VERSION ""

NS_ :

BS_:

BU_: BCMB_AUXM SCMB_PSM HVAC_RCCM SOBDMD_AHCM_FOH TRM GWM _delete RTM PDM SCMH SCMG RSM DDM RGTM DSM GENERIC TSTR

BO_ 798 GatewayData5_MS1: 8 GWM
 SG_ ClrExitAsst_D_Stat_UB : 40|1@0+ (1,0) [0|1] "unitless"  BCMB_AUXM
 SG_ ClrExitAsst_D_Stat : 63|2@0+ (1,0) [0|3] "SED"  BCMB_AUXM
 SG_ ClrExitAsstMsgTxt2_D_Rq_UB : 48|1@0+ (1,0) [0|1] "unitless"  BCMB_AUXM
 SG_ ClrExitAsstMsgTxt2_D_Rq : 52|4@0+ (1,0) [0|15] "SED"  BCMB_AUXM
 SG_ EmPrflNo_D_Rq_UB : 46|1@0+ (1,0) [0|1] "SED"  DDM
 SG_ EmPrflNo_D_Rq : 34|3@0+ (1,0) [0|7] "SED"  DDM
 SG_ EmPrflKeyAssoc_D_Rq_UB : 47|1@0+ (1,0) [0|1] "SED"  DDM
 SG_ EmPrflKeyAssoc_D_Rq : 37|3@0+ (1,0) [0|7] "SED"  DDM
 SG_ BattTracDrvSustn_B_Rq_UB : 42|1@0+ (1,0) [0|1] "SED"  HVAC_RCCM
 SG_ BattTracCool_B_Actl_UB : 44|1@0+ (1,0) [0|1] "SED"  HVAC_RCCM
 SG_ BattTracCool_B_Actl : 45|1@0+ (1,0) [0|1] "SED"  HVAC_RCCM
 SG_ BattTracDrvSustn_B_Rq : 43|1@0+ (1,0) [0|1] "SED"  HVAC_RCCM
 SG_ ExitNotClrRight_B_Stat_UB : 38|1@0+ (1,0) [0|1] "SED" Vector__XXX
 SG_ ExitNotClrLeft_B_Stat_UB : 39|1@0+ (1,0) [0|1] "SED" Vector__XXX
 SG_ ExitNotClrRight_B_Stat : 24|1@0+ (1,0) [0|1] "SED" Vector__XXX
 SG_ ExitNotClrLeft_B_Stat : 25|1@0+ (1,0) [0|1] "SED" Vector__XXX
 SG_ ClimtCool_D_RqPt_UB : 16|1@0+ (1,0) [0|1] "SED"  HVAC_RCCM
 SG_ ClimtCool_D_RqPt : 27|2@0+ (1,0) [0|3] "SED"  HVAC_RCCM
 SG_ PudSptLghtRight_D_Rq_UB : 2|1@0+ (1,0) [0|1] "SED"  DDM,PDM
 SG_ PudSptLghtLeft_D_Rq_UB : 3|1@0+ (1,0) [0|1] "SED"  DDM,PDM
 SG_ PudSptLghtRight_D_Rq : 5|2@0+ (1,0) [0|3] "SED"  DDM,PDM
 SG_ PwRnngBoardPoll_D_Stat_UB : 20|1@0+ (1,0) [0|1] "SED"  DDM,PDM
 SG_ PwRnngBoardPoll_D_Stat : 22|2@0+ (1,0) [0|3] "SED"  DDM,PDM
 SG_ AirCondRec_B_RqVehEl_UB : 18|1@0+ (1,0) [0|1] "SED"  HVAC_RCCM
 SG_ AirCondRec_B_RqVehEl : 19|1@0+ (1,0) [0|1] "SED"  HVAC_RCCM
 SG_ RmtCtl_D_Stat : 31|4@0+ (1,0) [0|15] "SED"  DDM,PDM
 SG_ RmtCtl_D_Stat_UB : 17|1@0+ (1,0) [0|1] "SED"  DDM,PDM
 SG_ PudSptLghtLeft_D_Rq : 7|2@0+ (1,0) [0|3] "SED"  DDM,PDM
 SG_ PoliceDmngLvl_D_Stat : 10|3@0+ (1,0) [0|7] "SED"  DDM,HVAC_RCCM,PDM
 SG_ VehWlcmFrwlMde_D_Stat_UB : 11|1@0+ (1,0) [0|1] "SED"  BCMB_AUXM,DDM,PDM
 SG_ VehWlcmFrwl_D_Stat_UB : 12|1@0+ (1,0) [0|1] "SED"  BCMB_AUXM,DDM,PDM
 SG_ VehWlcmFrwlMde_D_Stat : 15|3@0+ (1,0) [0|7] "SED"  BCMB_AUXM,DDM,PDM
 SG_ VehWlcmFrwl_D_Stat : 1|2@0+ (1,0) [0|3] "SED"  BCMB_AUXM,DDM,PDM
 SG_ PoliceDmngLvl_D_Stat_UB : 23|1@0+ (1,0) [0|1] "SED"  DDM,HVAC_RCCM,PDM

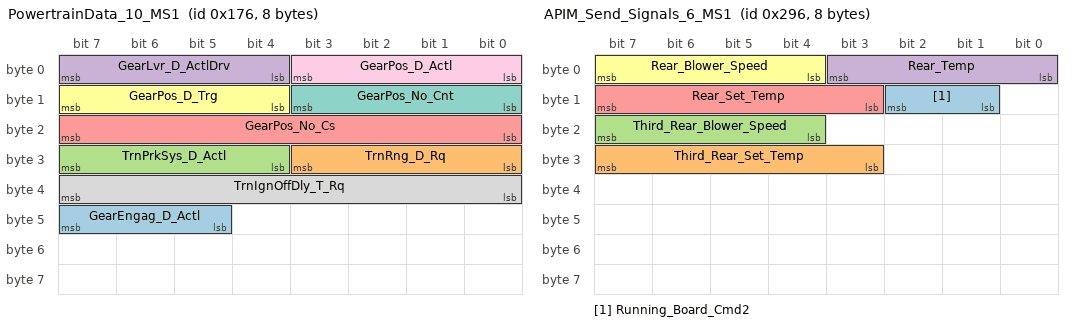
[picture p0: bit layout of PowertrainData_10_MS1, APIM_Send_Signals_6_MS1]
BO_ 374 PowertrainData_10_MS1: 8 GWM
 SG_ GearEngag_D_Actl : 47|3@0+ (1,0) [0|7] "SED"  GENERIC
 SG_ TrnRng_D_Rq : 27|4@0+ (1,0) [0|15] "SED" Vector__XXX
 SG_ TrnPrkSys_D_Actl : 31|4@0+ (1,0) [0|15] "SED" Vector__XXX
 SG_ GearLvr_D_ActlDrv : 7|4@0+ (1,0) [0|15] "SED" Vector__XXX
 SG_ GearPos_No_Cs : 23|8@0+ (1,0) [0|255] "unitless" Vector__XXX
 SG_ GearPos_D_Trg : 15|4@0+ (1,0) [0|15] "SED" Vector__XXX
 SG_ GearPos_No_Cnt : 11|4@0+ (1,0) [0|15] "unitless" Vector__XXX
 SG_ TrnIgnOffDly_T_Rq : 39|8@0+ (4,0) [0|1020] "ms"  GENERIC
 SG_ GearPos_D_Actl : 3|4@0+ (1,0) [0|15] "SED" Vector__XXX

BO_ 662 APIM_Send_Signals_6_MS1: 8 GWM
 SG_ Running_Board_Cmd2 : 10|2@0+ (1,0) [0|3] "SED" Vector__XXX
 SG_ Third_Rear_Set_Temp : 31|5@0+ (1,0) [0|31] "SED" Vector__XXX
 SG_ Third_Rear_Blower_Speed : 23|4@0+ (1,0) [0|15] "SED" Vector__XXX
 SG_ Rear_Temp : 3|4@0+ (1,0) [0|15] "SED" Vector__XXX
 SG_ Rear_Set_Temp : 15|5@0+ (1,0) [0|31] "SED" Vector__XXX
 SG_ Rear_Blower_Speed : 7|4@0+ (1,0) [0|15] "SED" Vector__XXX

BO_ 670 Driver_Dr_Stat2: 8 DDM
 SG_ DrHandleOuterRl_D_Stat : 4|3@0+ (1,0) [0|7] "SED"  GWM
 SG_ DrHandleOuterFl_D_Stat : 7|3@0+ (1,0) [0|7] "SED"  GWM

BO_ 669 Pass_Dr_Stat2: 8 PDM
 SG_ DrHandleOuterRr_D_Stat : 4|3@0+ (1,0) [0|7] "SED"  GWM
 SG_ DrHandleOuterFr_D_Stat : 7|3@0+ (1,0) [0|7] "SED"  GWM

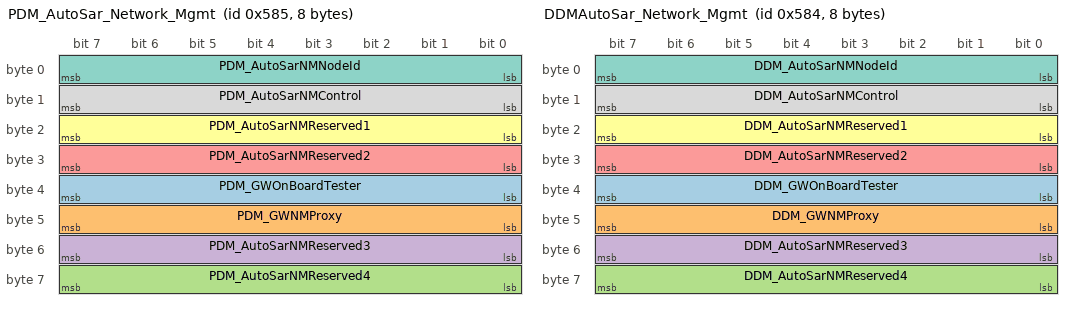
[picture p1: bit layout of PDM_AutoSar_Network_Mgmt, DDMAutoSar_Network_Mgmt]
BO_ 1413 PDM_AutoSar_Network_Mgmt: 8 PDM
 SG_ PDM_GWOnBoardTester : 39|8@0+ (1,0) [0|255] "unitless"  GWM
 SG_ PDM_GWNMProxy : 47|8@0+ (1,0) [0|255] "unitless"  GWM
 SG_ PDM_AutoSarNMReserved4 : 63|8@0+ (1,0) [0|255] "unitless"  GWM
 SG_ PDM_AutoSarNMReserved3 : 55|8@0+ (1,0) [0|255] "unitless"  GWM
 SG_ PDM_AutoSarNMReserved2 : 31|8@0+ (1,0) [0|255] "unitless"  GWM
 SG_ PDM_AutoSarNMReserved1 : 23|8@0+ (1,0) [0|255] "unitless"  GWM
 SG_ PDM_AutoSarNMNodeId : 7|8@0+ (1,0) [0|255] "unitless"  GWM
 SG_ PDM_AutoSarNMControl : 15|8@0+ (1,0) [0|255] "unitless"  GWM

BO_ 1412 DDMAutoSar_Network_Mgmt: 8 DDM
 SG_ DDM_GWOnBoardTester : 39|8@0+ (1,0) [0|255] "unitless"  GWM
 SG_ DDM_GWNMProxy : 47|8@0+ (1,0) [0|255] "unitless"  GWM
 SG_ DDM_AutoSarNMReserved4 : 63|8@0+ (1,0) [0|255] "unitless"  GWM
 SG_ DDM_AutoSarNMReserved3 : 55|8@0+ (1,0) [0|255] "unitless"  GWM
 SG_ DDM_AutoSarNMReserved2 : 31|8@0+ (1,0) [0|255] "unitless"  GWM
 SG_ DDM_AutoSarNMReserved1 : 23|8@0+ (1,0) [0|255] "unitless"  GWM
 SG_ DDM_AutoSarNMNodeId : 7|8@0+ (1,0) [0|255] "unitless"  GWM
 SG_ DDM_AutoSarNMControl : 15|8@0+ (1,0) [0|255] "unitless"  GWM

BO_ 1079 GatewayData2_MS1: 8 GWM
 SG_ ApaMde_D_Stat_UB : 25|1@0+ (1,0) [0|1] "SED" Vector__XXX
 SG_ ApaMde_D_Stat : 39|3@0+ (1,0) [0|7] "SED" Vector__XXX
 SG_ TrlrAidEnbl_D2_Stat_UB : 58|1@0+ (1,0) [0|1] "SED" Vector__XXX
 SG_ TrlrAidEnbl_D2_Stat : 61|3@0+ (1,0) [0|7] "SED" Vector__XXX
 SG_ PoliceAux4Swtch_B_Stat_UB : 62|1@0+ (1,0) [0|1] "SED" Vector__XXX
 SG_ PoliceAux3Swtch_B_Stat_UB : 63|1@0+ (1,0) [0|1] "SED" Vector__XXX
 SG_ PoliceAux2Swtch_B_Stat_UB : 48|1@0+ (1,0) [0|1] "SED" Vector__XXX
 SG_ PoliceAux1Swtch_B_Stat_UB : 49|1@0+ (1,0) [0|1] "SED" Vector__XXX
 SG_ PoliceAux4Swtch_B_Stat : 50|1@0+ (1,0) [0|1] "SED" Vector__XXX
 SG_ PoliceAux3Swtch_B_Stat : 51|1@0+ (1,0) [0|1] "SED" Vector__XXX
 SG_ PoliceAux2Swtch_B_Stat : 52|1@0+ (1,0) [0|1] "SED" Vector__XXX
 SG_ PoliceAux1Swtch_B_Stat : 40|1@0+ (1,0) [0|1] "SED" Vector__XXX
 SG_ GenericSwtch3_No_Actl_UB : 41|1@0+ (1,0) [0|1] "SED" Vector__XXX
 SG_ GenericSwtch3_No_Actl : 55|3@0+ (1,0) [0|7] "unitless" Vector__XXX
 SG_ GenericSwtch2_No_Actl_UB : 32|1@0+ (1,0) [0|1] "SED" Vector__XXX
 SG_ GenericSwtch2_No_Actl : 44|3@0+ (1,0) [0|7] "unitless" Vector__XXX
 SG_ GenericSwtch1_No_Actl_UB : 33|1@0+ (1,0) [0|1] "SED" Vector__XXX
 SG_ GenericSwtch1_No_Actl : 47|3@0+ (1,0) [0|7] "unitless" Vector__XXX
 SG_ RbaSys_D_Stat_UB : 8|1@0+ (1,0) [0|1] "SED" Vector__XXX
 SG_ RbaSys_D_Stat : 4|2@0+ (1,0) [0|3] "SED" Vector__XXX
 SG_ HybMdeStat_D_Dsply_UB : 9|1@0+ (1,0) [0|1] "SED"  HVAC_RCCM
 SG_ Rba_D_Stat : 12|2@0+ (1,0) [0|3] "SED" Vector__XXX
 SG_ Rba_D_Stat_UB : 10|1@0+ (1,0) [0|1] "SED" Vector__XXX
 SG_ BalrMde_D_Rq_UB : 20|1@0+ (1,0) [0|1] "SED" Vector__XXX
 SG_ BalrSwtch_D_Stat_UB : 17|1@0+ (1,0) [0|1] "SED" Vector__XXX
 SG_ BalrMde_D_Rq : 22|2@0+ (1,0) [0|3] "SED" Vector__XXX
 SG_ ChrgGoTTouchEnbl_B_Rq : 1|1@0+ (1,0) [0|1] "SED"  HVAC_RCCM
 SG_ ChrgGoTExtHtrEnbl_B_Rq : 2|1@0+ (1,0) [0|1] "SED"  HVAC_RCCM
 SG_ ChrgGoTTouchEnbl_B_Rq_UB : 23|1@0+ (1,0) [0|1] "SED"  HVAC_RCCM
 SG_ ChrgGoTExtHtrEnbl_B_Rq_UB : 0|1@0+ (1,0) [0|1] "SED"  HVAC_RCCM
 SG_ LcwaAlrtRight_B_Rq_UB : 34|1@0+ (1,0) [0|1] "SED" Vector__XXX
 SG_ LcwaAlrtLeft_B_Rq_UB : 36|1@0+ (1,0) [0|1] "SED" Vector__XXX
 SG_ LcwaAlrtRight_B_Rq : 35|1@0+ (1,0) [0|1] "SED" Vector__XXX
 SG_ LcwaAlrtLeft_B_Rq : 24|1@0+ (1,0) [0|1] "SED" Vector__XXX
 SG_ ApaSteScanMde_D_Stat : 15|2@0+ (1,0) [0|3] "SED" Vector__XXX
 SG_ ApaSteScanMde_D_Stat_UB : 13|1@0+ (1,0) [0|1] "SED" Vector__XXX
 SG_ BattTracClimtDis_B_Stat_UB : 56|1@0+ (1,0) [0|1] "SED"  HVAC_RCCM
 SG_ BattTracClimtDis_B_Stat : 57|1@0+ (1,0) [0|1] "SED"  HVAC_RCCM
 SG_ BalrSwtch_D_Stat : 19|2@0+ (1,0) [0|3] "SED" Vector__XXX
 SG_ TrlrAidMsgTxt_D2_Rq_UB : 16|1@0+ (1,0) [0|1] "SED" Vector__XXX
 SG_ TrlrAidMsgTxt_D2_Rq : 31|6@0+ (1,0) [0|63] "SED" Vector__XXX
 SG_ HybMdeStat_D_Dsply : 7|3@0+ (1,0) [0|7] "SED"  HVAC_RCCM

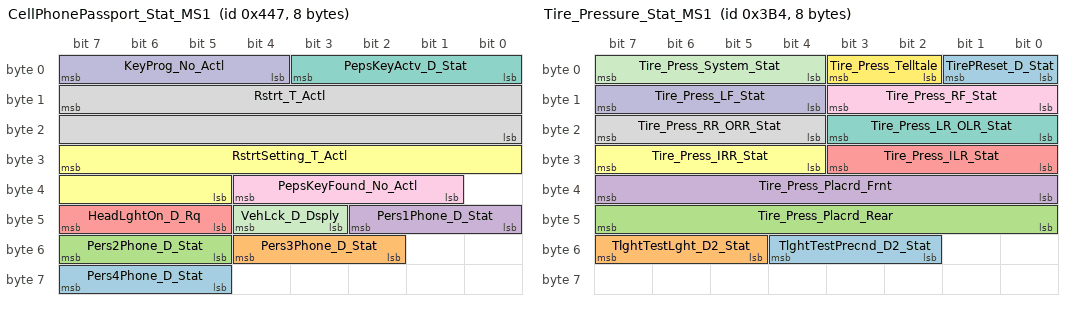
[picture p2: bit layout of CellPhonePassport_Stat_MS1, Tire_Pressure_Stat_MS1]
BO_ 1095 CellPhonePassport_Stat_MS1: 8 GWM
 SG_ Pers4Phone_D_Stat : 63|3@0+ (1,0) [0|7] "SED"  GENERIC
 SG_ Pers3Phone_D_Stat : 52|3@0+ (1,0) [0|7] "SED"  GENERIC
 SG_ Pers2Phone_D_Stat : 55|3@0+ (1,0) [0|7] "SED"  GENERIC
 SG_ Pers1Phone_D_Stat : 42|3@0+ (1,0) [0|7] "SED"  GENERIC
 SG_ HeadLghtOn_D_Rq : 47|3@0+ (1,0) [0|7] "SED" Vector__XXX
 SG_ RstrtSetting_T_Actl : 31|11@0+ (1,0) [0|2047] "second"  RSM
 SG_ PepsKeyActv_D_Stat : 3|4@0+ (1,0) [0|15] "SED"  GENERIC
 SG_ Rstrt_T_Actl : 15|16@0+ (1,0) [0|65535] "seconds"  RSM
 SG_ PepsKeyFound_No_Actl : 36|4@0+ (1,0) [0|15] "unitless"  GENERIC
 SG_ KeyProg_No_Actl : 7|4@0+ (1,0) [0|15] "unitless"  GENERIC
 SG_ VehLck_D_Dsply : 44|2@0+ (1,0) [0|3] "SED" Vector__XXX

BO_ 948 Tire_Pressure_Stat_MS1: 8 GWM
 SG_ TlghtTestPrecnd_D2_Stat : 52|3@0+ (1,0) [0|7] "SED"  GENERIC
 SG_ TlghtTestLght_D2_Stat : 55|3@0+ (1,0) [0|7] "SED"  GENERIC
 SG_ Tire_Press_Placrd_Rear : 47|8@0+ (1,0) [0|255] "pounds/inch^2"  GENERIC
 SG_ Tire_Press_Placrd_Frnt : 39|8@0+ (1,0) [0|255] "pounds/inch^2"  GENERIC
 SG_ Tire_Press_ILR_Stat : 27|4@0+ (1,0) [0|15] "SED"  RTM
 SG_ Tire_Press_IRR_Stat : 31|4@0+ (1,0) [0|15] "SED"  RTM
 SG_ Tire_Press_LR_OLR_Stat : 19|4@0+ (1,0) [0|15] "SED"  RTM
 SG_ Tire_Press_RR_ORR_Stat : 23|4@0+ (1,0) [0|15] "SED"  RTM
 SG_ Tire_Press_RF_Stat : 11|4@0+ (1,0) [0|15] "SED"  RTM
 SG_ Tire_Press_LF_Stat : 15|4@0+ (1,0) [0|15] "SED"  RTM
 SG_ Tire_Press_System_Stat : 7|4@0+ (1,0) [0|15] "SED"  RTM
 SG_ Tire_Press_Telltale : 3|2@0+ (1,0) [0|3] "SED"  RTM
 SG_ TirePReset_D_Stat : 1|2@0+ (1,0) [0|3] "Discrete"  RTM

BO_ 840 FoH_Day_Req_MS1: 8 GWM
 SG_ FohAddHeater_D_Rq : 9|2@0+ (1,0) [0|3] "SED"  SOBDMD_AHCM_FOH
 SG_ FohStrtDateYr_No_Rq : 39|8@0+ (1,2000) [2000|2255] "year"  SOBDMD_AHCM_FOH
 SG_ FohStrtDateDay_No_Rq : 23|16@0+ (1,0) [0|65535] "julian day"  SOBDMD_AHCM_FOH
 SG_ FohT2Friday_T_Rq : 0|1@0+ (1,0) [0|1] "SED"  SOBDMD_AHCM_FOH
 SG_ FohT1Friday_T_Rq : 7|1@0+ (1,0) [0|1] "SED"  SOBDMD_AHCM_FOH
 SG_ FohT2Wednesday_T_Rq : 10|1@0+ (1,0) [0|1] "SED"  SOBDMD_AHCM_FOH
 SG_ FohT2Tuesday_T_Rq : 11|1@0+ (1,0) [0|1] "SED"  SOBDMD_AHCM_FOH
 SG_ FohT2Thursday_T_Rq : 12|1@0+ (1,0) [0|1] "SED"  SOBDMD_AHCM_FOH
 SG_ FohT2Sunday_T_Rq : 13|1@0+ (1,0) [0|1] "SED"  SOBDMD_AHCM_FOH
 SG_ FohT2Saturday_T_Rq : 14|1@0+ (1,0) [0|1] "SED"  SOBDMD_AHCM_FOH
 SG_ FohT2Monday_T_Rq : 15|1@0+ (1,0) [0|1] "SED"  SOBDMD_AHCM_FOH
 SG_ FohT1Wednesday_T_Rq : 1|1@0+ (1,0) [0|1] "SED"  SOBDMD_AHCM_FOH
 SG_ FohT1Tuesday_T_Rq : 2|1@0+ (1,0) [0|1] "SED"  SOBDMD_AHCM_FOH
 SG_ FohT1Thursday_T_Rq : 3|1@0+ (1,0) [0|1] "SED"  SOBDMD_AHCM_FOH
 SG_ FohT1Sunday_T_Rq : 4|1@0+ (1,0) [0|1] "SED"  SOBDMD_AHCM_FOH
 SG_ FohT1Saturday_T_Rq : 5|1@0+ (1,0) [0|1] "SED"  SOBDMD_AHCM_FOH
 SG_ FohT1Monday_T_Rq : 6|1@0+ (1,0) [0|1] "SED"  SOBDMD_AHCM_FOH

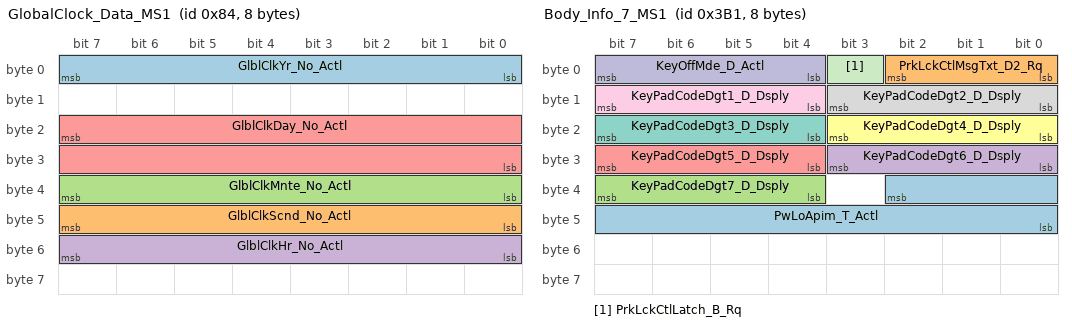
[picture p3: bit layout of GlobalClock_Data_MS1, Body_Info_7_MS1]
BO_ 132 GlobalClock_Data_MS1: 8 GWM
 SG_ GlblClkYr_No_Actl : 7|8@0+ (1,2000) [2000|2255] "year"  TRM,SOBDMD_AHCM_FOH
 SG_ GlblClkScnd_No_Actl : 47|8@0+ (1,0) [0|255] "second"  TRM,SOBDMD_AHCM_FOH
 SG_ GlblClkMnte_No_Actl : 39|8@0+ (1,0) [0|255] "minute"  TRM,SOBDMD_AHCM_FOH
 SG_ GlblClkHr_No_Actl : 55|8@0+ (1,0) [0|255] "hour"  TRM,SOBDMD_AHCM_FOH
 SG_ GlblClkDay_No_Actl : 23|16@0+ (1,0) [0|65535] "julian day"  TRM,SOBDMD_AHCM_FOH

BO_ 945 Body_Info_7_MS1: 8 GWM
 SG_ PwLoApim_T_Actl : 34|11@0+ (1,0) [0|2047] "minute"  GENERIC
 SG_ PrkLckCtlMsgTxt_D2_Rq : 2|3@0+ (1,0) [0|7] "SED"  GENERIC
 SG_ KeyPadCodeDgt7_D_Dsply : 39|4@0+ (1,0) [0|15] "SED"  GENERIC
 SG_ KeyPadCodeDgt6_D_Dsply : 27|4@0+ (1,0) [0|15] "SED"  GENERIC
 SG_ KeyPadCodeDgt5_D_Dsply : 31|4@0+ (1,0) [0|15] "SED"  GENERIC
 SG_ KeyPadCodeDgt4_D_Dsply : 19|4@0+ (1,0) [0|15] "SED"  GENERIC
 SG_ KeyPadCodeDgt3_D_Dsply : 23|4@0+ (1,0) [0|15] "SED"  GENERIC
 SG_ KeyPadCodeDgt2_D_Dsply : 11|4@0+ (1,0) [0|15] "SED"  GENERIC
 SG_ KeyPadCodeDgt1_D_Dsply : 15|4@0+ (1,0) [0|15] "SED"  GENERIC
 SG_ KeyOffMde_D_Actl : 7|4@0+ (1,0) [0|15] "SED"  TRM,SCMB_PSM,PDM,RTM,DDM,DSM,HVAC_RCCM,RGTM
 SG_ PrkLckCtlLatch_B_Rq : 3|1@0+ (1,0) [0|1] "SED"  GENERIC

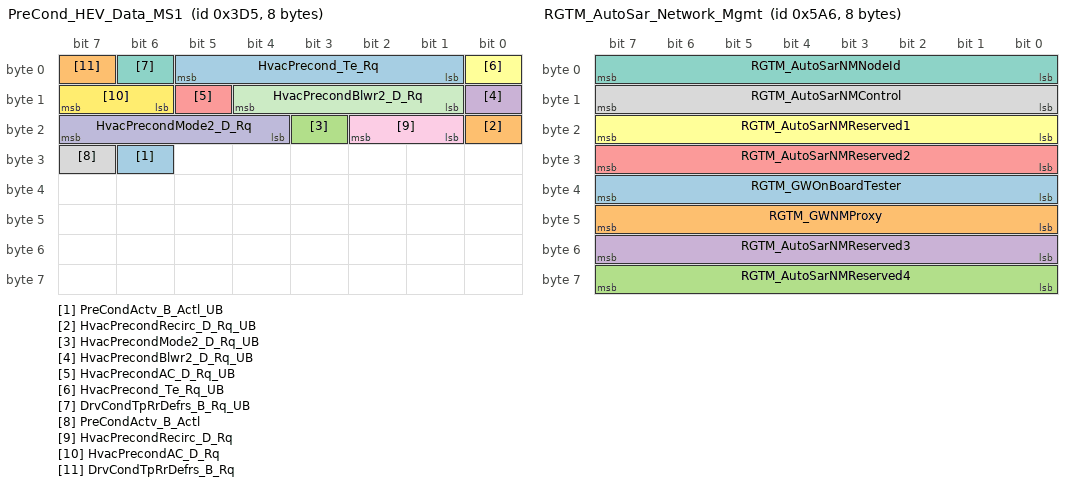
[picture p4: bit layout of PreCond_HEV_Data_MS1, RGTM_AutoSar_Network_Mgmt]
BO_ 981 PreCond_HEV_Data_MS1: 8 GWM
 SG_ PreCondActv_B_Actl_UB : 30|1@0+ (1,0) [0|1] "SED"  HVAC_RCCM,GENERIC
 SG_ HvacPrecondRecirc_D_Rq_UB : 16|1@0+ (1,0) [0|1] "SED"  GENERIC,HVAC_RCCM
 SG_ HvacPrecondMode2_D_Rq_UB : 19|1@0+ (1,0) [0|1] "SED"  GENERIC,HVAC_RCCM
 SG_ HvacPrecondBlwr2_D_Rq_UB : 8|1@0+ (1,0) [0|1] "SED"  HVAC_RCCM,GENERIC
 SG_ HvacPrecondAC_D_Rq_UB : 13|1@0+ (1,0) [0|1] "SED"  GENERIC,HVAC_RCCM
 SG_ HvacPrecond_Te_Rq_UB : 0|1@0+ (1,0) [0|1] "SED"  GENERIC,HVAC_RCCM
 SG_ DrvCondTpRrDefrs_B_Rq_UB : 6|1@0+ (1,0) [0|1] "SED"  HVAC_RCCM,GENERIC
 SG_ PreCondActv_B_Actl : 31|1@0+ (1,0) [0|1] "SED"  GENERIC,HVAC_RCCM
 SG_ HvacPrecondRecirc_D_Rq : 18|2@0+ (1,0) [0|3] "SED"  GENERIC,HVAC_RCCM
 SG_ HvacPrecondMode2_D_Rq : 23|4@0+ (1,0) [0|15] "SED"  GENERIC,HVAC_RCCM
 SG_ HvacPrecondBlwr2_D_Rq : 12|4@0+ (1,0) [0|15] "SED"  GENERIC,HVAC_RCCM
 SG_ HvacPrecondAC_D_Rq : 15|2@0+ (1,0) [0|3] "SED"  GENERIC,HVAC_RCCM
 SG_ HvacPrecond_Te_Rq : 5|5@0+ (0.5,14.5) [14.5|30] "deg C"  GENERIC,HVAC_RCCM
 SG_ DrvCondTpRrDefrs_B_Rq : 7|1@0+ (1,0) [0|1] "SED"  HVAC_RCCM,GENERIC

BO_ 1446 RGTM_AutoSar_Network_Mgmt: 8 RGTM
 SG_ RGTM_GWOnBoardTester : 39|8@0+ (1,0) [0|255] "unitless"  DDM,GWM
 SG_ RGTM_GWNMProxy : 47|8@0+ (1,0) [0|255] "unitless"  DDM,GWM
 SG_ RGTM_AutoSarNMReserved4 : 63|8@0+ (1,0) [0|255] "unitless"  DDM,GWM
 SG_ RGTM_AutoSarNMReserved3 : 55|8@0+ (1,0) [0|255] "unitless"  DDM,GWM
 SG_ RGTM_AutoSarNMReserved2 : 31|8@0+ (1,0) [0|255] "unitless"  DDM,GWM
 SG_ RGTM_AutoSarNMReserved1 : 23|8@0+ (1,0) [0|255] "unitless"  DDM,GWM
 SG_ RGTM_AutoSarNMNodeId : 7|8@0+ (1,0) [0|255] "unitless"  DDM,GWM
 SG_ RGTM_AutoSarNMControl : 15|8@0+ (1,0) [0|255] "unitless"  DDM,GWM

BO_ 839 FuelOpHeater_Stat: 8 SOBDMD_AHCM_FOH
 SG_ FohStop_B_Stat : 49|2@0+ (1,0) [0|3] "SED"  GWM
 SG_ FohMsgTxt_D_Rq : 4|3@0+ (1,0) [0|7] "SED"  GWM
 SG_ FohKeyOff_B_Rq : 6|1@0+ (1,0) [0|1] "SED"  GWM
 SG_ FohEnbl_B_Rq : 7|1@0+ (1,0) [0|1] "SED"  GWM
 SG_ FohTAllEnable_B_Stat : 17|2@0+ (1,0) [0|3] "SED"  GWM
 SG_ FohT2Mnte_T_Stat : 55|6@0+ (1,0) [0|63] "minute"  GWM
 SG_ FohT2Hr_T_Stat : 47|5@0+ (1,0) [0|31] "hour"  GWM
 SG_ FohT2Enable_B_Stat : 63|1@0+ (1,0) [0|1] "SED"  GWM
 SG_ FohT1Mnte_T_Stat : 39|6@0+ (1,0) [0|63] "minute"  GWM
 SG_ FohT1Hr_T_Stat : 31|5@0+ (1,0) [0|31] "hour"  GWM
 SG_ FohT1Enable_B_Stat : 0|1@0+ (1,0) [0|1] "SED"  GWM
 SG_ FohStrtMnte_T_Stat : 23|6@0+ (1,0) [0|63] "minute"  GWM
 SG_ FohStrtHr_T_Stat : 15|5@0+ (1,0) [0|31] "hour"  GWM
 SG_ FohStrtEnable_B_Stat : 1|1@0+ (1,0) [0|1] "SED"  GWM
 SG_ FohContOn_B_Stat : 33|2@0+ (1,0) [0|3] "SED"  GWM
 SG_ FohT2Wednesday_T_Stat : 56|1@0+ (1,0) [0|1] "SED"  GWM
 SG_ FohT2Tuesday_T_Stat : 57|1@0+ (1,0) [0|1] "SED"  GWM
 SG_ FohT2Thursday_T_Stat : 58|1@0+ (1,0) [0|1] "SED"  GWM
 SG_ FohT2Sunday_T_Stat : 59|1@0+ (1,0) [0|1] "SED"  GWM
 SG_ FohT2Saturday_T_Stat : 60|1@0+ (1,0) [0|1] "SED"  GWM
 SG_ FohT2Monday_T_Stat : 61|1@0+ (1,0) [0|1] "SED"  GWM
 SG_ FohT2Friday_T_Stat : 62|1@0+ (1,0) [0|1] "SED"  GWM
 SG_ FohT1Wednesday_T_Stat : 40|1@0+ (1,0) [0|1] "SED"  GWM
 SG_ FohT1Tuesday_T_Stat : 41|1@0+ (1,0) [0|1] "SED"  GWM
 SG_ FohT1Thursday_T_Stat : 42|1@0+ (1,0) [0|1] "SED"  GWM
 SG_ FohT1Sunday_T_Stat : 24|1@0+ (1,0) [0|1] "SED"  GWM
 SG_ FohT1Saturday_T_Stat : 25|1@0+ (1,0) [0|1] "SED"  GWM
 SG_ FohT1Monday_T_Stat : 26|1@0+ (1,0) [0|1] "SED"  GWM
 SG_ FohT1Friday_T_Stat : 5|1@0+ (1,0) [0|1] "SED"  GWM

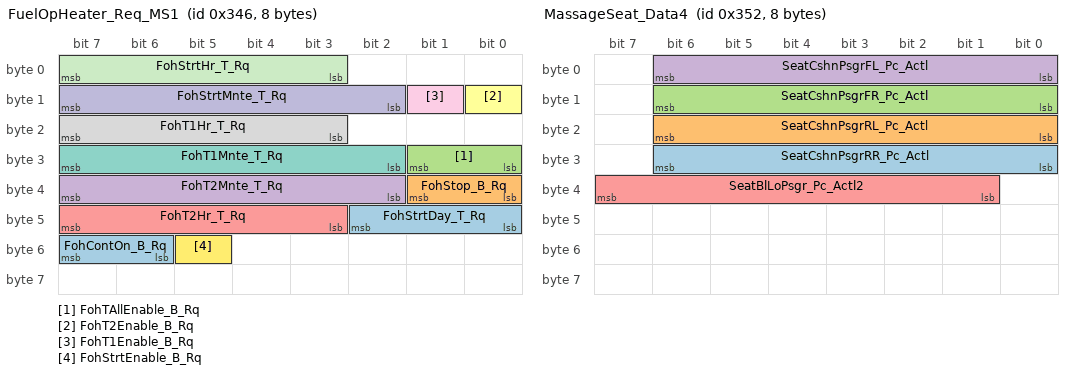
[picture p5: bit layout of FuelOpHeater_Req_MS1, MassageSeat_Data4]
BO_ 838 FuelOpHeater_Req_MS1: 8 GWM
 SG_ FohStrtDay_T_Rq : 42|3@0+ (1,0) [0|7] "SED" Vector__XXX
 SG_ FohStop_B_Rq : 33|2@0+ (1,0) [0|3] "SED"  SOBDMD_AHCM_FOH
 SG_ FohTAllEnable_B_Rq : 25|2@0+ (1,0) [0|3] "SED"  SOBDMD_AHCM_FOH
 SG_ FohT2Mnte_T_Rq : 39|6@0+ (1,0) [0|63] "minute"  SOBDMD_AHCM_FOH
 SG_ FohT2Hr_T_Rq : 47|5@0+ (1,0) [0|31] "hour"  SOBDMD_AHCM_FOH
 SG_ FohT2Enable_B_Rq : 8|1@0+ (1,0) [0|1] "SED"  SOBDMD_AHCM_FOH
 SG_ FohT1Mnte_T_Rq : 31|6@0+ (1,0) [0|63] "minute"  SOBDMD_AHCM_FOH
 SG_ FohT1Hr_T_Rq : 23|5@0+ (1,0) [0|31] "hour"  SOBDMD_AHCM_FOH
 SG_ FohT1Enable_B_Rq : 9|1@0+ (1,0) [0|1] "SED"  SOBDMD_AHCM_FOH
 SG_ FohStrtMnte_T_Rq : 15|6@0+ (1,0) [0|63] "minute"  SOBDMD_AHCM_FOH
 SG_ FohStrtHr_T_Rq : 7|5@0+ (1,0) [0|31] "hour"  SOBDMD_AHCM_FOH
 SG_ FohStrtEnable_B_Rq : 53|1@0+ (1,0) [0|1] "SED"  SOBDMD_AHCM_FOH
 SG_ FohContOn_B_Rq : 55|2@0+ (1,0) [0|3] "SED"  SOBDMD_AHCM_FOH

BO_ 850 MassageSeat_Data4: 8 SCMH
 SG_ SeatCshnPsgrRR_Pc_Actl : 30|7@0+ (1,0) [0|126] "Percent"  GWM
 SG_ SeatCshnPsgrRL_Pc_Actl : 22|7@0+ (1,0) [0|126] "Percent"  GWM
 SG_ SeatCshnPsgrFR_Pc_Actl : 14|7@0+ (1,0) [0|126] "Percent"  GWM
 SG_ SeatCshnPsgrFL_Pc_Actl : 6|7@0+ (1,0) [0|126] "Percent"  GWM
 SG_ SeatBlLoPsgr_Pc_Actl2 : 39|7@0+ (1,0) [0|126] "Percent"  GWM

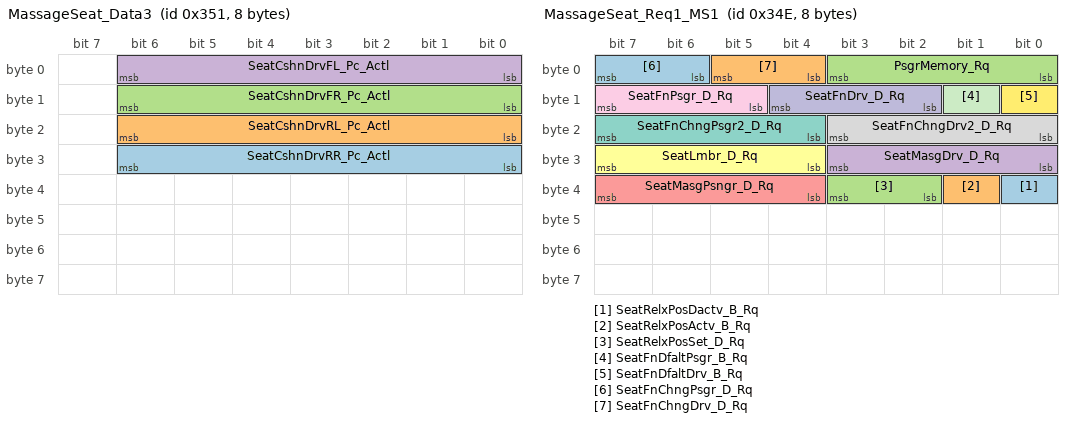
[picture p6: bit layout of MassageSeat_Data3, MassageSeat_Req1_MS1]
BO_ 849 MassageSeat_Data3: 8 SCMG
 SG_ SeatCshnDrvRR_Pc_Actl : 30|7@0+ (1,0) [0|126] "Percent"  GWM
 SG_ SeatCshnDrvRL_Pc_Actl : 22|7@0+ (1,0) [0|126] "Percent"  GWM
 SG_ SeatCshnDrvFR_Pc_Actl : 14|7@0+ (1,0) [0|126] "Percent"  GWM
 SG_ SeatCshnDrvFL_Pc_Actl : 6|7@0+ (1,0) [0|126] "Percent"  GWM

BO_ 846 MassageSeat_Req1_MS1: 8 GWM
 SG_ SeatRelxPosDactv_B_Rq : 32|1@0+ (1,0) [0|1] "SED" Vector__XXX
 SG_ SeatRelxPosActv_B_Rq : 33|1@0+ (1,0) [0|1] "SED" Vector__XXX
 SG_ SeatRelxPosSet_D_Rq : 35|2@0+ (1,0) [0|3] "SED" Vector__XXX
 SG_ SeatMasgDrv_D_Rq : 27|4@0+ (1,0) [0|15] "SED"  SCMG
 SG_ SeatMasgPsngr_D_Rq : 39|4@0+ (1,0) [0|15] "SED"  SCMH
 SG_ SeatLmbr_D_Rq : 31|4@0+ (1,0) [0|15] "SED"  SCMB_PSM,DSM
 SG_ SeatFnChngPsgr2_D_Rq : 23|4@0+ (1,0) [0|15] "SED"  SCMG,SCMH
 SG_ SeatFnChngDrv2_D_Rq : 19|4@0+ (1,0) [0|15] "SED"  SCMG,SCMH
 SG_ SeatFnPsgr_D_Rq : 15|3@0+ (1,0) [0|7] "SED"  SCMH,SCMG
 SG_ SeatFnDrv_D_Rq : 12|3@0+ (1,0) [0|7] "SED"  SCMH,SCMG
 SG_ SeatFnDfaltPsgr_B_Rq : 9|1@0+ (1,0) [0|1] "SED"  SCMH,SCMG
 SG_ SeatFnDfaltDrv_B_Rq : 8|1@0+ (1,0) [0|1] "SED"  SCMH,SCMG
 SG_ SeatFnChngPsgr_D_Rq : 7|2@0+ (1,0) [0|3] "SED"  SCMH,SCMG
 SG_ SeatFnChngDrv_D_Rq : 5|2@0+ (1,0) [0|3] "SED"  SCMH,SCMG
 SG_ PsgrMemory_Rq : 3|4@0+ (1,0) [0|15] "SED"  SCMH,SCMG

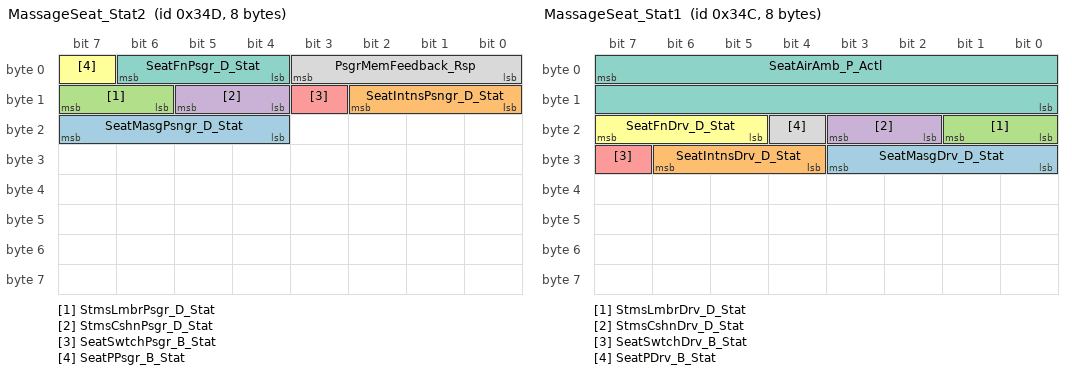
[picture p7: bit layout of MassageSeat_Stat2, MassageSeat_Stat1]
BO_ 845 MassageSeat_Stat2: 8 SCMH
 SG_ SeatMasgPsngr_D_Stat : 23|4@0+ (1,0) [0|15] "SED"  GWM
 SG_ SeatIntnsPsngr_D_Stat : 10|3@0+ (1,0) [0|7] "SED"  GWM
 SG_ StmsLmbrPsgr_D_Stat : 15|2@0+ (1,0) [0|3] "SED"  GWM
 SG_ StmsCshnPsgr_D_Stat : 13|2@0+ (1,0) [0|3] "SED"  GWM
 SG_ SeatSwtchPsgr_B_Stat : 11|1@0+ (1,0) [0|1] "SED"  GWM
 SG_ SeatPPsgr_B_Stat : 7|1@0+ (1,0) [0|1] "SED"  GWM
 SG_ SeatFnPsgr_D_Stat : 6|3@0+ (1,0) [0|7] "SED"  GWM
 SG_ PsgrMemFeedback_Rsp : 3|4@0+ (1,0) [0|15] "SED"  GWM

BO_ 844 MassageSeat_Stat1: 8 SCMG
 SG_ SeatMasgDrv_D_Stat : 27|4@0+ (1,0) [0|15] "SED"  GWM
 SG_ SeatIntnsDrv_D_Stat : 30|3@0+ (1,0) [0|7] "SED"  GWM
 SG_ StmsLmbrDrv_D_Stat : 17|2@0+ (1,0) [0|3] "SED"  GWM
 SG_ StmsCshnDrv_D_Stat : 19|2@0+ (1,0) [0|3] "SED"  GWM
 SG_ SeatSwtchDrv_B_Stat : 31|1@0+ (1,0) [0|1] "SED"  GWM
 SG_ SeatFnDrv_D_Stat : 23|3@0+ (1,0) [0|7] "SED"  GWM
 SG_ SeatAirAmb_P_Actl : 7|16@0+ (0.01,0) [0|655.35] "KiloPascal"  GWM,SCMH
 SG_ SeatPDrv_B_Stat : 20|1@0+ (1,0) [0|1] "SED"  GWM

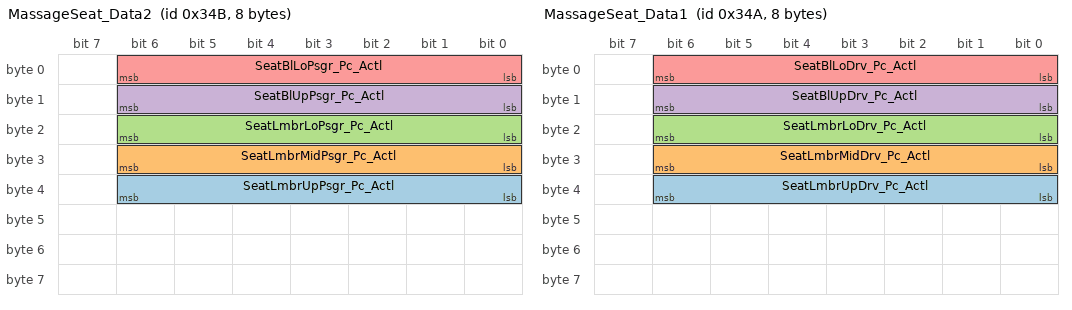
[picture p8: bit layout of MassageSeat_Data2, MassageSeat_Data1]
BO_ 843 MassageSeat_Data2: 8 SCMH
 SG_ SeatLmbrUpPsgr_Pc_Actl : 38|7@0+ (1,0) [0|127] "Percent"  GWM
 SG_ SeatLmbrMidPsgr_Pc_Actl : 30|7@0+ (1,0) [0|127] "Percent"  GWM
 SG_ SeatLmbrLoPsgr_Pc_Actl : 22|7@0+ (1,0) [0|127] "Percent"  GWM
 SG_ SeatBlUpPsgr_Pc_Actl : 14|7@0+ (1,0) [0|126] "Percent"  GWM
 SG_ SeatBlLoPsgr_Pc_Actl : 6|7@0+ (1,0) [0|126] "Percent"  GWM

BO_ 842 MassageSeat_Data1: 8 SCMG
 SG_ SeatLmbrUpDrv_Pc_Actl : 38|7@0+ (1,0) [0|127] "Percent"  GWM
 SG_ SeatLmbrMidDrv_Pc_Actl : 30|7@0+ (1,0) [0|127] "Percent"  GWM
 SG_ SeatLmbrLoDrv_Pc_Actl : 22|7@0+ (1,0) [0|127] "Percent"  GWM
 SG_ SeatBlUpDrv_Pc_Actl : 14|7@0+ (1,0) [0|126] "Percent"  GWM
 SG_ SeatBlLoDrv_Pc_Actl : 6|7@0+ (1,0) [0|126] "Percent"  GWM

BO_ 1994 TesterPhysicalResRSM: 8 RSM
 SG_ TesterPhysicalResRSM : 7|64@0+ (1,0) [0|1.84467E+019] "unitless"  TSTR

BO_ 1986 TesterPhysicalReqRSM: 8 TSTR
 SG_ TesterPhysicalReqRSM : 7|64@0+ (1,0) [0|1.84467E+019] "unitless"  RSM

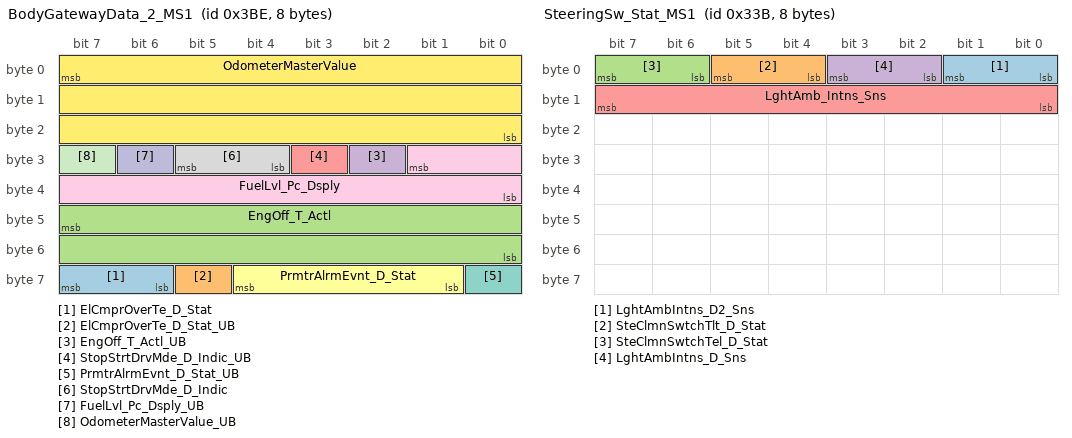
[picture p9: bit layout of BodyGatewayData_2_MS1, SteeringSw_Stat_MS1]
BO_ 958 BodyGatewayData_2_MS1: 8 GWM
 SG_ ElCmprOverTe_D_Stat : 63|2@0+ (1,0) [0|3] "SED"  HVAC_RCCM
 SG_ ElCmprOverTe_D_Stat_UB : 61|1@0+ (1,0) [0|1] "SED"  HVAC_RCCM
 SG_ EngOff_T_Actl : 47|16@0+ (1,0) [0|65534] "second^0.5"  HVAC_RCCM
 SG_ EngOff_T_Actl_UB : 26|1@0+ (1,0) [0|1] "SED"  HVAC_RCCM
 SG_ StopStrtDrvMde_D_Indic_UB : 27|1@0+ (1,0) [0|1] "SED"  HVAC_RCCM
 SG_ PrmtrAlrmEvnt_D_Stat : 60|4@0+ (1,0) [0|15] "SED"  RSM
 SG_ PrmtrAlrmEvnt_D_Stat_UB : 56|1@0+ (1,0) [0|1] "SED"  RSM
 SG_ StopStrtDrvMde_D_Indic : 29|2@0+ (1,0) [0|3] "SED"  HVAC_RCCM
 SG_ FuelLvl_Pc_Dsply : 25|10@0+ (0.108696,-5.217408) [-5.217408|105.9786] "Percent"  SOBDMD_AHCM_FOH
 SG_ FuelLvl_Pc_Dsply_UB : 30|1@0+ (1,0) [0|1] "SED"  SOBDMD_AHCM_FOH
 SG_ OdometerMasterValue_UB : 31|1@0+ (1,0) [0|1] "SED"  HVAC_RCCM,RGTM
 SG_ OdometerMasterValue : 7|24@0+ (1,0) [0|16777214] "km"  HVAC_RCCM,RGTM

BO_ 827 SteeringSw_Stat_MS1: 8 GWM
 SG_ LghtAmbIntns_D2_Sns : 1|2@0+ (1,0) [0|3] "SED"  GENERIC
 SG_ SteClmnSwtchTlt_D_Stat : 5|2@0+ (1,0) [0|3] "SED"  DSM
 SG_ SteClmnSwtchTel_D_Stat : 7|2@0+ (1,0) [0|3] "SED"  DSM
 SG_ LghtAmbIntns_D_Sns : 3|2@0+ (1,0) [0|3] "SED"  GENERIC
 SG_ LghtAmb_Intns_Sns : 15|8@0+ (1,0) [0|255] "unitless"  GENERIC

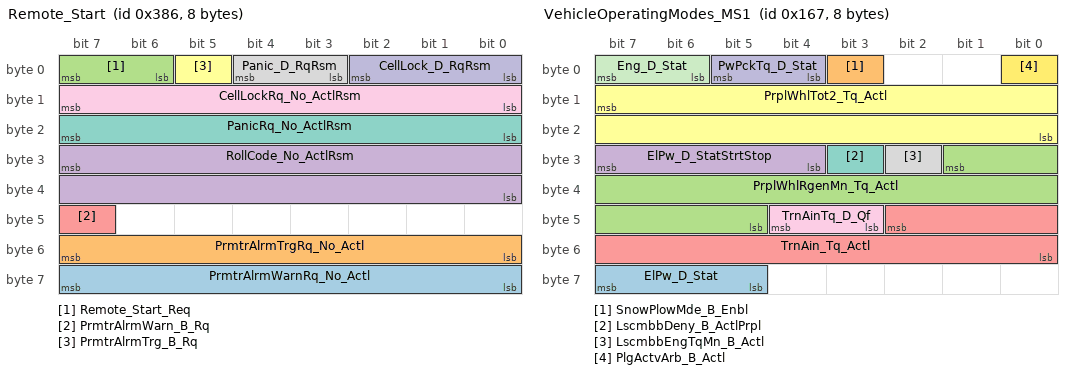
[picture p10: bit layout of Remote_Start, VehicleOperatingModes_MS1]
BO_ 902 Remote_Start: 8 RSM
 SG_ PrmtrAlrmWarnRq_No_Actl : 63|8@0+ (1,0) [0|255] "unitless"  GWM
 SG_ PrmtrAlrmTrgRq_No_Actl : 55|8@0+ (1,0) [0|255] "unitless"  GWM
 SG_ Remote_Start_Req : 7|2@0+ (1,0) [0|3] "SED"  GWM
 SG_ RollCode_No_ActlRsm : 31|16@0+ (1,0) [0|65535] "unitless"  GWM
 SG_ PrmtrAlrmWarn_B_Rq : 47|1@0+ (1,0) [0|1] "SED"  GWM
 SG_ PrmtrAlrmTrg_B_Rq : 5|1@0+ (1,0) [0|1] "SED"  GWM
 SG_ PanicRq_No_ActlRsm : 23|8@0+ (1,0) [0|255] "unitless"  GWM
 SG_ Panic_D_RqRsm : 4|2@0+ (1,0) [0|3] "SED"  GWM
 SG_ CellLockRq_No_ActlRsm : 15|8@0+ (1,0) [0|255] "unitless"  GWM
 SG_ CellLock_D_RqRsm : 2|3@0+ (1,0) [0|7] "SED"  GWM

BO_ 765 GatewayData_MS1: 8 GWM
 SG_ CcStat_D_Actl_UB : 48|1@0+ (1,0) [0|1] "SED"  HVAC_RCCM
 SG_ CcStat_D_Actl : 51|3@0+ (1,0) [0|7] "SED"  HVAC_RCCM
 SG_ PrplTqMnSat_B_Actl_UB : 52|1@0+ (1,0) [0|1] "SED"  HVAC_RCCM
 SG_ PrplTqMnSat_B_Actl : 53|1@0+ (1,0) [0|1] "SED"  HVAC_RCCM
 SG_ ClimtBlwrLim_B_Rq : 61|1@0+ (1,0) [0|1] "SED"  HVAC_RCCM
 SG_ ClimtBlwrLim_B_Rq_UB : 60|1@0+ (1,0) [0|1] "SED"  HVAC_RCCM
 SG_ TrlrBrkActCnnct_B_Actl_UB : 62|1@0+ (1,0) [0|1] "SED" Vector__XXX
 SG_ TrlrBrkActCnnct_B_Actl : 63|1@0+ (1,0) [0|1] "SED" Vector__XXX
 SG_ EmPrflButtnAssoc_D_Rq : 17|2@0+ (1,0) [0|3] "SED"  DSM
 SG_ EmPrflButtnAssoc_D_Rq_UB : 56|1@0+ (1,0) [0|1] "SED"  DSM
 SG_ CamraFrntStat_D_Stat_UB : 32|1@0+ (1,0) [0|1] "SED"  HVAC_RCCM
 SG_ CamraFrntStat_D_Stat : 34|2@0+ (1,0) [0|3] "SED"  HVAC_RCCM
 SG_ AutoHoldSwMde_B_Ind_UB : 46|1@0+ (1,0) [0|1] "SED"  HVAC_RCCM
 SG_ AutoHoldSwMde_B_Ind : 47|1@0+ (1,0) [0|1] "SED"  HVAC_RCCM
 SG_ ValetMode_D_Stat_UB : 35|1@0+ (1,0) [0|1] "SED"  DSM
 SG_ ValetMode_D_Stat : 25|2@0+ (1,0) [0|3] "SED"  DSM
 SG_ SteWhlHeat_D_Stat : 39|4@0+ (1,0) [0|15] "SED"  HVAC_RCCM
 SG_ Running_Board_Cmd_UB : 27|1@0+ (1,0) [0|1] "SED" Vector__XXX
 SG_ Running_Board_Cmd : 29|2@0+ (1,0) [0|3] "SED" Vector__XXX
 SG_ Bezel_Beeps_Rq_UB : 18|1@0+ (1,0) [0|1] "SED" Vector__XXX
 SG_ Bezel_Beeps_Rq : 20|2@0+ (1,0) [0|3] "SED" Vector__XXX
 SG_ Diagnostic_Operation_Rq_UB : 21|1@0+ (1,0) [0|1] "SED"  HVAC_RCCM
 SG_ Bezel_Diag_State_Rq_UB : 23|1@0+ (1,0) [0|1] "SED" Vector__XXX
 SG_ Bezel_Diag_Module_Rq_UB : 22|1@0+ (1,0) [0|1] "SED" Vector__XXX
 SG_ Diagnostic_Operation_Rq : 11|4@0+ (1,0) [0|15] "SED"  HVAC_RCCM
 SG_ Bezel_Diag_State_Rq : 1|2@0+ (1,0) [0|3] "SED" Vector__XXX
 SG_ Bezel_Diag_Module_Rq : 15|4@0+ (1,0) [0|15] "SED" Vector__XXX
 SG_ HMI_HMIMode_St_UB : 2|1@0+ (1,0) [0|1] "SED"  DDM,PDM,HVAC_RCCM,RGTM
 SG_ HMI_HMIMode_St : 5|3@0+ (1,0) [0|7] "SED"  DDM,PDM,HVAC_RCCM,RGTM
 SG_ Mc_VehUnitTempUsrSel_St_UB : 6|1@0+ (1,0) [0|1] "SED"  HVAC_RCCM
 SG_ Mc_VehUnitTempUsrSel_St : 7|1@0+ (1,0) [0|1] "SED"  HVAC_RCCM
 SG_ PsngrFrntDetct_D_Actl_UB : 40|1@0+ (1,0) [0|1] "SED"  HVAC_RCCM
 SG_ PsngrFrntDetct_D_Actl : 55|2@0+ (1,0) [0|3] "SED"  HVAC_RCCM
 SG_ SteWhlHeat_D_Stat_UB : 26|1@0+ (1,0) [0|1] "SED"  HVAC_RCCM
 SG_ PrkAidLamp_D_Rq : 43|2@0+ (1,0) [0|3] "SED"  GENERIC
 SG_ PrkAidLamp_D_Rq_UB : 41|1@0+ (1,0) [0|1] "SED"  GENERIC
 SG_ ParkDetect_Stat_UB : 30|1@0+ (1,0) [0|1] "SED"  RSM
 SG_ ParkDetect_Stat : 31|1@0+ (1,0) [0|1] "SED"  RSM
 SG_ Voice_Blower_Limit : 45|1@0+ (1,0) [0|1] "SED"  GENERIC,HVAC_RCCM
 SG_ Voice_Blower_Limit_UB : 44|1@0+ (1,0) [0|1] "SED"  GENERIC,HVAC_RCCM
 SG_ PwStep_D_DrvInhbt_UB : 57|1@0+ (1,0) [0|1] "SED" Vector__XXX
 SG_ PwStep_D_DrvInhbt : 59|2@0+ (1,0) [0|3] "SED" Vector__XXX

BO_ 556 BCP_Status_Message: 8 HVAC_RCCM
 SG_ Manual_Temp_Setting : 23|5@0+ (1,0) [0|31] "SED"  GWM

BO_ 1815 TesterPhysicalReqRLCMA: 8 TSTR
 SG_ TesterPhysicalReqRLCMA : 7|64@0+ (1,0) [0|1.84467E+019] "unitless"  GENERIC

BO_ 359 VehicleOperatingModes_MS1: 8 GWM
 SG_ ElPw_D_Stat : 63|3@0+ (1,0) [0|7] "SED"  SCMB_PSM,RGTM,HVAC_RCCM,TRM,DSM,SCMH
 SG_ SnowPlowMde_B_Enbl : 3|1@0+ (1,0) [0|1] "SED"  SCMH,SCMG
 SG_ PrplWhlRgenMn_Tq_Actl : 25|13@0+ (4,-16380) [-16380|16380] "Nm"  GENERIC
 SG_ ElPw_D_StatStrtStop : 31|4@0+ (1,0) [0|15] "SED"  GENERIC
 SG_ TrnAin_Tq_Actl : 42|11@0+ (1,-500) [-500|1547] "Nm"  GENERIC
 SG_ PrplWhlTot2_Tq_Actl : 15|16@0+ (4,-131072) [-131072|131060] "Nm"  GENERIC
 SG_ LscmbbDeny_B_ActlPrpl : 27|1@0+ (1,0) [0|1] "SED"  GENERIC
 SG_ LscmbbEngTqMn_B_Actl : 26|1@0+ (1,0) [0|1] "SED"  GENERIC
 SG_ TrnAinTq_D_Qf : 44|2@0+ (1,0) [0|3] "SED"  GENERIC
 SG_ PwPckTq_D_Stat : 5|2@0+ (1,0) [0|3] "SED"  SCMB_PSM,HVAC_RCCM,RSM,TRM,SCMH,SCMG,RTM,RGTM,PDM,DSM,DDM
 SG_ Eng_D_Stat : 7|2@0+ (1,0) [0|3] "SED"  BCMB_AUXM,TRM,HVAC_RCCM,SOBDMD_AHCM_FOH
 SG_ PlgActvArb_B_Actl : 0|1@0+ (1,0) [0|1] "SED"  GENERIC

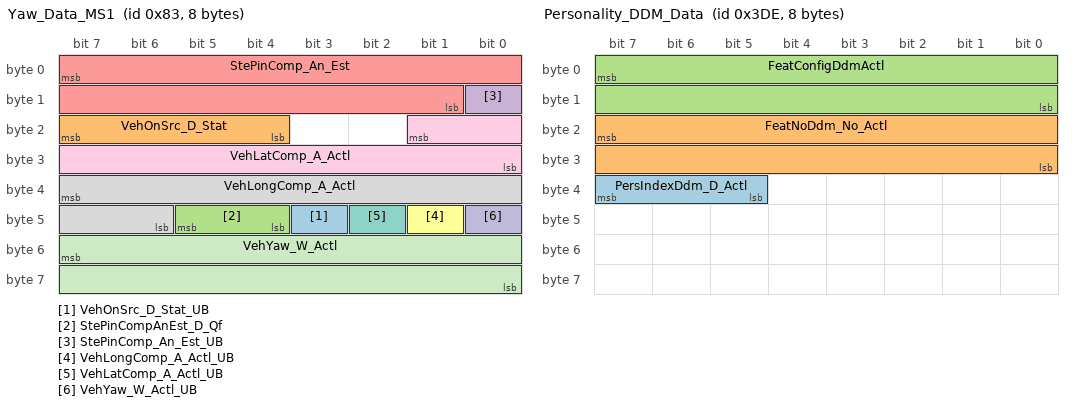
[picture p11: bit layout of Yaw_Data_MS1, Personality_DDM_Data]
BO_ 131 Yaw_Data_MS1: 8 GWM
 SG_ VehOnSrc_D_Stat_UB : 43|1@0+ (1,0) [0|1] "SED"  DDM,PDM
 SG_ VehOnSrc_D_Stat : 23|4@0+ (1,0) [0|15] "SED"  DDM,PDM
 SG_ StePinCompAnEst_D_Qf : 45|2@0+ (1,0) [0|3] "SED"  GENERIC
 SG_ StePinComp_An_Est_UB : 8|1@0+ (1,0) [0|1] "SED"  GENERIC
 SG_ StePinComp_An_Est : 7|15@0+ (0.1,-1600) [-1600|1676.7] "degrees"  GENERIC
 SG_ VehLongComp_A_Actl_UB : 41|1@0+ (1,0) [0|1] "SED"  RGTM
 SG_ VehLatComp_A_Actl_UB : 42|1@0+ (1,0) [0|1] "SED"  RGTM
 SG_ VehLongComp_A_Actl : 39|10@0+ (0.035,-17.9) [-17.9|17.835] "m/s^2"  RGTM
 SG_ VehLatComp_A_Actl : 17|10@0+ (0.035,-17.9) [-17.9|17.835] "m/s^2"  RGTM
 SG_ VehYaw_W_Actl_UB : 40|1@0+ (1,0) [0|1] "SED"  GENERIC
 SG_ VehYaw_W_Actl : 55|16@0+ (0.0002,-6.5) [-6.5|6.6066] "rad/s"  GENERIC

BO_ 990 Personality_DDM_Data: 8 DDM
 SG_ PersIndexDdm_D_Actl : 39|3@0+ (1,0) [0|7] "SED"  GWM
 SG_ FeatNoDdm_No_Actl : 23|16@0+ (1,0) [0|65535] "Number"  GWM
 SG_ FeatConfigDdmActl : 7|16@0+ (1,0) [0|65535] "Undefined"  GWM

BO_ 1246 TrailerBrakeCtl_Data_MS1: 8 TRM

BO_ 1003 Personality_BCM2_Data_MS1: 8 GWM
 SG_ TailLghtLoadMde_D_Stat : 60|3@0+ (1,0) [0|7] "SED"  GENERIC
 SG_ Pers4Key_D_Stat : 49|2@0+ (1,0) [0|3] "SED"  GENERIC
 SG_ Pers3Key_D_Stat : 41|2@0+ (1,0) [0|3] "SED"  GENERIC
 SG_ Pers2Key_D_Stat : 43|2@0+ (1,0) [0|3] "SED"  GENERIC
 SG_ Pers1Key_D_Stat : 12|2@0+ (1,0) [0|3] "SED"  GENERIC
 SG_ EmPrflNo_D_Stat : 52|3@0+ (1,0) [0|7] "SED"  GENERIC
 SG_ EmPrflKeyAssoc_D_Stat : 55|3@0+ (1,0) [0|7] "SED"  GENERIC
 SG_ PersRecallSrc_D_Actl : 63|3@0+ (1,0) [0|7] "SED"  DSM
 SG_ VehKeyActv_D_Stat : 47|4@0+ (1,0) [0|15] "SED"  GENERIC
 SG_ PersSetupRestr_D_Actl : 21|2@0+ (1,0) [0|3] "SED"  GENERIC,HVAC_RCCM,PDM,DDM,DSM
 SG_ PersSetupAccessCtrl : 19|1@0+ (1,0) [0|1] "SED"  GENERIC,HVAC_RCCM,DDM,DSM
 SG_ PersSetup_No_Actl : 31|16@0+ (1,0) [0|65535] "Number"  GENERIC,HVAC_RCCM,PDM,DDM,DSM
 SG_ PersConflict_D_Actl : 22|1@0+ (1,0) [0|1] "SED"  GENERIC
 SG_ AssocConfirm_D_Actl : 15|3@0+ (1,0) [0|7] "SED"  GENERIC
 SG_ RecallEvent_No_Cnt : 7|8@0+ (1,0) [0|255] "Counts"  GENERIC,HVAC_RCCM,SCMG,SCMH,DDM,DSM
 SG_ PersNo_D_Actl : 10|3@0+ (1,0) [0|7] "SED"  GENERIC,HVAC_RCCM,DDM,DSM,SCMG,SCMH
 SG_ PersNoPos_D_Actl : 18|3@0+ (1,0) [0|7] "SED"  GENERIC,SCMG,SCMH,DSM

BO_ 1945 TesterPhysicalResTRM: 8 TRM
 SG_ TesterPhysicalResTRM : 7|64@0+ (1,0) [0|1.84467E+019] "unitless"  TSTR

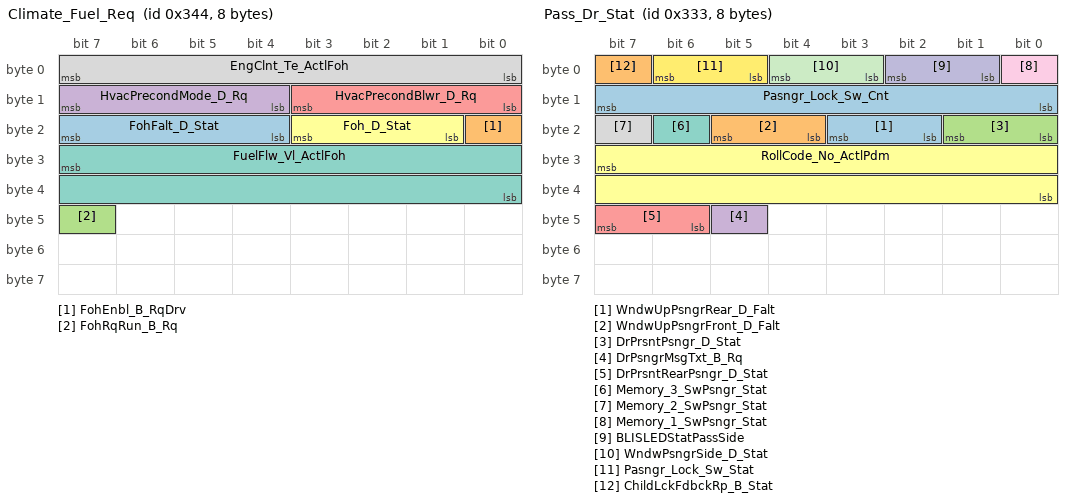
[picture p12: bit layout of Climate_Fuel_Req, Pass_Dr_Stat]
BO_ 836 Climate_Fuel_Req: 8 SOBDMD_AHCM_FOH
 SG_ FohFalt_D_Stat : 23|4@0+ (1,0) [0|15] "SED"  GWM
 SG_ FohEnbl_B_RqDrv : 16|1@0+ (1,0) [0|1] "SED"  GWM
 SG_ FohRqRun_B_Rq : 47|1@0+ (1,0) [0|1] "SED"  GWM
 SG_ HvacPrecondMode_D_Rq : 15|4@0+ (1,0) [0|15] "SED"  HVAC_RCCM,GWM
 SG_ HvacPrecondBlwr_D_Rq : 11|4@0+ (1,0) [0|15] "SED"  HVAC_RCCM,GWM
 SG_ Foh_D_Stat : 19|3@0+ (1,0) [0|7] "SED"  HVAC_RCCM,GWM
 SG_ FuelFlw_Vl_ActlFoh : 31|16@0+ (25,0) [0|1638375] "microlitre"  GWM
 SG_ EngClnt_Te_ActlFoh : 7|8@0+ (1,-50) [-50|204] "degC"  HVAC_RCCM,GWM

BO_ 819 Pass_Dr_Stat: 8 PDM
 SG_ WndwUpPsngrRear_D_Falt : 19|2@0+ (1,0) [0|3] "SED"  GWM
 SG_ WndwUpPsngrFront_D_Falt : 21|2@0+ (1,0) [0|3] "SED"  GWM
 SG_ DrPrsntPsngr_D_Stat : 17|2@0+ (1,0) [0|3] "SED"  GWM
 SG_ DrPsngrMsgTxt_B_Rq : 45|1@0+ (1,0) [0|1] "SED"  GWM
 SG_ DrPrsntRearPsngr_D_Stat : 47|2@0+ (1,0) [0|3] "SED"  GWM
 SG_ RollCode_No_ActlPdm : 31|16@0+ (1,0) [0|65535] "Unitless"  GWM
 SG_ Memory_3_SwPsngr_Stat : 22|1@0+ (1,0) [0|1] "SED"  SCMB_PSM,GWM
 SG_ Memory_2_SwPsngr_Stat : 23|1@0+ (1,0) [0|1] "SED"  SCMB_PSM,GWM
 SG_ Memory_1_SwPsngr_Stat : 0|1@0+ (1,0) [0|1] "SED"  SCMB_PSM,GWM
 SG_ BLISLEDStatPassSide : 2|2@0+ (1,0) [0|3] "SED"  GWM
 SG_ WndwPsngrSide_D_Stat : 4|2@0+ (1,0) [0|3] "SED"  GWM
 SG_ Pasngr_Lock_Sw_Stat : 6|2@0+ (1,0) [0|3] "SED"  GWM
 SG_ Pasngr_Lock_Sw_Cnt : 15|8@0+ (1,0) [0|255] "Cnt"  GWM
 SG_ ChildLckFdbckRp_B_Stat : 7|1@0+ (1,0) [0|1] "SED"  GWM

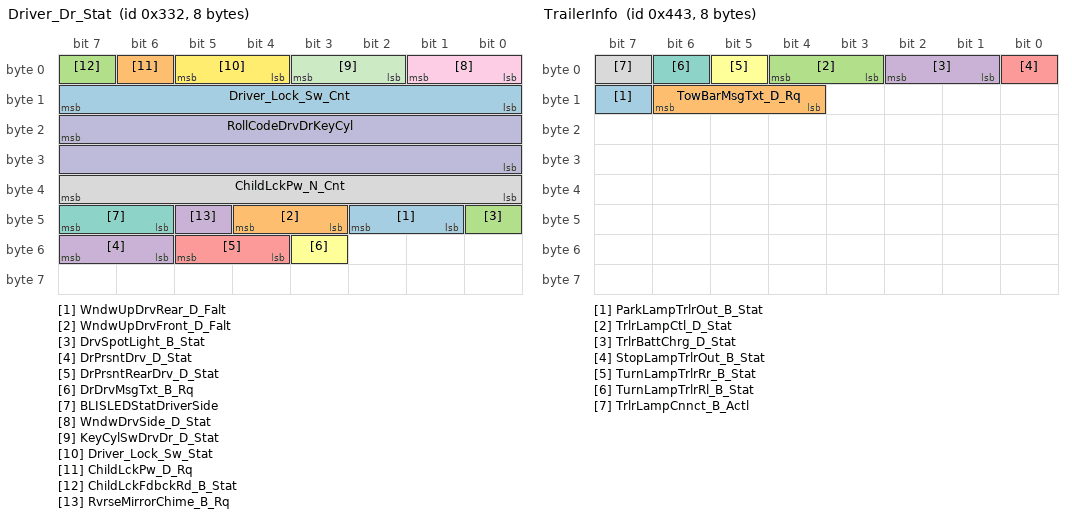
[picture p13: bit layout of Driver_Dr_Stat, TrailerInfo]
BO_ 818 Driver_Dr_Stat: 8 DDM
 SG_ WndwUpDrvRear_D_Falt : 42|2@0+ (1,0) [0|3] "SED"  GWM
 SG_ WndwUpDrvFront_D_Falt : 44|2@0+ (1,0) [0|3] "SED"  GWM
 SG_ DrvSpotLight_B_Stat : 40|1@0+ (1,0) [0|1] "SED"  PDM,GWM
 SG_ DrPrsntDrv_D_Stat : 55|2@0+ (1,0) [0|3] "SED"  GWM
 SG_ DrPrsntRearDrv_D_Stat : 53|2@0+ (1,0) [0|3] "SED"  GWM
 SG_ DrDrvMsgTxt_B_Rq : 51|1@0+ (1,0) [0|1] "SED"  GWM
 SG_ BLISLEDStatDriverSide : 47|2@0+ (1,0) [0|3] "SED"  GWM
 SG_ ChildLckPw_N_Cnt : 39|8@0+ (1,0) [0|255] "unitless"  GWM
 SG_ WndwDrvSide_D_Stat : 1|2@0+ (1,0) [0|3] "SED"  GWM
 SG_ RollCodeDrvDrKeyCyl : 23|16@0+ (1,0) [0|65535] "Unitless"  GWM
 SG_ KeyCylSwDrvDr_D_Stat : 3|2@0+ (1,0) [0|3] "SED"  GWM
 SG_ Driver_Lock_Sw_Stat : 5|2@0+ (1,0) [0|3] "SED"  GWM
 SG_ Driver_Lock_Sw_Cnt : 15|8@0+ (1,0) [0|255] "Cnt"  GWM
 SG_ ChildLckPw_D_Rq : 6|1@0+ (1,0) [0|1] "SED"  GWM
 SG_ ChildLckFdbckRd_B_Stat : 7|1@0+ (1,0) [0|1] "SED"  GWM
 SG_ RvrseMirrorChime_B_Rq : 45|1@0+ (1,0) [0|1] "SED"  DSM,GWM

BO_ 817 Locking_Systems_2_MS1: 8 GWM
 SG_ ChildLckMde_B_Stat : 56|1@0+ (1,0) [0|1] "SED" Vector__XXX
 SG_ VehLckInd_D_Rq : 58|2@0+ (1,0) [0|3] "SED"  DDM,PDM
 SG_ DrTgateOpen_B_Rq : 59|1@0+ (1,0) [0|1] "SED"  RGTM
 SG_ DrTgateExtSwMde_B_Stat : 32|1@0+ (1,0) [0|1] "SED"  RGTM
 SG_ Remote_Device_Feedback : 50|3@0+ (1,0) [0|7] "SED"  RSM,RTM
 SG_ R_Pwr_Sliding_Dr_Rqst : 36|1@0+ (1,0) [0|1] "SED"  GENERIC
 SG_ Power_Liftgate_Rqst : 0|1@0+ (1,0) [0|1] "SED"  RGTM
 SG_ Power_Decklid_Rqst : 1|1@0+ (1,0) [0|1] "SED"  RGTM
 SG_ L_Pwr_Sliding_Dr_Rqst : 3|1@0+ (1,0) [0|1] "SED"  GENERIC
 SG_ Keyfob_Pad_Msg_Count : 15|8@0+ (1,0) [0|255] "Counts"  RGTM
 SG_ Veh_Lock_Requestor : 55|5@0+ (1,0) [0|31] "SED"  HVAC_RCCM,RSM,DDM,PDM
 SG_ Veh_Lock_EvNum : 47|8@0+ (1,0) [0|255] "unitless"  HVAC_RCCM,RSM,DDM,PDM
 SG_ Veh_Lock_Sub_Id : 63|4@0+ (1,0) [0|15] "SED"  RSM,DDM,PDM
 SG_ ChildLck_D_Dsply : 7|2@0+ (1,0) [0|3] "SED"  DDM
 SG_ WindowLockout_B_Stat : 35|1@0+ (1,0) [0|1] "SED"  SCMB_PSM,SCMG,SCMH,DDM
 SG_ RollCodeUnlock : 23|16@0+ (1,0) [0|65535] "Unitless"  PDM,RSM,DDM
 SG_ Lockmsgtxt_D_Rq : 39|3@0+ (1,0) [0|7] "SED"  GENERIC
 SG_ LockInhibit : 2|1@0+ (1,0) [0|1] "SED"  RGTM
 SG_ Veh_Lock_Status : 34|2@0+ (1,0) [0|3] "SED"  HVAC_RCCM,RSM,DDM,PDM,RGTM
 SG_ FobComm_D_Stat : 5|2@0+ (1,0) [0|3] "SED"  GENERIC,RTM

BO_ 1091 TrailerInfo: 8 TRM
 SG_ ParkLampTrlrOut_B_Stat : 15|1@0+ (1,0) [0|1] "SED"  GWM
 SG_ TowBarMsgTxt_D_Rq : 14|3@0+ (1,0) [0|7] "SED"  GWM
 SG_ TrlrLampCtl_D_Stat : 4|2@0+ (1,0) [0|3] "SED"  GWM
 SG_ TrlrBattChrg_D_Stat : 2|2@0+ (1,0) [0|3] "SED"  GWM
 SG_ StopLampTrlrOut_B_Stat : 0|1@0+ (1,0) [0|1] "SED"  GWM
 SG_ TurnLampTrlrRr_B_Stat : 5|1@0+ (1,0) [0|1] "SED"  GWM
 SG_ TurnLampTrlrRl_B_Stat : 6|1@0+ (1,0) [0|1] "SED"  GWM
 SG_ TrlrLampCnnct_B_Actl : 7|1@0+ (1,0) [0|1] "SED"  GWM

BO_ 1865 TesterPhysicalResPDM: 8 PDM
 SG_ TesterPhysicalResPDM : 7|64@0+ (1,0) [0|1.84467E+019] "unitless"  TSTR

BO_ 1857 TesterPhysicalReqPDM: 8 TSTR
 SG_ TesterPhysicalReqPDM : 7|64@0+ (1,0) [0|1.84467E+019] "unitless"  PDM

BO_ 1819 TesterPhysicalResSCMH: 8 SCMH
 SG_ TesterPhysicalResSCMH : 7|64@0+ (1,0) [0|1.84467E+019] "unitless"  TSTR

BO_ 1818 TesterPhysicalResSCMG: 8 SCMG
 SG_ TesterPhysicalResSCMG : 7|64@0+ (1,0) [0|1.84467E+019] "unitless"  TSTR

BO_ 1811 TesterPhysicalReqSCMH: 8 TSTR
 SG_ TesterPhysicalReqSCMH : 7|64@0+ (1,0) [0|1.84467E+019] "unitless"  SCMH

BO_ 1810 TesterPhysicalReqSCMG: 8 TSTR
 SG_ TesterPhysicalReqSCMG : 7|64@0+ (1,0) [0|1.84467E+019] "unitless"  SCMG

BO_ 1310 GWM_Network_MgmtM_MS1: 8 GWM
 SG_ GWM_Network_Mgmt_MS1 : 7|64@0+ (1,0) [0|1.84467440737096E+019] "unitless"  GENERIC

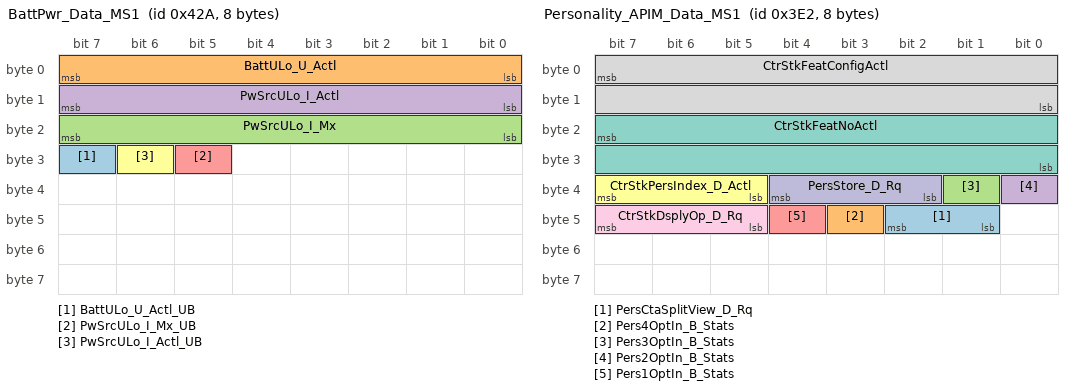
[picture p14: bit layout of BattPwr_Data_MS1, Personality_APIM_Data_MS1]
BO_ 1066 BattPwr_Data_MS1: 8 GWM
 SG_ BattULo_U_Actl_UB : 31|1@0+ (1,0) [0|1] "SED"  HVAC_RCCM
 SG_ BattULo_U_Actl : 7|8@0+ (0.0625,0) [0|15.875] "volt"  HVAC_RCCM
 SG_ PwSrcULo_I_Mx : 23|8@0+ (1,0) [0|254] "ampere"  HVAC_RCCM
 SG_ PwSrcULo_I_Actl : 15|8@0+ (1,0) [0|254] "ampere"  HVAC_RCCM
 SG_ PwSrcULo_I_Mx_UB : 29|1@0+ (1,0) [0|1] "SED"  HVAC_RCCM
 SG_ PwSrcULo_I_Actl_UB : 30|1@0+ (1,0) [0|1] "SED"  HVAC_RCCM

BO_ 994 Personality_APIM_Data_MS1: 8 GWM
 SG_ PersCtaSplitView_D_Rq : 42|2@0+ (1,0) [0|3] "SED"  GENERIC
 SG_ Pers4OptIn_B_Stats : 43|1@0+ (1,0) [0|1] "SED"  GENERIC
 SG_ Pers3OptIn_B_Stats : 33|1@0+ (1,0) [0|1] "SED"  GENERIC
 SG_ Pers2OptIn_B_Stats : 32|1@0+ (1,0) [0|1] "SED"  GENERIC
 SG_ Pers1OptIn_B_Stats : 44|1@0+ (1,0) [0|1] "SED"  GENERIC
 SG_ CtrStkPersIndex_D_Actl : 39|3@0+ (1,0) [0|7] "SED"  HVAC_RCCM,PDM,DDM,DSM,SCMG,SCMH
 SG_ CtrStkFeatNoActl : 23|16@0+ (1,0) [0|65535] "Undefined"  HVAC_RCCM,PDM,DDM,DSM
 SG_ CtrStkFeatConfigActl : 7|16@0+ (1,0) [0|65535] "Undefined"  HVAC_RCCM,PDM,DDM,DSM
 SG_ CtrStkDsplyOp_D_Rq : 47|3@0+ (1,0) [0|7] "SED"  HVAC_RCCM,PDM,DDM,DSM,SCMG,SCMH
 SG_ PersStore_D_Rq : 36|3@0+ (1,0) [0|7] "SED"  DDM,DSM

CM_ BO_ 374 "Programs w/o HS1 0x172 will need HS1 0x176 for GearPos_D_Actl.  Future MY Programs that choose c/o still require HS1 0x172. ";
CM_ SG_ 374 TrnRng_D_Rq "Powersplit HEVs with HF45, HPCM will Tx  this message.  For all other programs it will be Tx by PCM or TCM. ";
CM_ SG_ 374 TrnPrkSys_D_Actl "Powersplit HEVs with HF45, HPCM will Tx  this message.  For all other programs it will be Tx by PCM or TCM. ";
CM_ SG_ 374 GearLvr_D_ActlDrv "Powersplit HEVs with HF45, HPCM will Tx  this message.  For all other programs it will be Tx by PCM or TCM. ";
CM_ SG_ 374 GearPos_No_Cs "Powersplit HEVs with HF45, HPCM will Tx  this message.  For all other programs it will be Tx by PCM or TCM. ";
CM_ SG_ 374 GearPos_D_Trg "Powersplit HEVs with HF45, HPCM will Tx  this message.  For all other programs it will be Tx by PCM or TCM. ";
CM_ SG_ 374 GearPos_No_Cnt "Powersplit HEVs with HF45, HPCM will Tx  this message.  For all other programs it will be Tx by PCM or TCM. ";
CM_ SG_ 374 GearPos_D_Actl "Powersplit HEVs with HF45, HPCM will Tx  this message.  For all other programs it will be Tx by PCM or TCM. ";
CM_ SG_ 1079 GenericSwtch2_No_Actl "U625 Police Wig Wag feature";
CM_ BO_ 948 "$3B4 used by CGEA SPDJB";
CM_ SG_ 840 FohT2Friday_T_Rq "Signal not transmitted on vehicles that do not have the Fuel operated heater feature.";
CM_ SG_ 840 FohT1Friday_T_Rq "Signal not transmitted on vehicles that do not have the Fuel operated heater feature.";
CM_ SG_ 840 FohT2Wednesday_T_Rq "Signal not transmitted on vehicles that do not have the Fuel operated heater feature.";
CM_ SG_ 840 FohT2Tuesday_T_Rq "Signal not transmitted on vehicles that do not have the Fuel operated heater feature.";
CM_ SG_ 840 FohT2Thursday_T_Rq "Signal not transmitted on vehicles that do not have the Fuel operated heater feature.";
CM_ SG_ 840 FohT2Sunday_T_Rq "Signal not transmitted on vehicles that do not have the Fuel operated heater feature.";
CM_ SG_ 840 FohT2Saturday_T_Rq "Signal not transmitted on vehicles that do not have the Fuel operated heater feature.";
CM_ SG_ 840 FohT2Monday_T_Rq "Signal not transmitted on vehicles that do not have the Fuel operated heater feature.";
CM_ SG_ 840 FohT1Wednesday_T_Rq "Signal not transmitted on vehicles that do not have the Fuel operated heater feature.";
CM_ SG_ 840 FohT1Tuesday_T_Rq "Signal not transmitted on vehicles that do not have the Fuel operated heater feature.";
CM_ SG_ 840 FohT1Thursday_T_Rq "Signal not transmitted on vehicles that do not have the Fuel operated heater feature.";
CM_ SG_ 840 FohT1Sunday_T_Rq "Signal not transmitted on vehicles that do not have the Fuel operated heater feature.";
CM_ SG_ 840 FohT1Saturday_T_Rq "Signal not transmitted on vehicles that do not have the Fuel operated heater feature.";
CM_ SG_ 840 FohT1Monday_T_Rq "Signal not transmitted on vehicles that do not have the Fuel operated heater feature.";
CM_ SG_ 981 HvacPrecondMode2_D_Rq "Signal not transmitted on vehicles that do not have the Fuel operated heater feature.";
CM_ SG_ 981 HvacPrecondBlwr2_D_Rq "Signal not transmitted on vehicles that do not have the Fuel operated heater feature.";
CM_ SG_ 839 FohStop_B_Stat "Signal not transmitted on vehicles that do not have the Fuel operated heater feature.";
CM_ SG_ 839 FohMsgTxt_D_Rq "Signal not transmitted on vehicles that do not have the Fuel operated heater feature.";
CM_ SG_ 839 FohKeyOff_B_Rq "Signal not transmitted on vehicles that do not have the Fuel operated heater feature.";
CM_ SG_ 839 FohEnbl_B_Rq "Signal not transmitted on vehicles that do not have the Fuel operated heater feature.";
CM_ SG_ 839 FohTAllEnable_B_Stat "Signal not transmitted on vehicles that do not have the Fuel operated heater feature.";
CM_ SG_ 839 FohT2Mnte_T_Stat "Signal not transmitted on vehicles that do not have the Fuel operated heater feature.";
CM_ SG_ 839 FohT2Hr_T_Stat "Signal not transmitted on vehicles that do not have the Fuel operated heater feature.";
CM_ SG_ 839 FohT2Enable_B_Stat "Signal not transmitted on vehicles that do not have the Fuel operated heater feature.";
CM_ SG_ 839 FohT1Mnte_T_Stat "Signal not transmitted on vehicles that do not have the Fuel operated heater feature.";
CM_ SG_ 839 FohT1Hr_T_Stat "Signal not transmitted on vehicles that do not have the Fuel operated heater feature.";
CM_ SG_ 839 FohT1Enable_B_Stat "Signal not transmitted on vehicles that do not have the Fuel operated heater feature.";
CM_ SG_ 839 FohStrtMnte_T_Stat "Signal not transmitted on vehicles that do not have the Fuel operated heater feature.";
CM_ SG_ 839 FohStrtHr_T_Stat "Signal not transmitted on vehicles that do not have the Fuel operated heater feature.";
CM_ SG_ 839 FohStrtEnable_B_Stat "Signal not transmitted on vehicles that do not have the Fuel operated heater feature.";
CM_ SG_ 839 FohContOn_B_Stat "Signal not transmitted on vehicles that do not have the Fuel operated heater feature.";
CM_ SG_ 839 FohT2Wednesday_T_Stat "Signal not transmitted on vehicles that do not have the Fuel operated heater feature.";
CM_ SG_ 839 FohT2Tuesday_T_Stat "Signal not transmitted on vehicles that do not have the Fuel operated heater feature.";
CM_ SG_ 839 FohT2Thursday_T_Stat "Signal not transmitted on vehicles that do not have the Fuel operated heater feature.";
CM_ SG_ 839 FohT2Sunday_T_Stat "Signal not transmitted on vehicles that do not have the Fuel operated heater feature.";
CM_ SG_ 839 FohT2Saturday_T_Stat "Signal not transmitted on vehicles that do not have the Fuel operated heater feature.";
CM_ SG_ 839 FohT2Monday_T_Stat "Signal not transmitted on vehicles that do not have the Fuel operated heater feature.";
CM_ SG_ 839 FohT2Friday_T_Stat "Signal not transmitted on vehicles that do not have the Fuel operated heater feature.";
CM_ SG_ 839 FohT1Wednesday_T_Stat "Signal not transmitted on vehicles that do not have the Fuel operated heater feature.";
CM_ SG_ 839 FohT1Tuesday_T_Stat "Signal not transmitted on vehicles that do not have the Fuel operated heater feature.";
CM_ SG_ 839 FohT1Thursday_T_Stat "Signal not transmitted on vehicles that do not have the Fuel operated heater feature.";
CM_ SG_ 839 FohT1Sunday_T_Stat "Signal not transmitted on vehicles that do not have the Fuel operated heater feature.";
CM_ SG_ 839 FohT1Saturday_T_Stat "Signal not transmitted on vehicles that do not have the Fuel operated heater feature.";
CM_ SG_ 839 FohT1Monday_T_Stat "Signal not transmitted on vehicles that do not have the Fuel operated heater feature.";
CM_ SG_ 839 FohT1Friday_T_Stat "Signal not transmitted on vehicles that do not have the Fuel operated heater feature.";
CM_ SG_ 765 ClimtBlwrLim_B_Rq "NotSupported on FNV2, no transmitter";
CM_ SG_ 765 Bezel_Beeps_Rq "Vehicle Settings";
CM_ SG_ 765 Diagnostic_Operation_Rq "Object:BezelDiagnostics.MFD_Bezel_Diagnostic.St";
CM_ SG_ 765 Bezel_Diag_State_Rq "Object:BezelDiagnostics.MFD_Bezel_Diagnostic.Rq";
CM_ SG_ 765 Bezel_Diag_Module_Rq "Object:BezelDiagnostics.MFD_Bezel_Diagnostic.St";
CM_ SG_ 765 HMI_HMIMode_St "Object ACU System Master.HMIMode
OR
Object NAV System Master.HMIMode

Refer Method HMIAudioMode in the SPSS";
CM_ SG_ 765 Mc_VehUnitTempUsrSel_St "Object.VehicleSettings.Disp_Temperature.Rq";
CM_ SG_ 359 TrnAin_Tq_Actl "Signal not transmitted on HEV variances.";
CM_ SG_ 359 TrnAinTq_D_Qf "Signal not transmitted on HEV variances.";
CM_ SG_ 359 PlgActvArb_B_Actl "Only supported on PHEV programs.  PlgActvArb_B_Actl HPCM will Tx on Powersplit PHEV’s,  On MHT PHEVs the PCM_HEV will Tx and HPCM will Rx. 
";
CM_ SG_ 836 FohFalt_D_Stat "Signal not transmitted on vehicles that do not have the Fuel operated heater feature.";
CM_ SG_ 836 FohEnbl_B_RqDrv "Signal not transmitted on vehicles that do not have the Fuel operated heater feature.";
CM_ SG_ 836 FohRqRun_B_Rq "Signal not transmitted on vehicles that do not have the Fuel operated heater feature.";
CM_ SG_ 836 HvacPrecondMode_D_Rq "Signal not transmitted on vehicles that do not have the Fuel operated heater feature.";
CM_ SG_ 836 HvacPrecondBlwr_D_Rq "Signal not transmitted on vehicles that do not have the Fuel operated heater feature.";
CM_ SG_ 836 Foh_D_Stat "Signal not transmitted on vehicles that do not have the Fuel operated heater feature.";
CM_ SG_ 836 FuelFlw_Vl_ActlFoh "Signal not transmitted on vehicles that do not have the Fuel operated heater feature.";
CM_ SG_ 836 EngClnt_Te_ActlFoh "Signal not transmitted on vehicles that do not have the Fuel operated heater feature.";
BA_DEF_ BO_  "FrameRouting" STRING ;
BA_DEF_ BO_  "FrameGatewayNetwork" STRING ;
BA_DEF_ BO_  "NetworkInitialization" ENUM  "No","Yes";
BA_DEF_ BO_  "FrameGatewayId" HEX 0 1407;
BA_DEF_ BO_  "EventRateOfChange" INT 10 10000;
BA_DEF_ BO_  "GenMsgStartDelayTime" INT 0 10000;
BA_DEF_ BO_  "GenMsgNrOfRepetition" INT 0 100;
BA_DEF_ BO_  "GenMsgDelayTime" INT 0 1000;
BA_DEF_ BO_  "GenMsgCycleTime" INT 0 100000;
BA_DEF_ BO_  "GenMsgSendType" ENUM  "FixedPeriodic","Event","EnabledPeriodic","NotUsed","NotUsed","EventPeriodic","NotUsed","NotUsed","NoMsgSendType";
BA_DEF_ SG_  "U_CD764_MY2022_Tx" ENUM  "No","Yes";
BA_DEF_ SG_  "U_U55X_MY2022_Tx" ENUM  "No","Yes";
BA_DEF_ SG_  "U_CD542_MY2021_Tx" ENUM  "No","Yes";
BA_DEF_ SG_  "ECGUsedTxSignal" ENUM  "No","Yes";
BA_DEF_ SG_  "U_T6_MCA_MY2020_Tx" ENUM  "No","Yes";
BA_DEF_ SG_  "U_P702_MY2021_Tx" ENUM  "No","Yes";
BA_DEF_ SG_  "U_CX727_MY2021_Tx" ENUM  "No","Yes";
BA_DEF_ SG_  "U_CD764_MY2022_Rx" ENUM  "No","Yes";
BA_DEF_ SG_  "U_U55X_MY2022_Rx" ENUM  "No","Yes";
BA_DEF_ SG_  "U_CD542_MY2021_Rx" ENUM  "No","Yes";
BA_DEF_ SG_  "ECGUsedRxSignal" ENUM  "No","Yes";
BA_DEF_ SG_  "U_T6_MCA_MY2020_Rx" ENUM  "No","Yes";
BA_DEF_ SG_  "U_P702_MY2021_Rx" ENUM  "No","Yes";
BA_DEF_ SG_  "U_CX727_MY2021_Rx" ENUM  "No","Yes";
BA_DEF_ SG_  "GenSigStartValue" HEX 0 268435455;
BA_DEF_ SG_  "MetaData" ENUM  "No","Yes";
BA_DEF_ SG_  "ContentDependant" ENUM  "No","Yes";
BA_DEF_ SG_  "GenSigStartValueInteger" INT 0 1000000000;
BA_DEF_ SG_  "UsedOnPgmDBC" ENUM  "No","Yes";
BA_DEF_ SG_  "WakeupSignal" ENUM  "No","Yes";
BA_DEF_ SG_  "GenSigInactiveValue" INT 0 100000;
BA_DEF_ SG_  "GenSigSendType" ENUM  "Cyclic","OnWrite","vector_leerstring","OnChange","vector_leerstring","IfActive","vector_leerstring","NoSigSendType";
BA_DEF_ BO_  "OvtpPushApplication" ENUM  "FALSE","TRUE";
BA_DEF_ BO_  "SCP_FreshnessValueLength" INT 0 512;
BA_DEF_ BO_  "SCP_FreshnessValueTxLength" INT 0 512;
BA_DEF_ BO_  "SCP_AuthInfoTxLength" INT 0 512;
BA_DEF_ BO_  "GenMsgRoutingTimeoutTime" INT 0 5000;
BA_DEF_ BO_  "MessageGateway" ENUM  "No","Yes";
BA_DEF_ BO_  "NmAsrMessage" ENUM  "No","Yes";
BA_DEF_ BO_  "DiagState" ENUM  "No","Yes";
BA_DEF_ BO_  "TpTxIndex" INT 0 536870911;
BA_DEF_ BO_  "DiagRequest" ENUM  "No","Yes";
BA_DEF_ BO_  "DiagResponse" ENUM  "No","Yes";
BA_DEF_ BO_  "NmMessage" ENUM  "No","Yes";
BA_DEF_ BO_  "GenMsgILSupport" ENUM  "No","Yes";
BA_DEF_DEF_  "FrameRouting" "";
BA_DEF_DEF_  "FrameGatewayNetwork" "NONE";
BA_DEF_DEF_  "NetworkInitialization" "Yes";
BA_DEF_DEF_  "FrameGatewayId" 0;
BA_DEF_DEF_  "EventRateOfChange" 10000;
BA_DEF_DEF_  "GenMsgStartDelayTime" 0;
BA_DEF_DEF_  "GenMsgNrOfRepetition" 1;
BA_DEF_DEF_  "GenMsgDelayTime" 20;
BA_DEF_DEF_  "GenMsgCycleTime" 0;
BA_DEF_DEF_  "GenMsgSendType" "NoMsgSendType";
BA_DEF_DEF_  "U_CD764_MY2022_Tx" "No";
BA_DEF_DEF_  "U_U55X_MY2022_Tx" "No";
BA_DEF_DEF_  "U_CD542_MY2021_Tx" "No";
BA_DEF_DEF_  "ECGUsedTxSignal" "No";
BA_DEF_DEF_  "U_T6_MCA_MY2020_Tx" "No";
BA_DEF_DEF_  "U_P702_MY2021_Tx" "No";
BA_DEF_DEF_  "U_CX727_MY2021_Tx" "No";
BA_DEF_DEF_  "U_CD764_MY2022_Rx" "No";
BA_DEF_DEF_  "U_U55X_MY2022_Rx" "No";
BA_DEF_DEF_  "U_CD542_MY2021_Rx" "No";
BA_DEF_DEF_  "ECGUsedRxSignal" "No";
BA_DEF_DEF_  "U_T6_MCA_MY2020_Rx" "No";
BA_DEF_DEF_  "U_P702_MY2021_Rx" "No";
BA_DEF_DEF_  "U_CX727_MY2021_Rx" "No";
BA_DEF_DEF_  "GenSigStartValue" 0;
BA_DEF_DEF_  "MetaData" "No";
BA_DEF_DEF_  "ContentDependant" "No";
BA_DEF_DEF_  "GenSigStartValueInteger" 0;
BA_DEF_DEF_  "UsedOnPgmDBC" "Yes";
BA_DEF_DEF_  "WakeupSignal" "No";
BA_DEF_DEF_  "GenSigInactiveValue" 0;
BA_DEF_DEF_  "GenSigSendType" "NoSigSendType";
BA_DEF_DEF_  "OvtpPushApplication" "FALSE";
BA_DEF_DEF_  "SCP_FreshnessValueLength" 64;
BA_DEF_DEF_  "SCP_FreshnessValueTxLength" 11;
BA_DEF_DEF_  "SCP_AuthInfoTxLength" 53;
BA_DEF_DEF_  "GenMsgRoutingTimeoutTime" 0;
BA_DEF_DEF_  "MessageGateway" "No";
BA_DEF_DEF_  "NmAsrMessage" "No";
BA_DEF_DEF_  "DiagState" "No";
BA_DEF_DEF_  "TpTxIndex" 0;
BA_DEF_DEF_  "DiagRequest" "No";
BA_DEF_DEF_  "DiagResponse" "No";
BA_DEF_DEF_  "NmMessage" "No";
BA_DEF_DEF_  "GenMsgILSupport" "Yes";
BA_ "GenMsgCycleTime" BO_ 798 1000;
BA_ "GenMsgSendType" BO_ 798 5;
BA_ "FrameRouting" BO_ 374 "FD1_CAN,0x176;";
BA_ "FrameGatewayNetwork" BO_ 374 "FD1_CAN";
BA_ "FrameGatewayId" BO_ 374 374;
BA_ "FrameRouting" BO_ 662 "HS3_CAN,0x296;";
BA_ "FrameGatewayNetwork" BO_ 662 "HS3_CAN";
BA_ "FrameGatewayId" BO_ 662 662;
BA_ "GenMsgCycleTime" BO_ 670 500;
BA_ "GenMsgSendType" BO_ 670 5;
BA_ "GenMsgCycleTime" BO_ 669 500;
BA_ "GenMsgSendType" BO_ 669 5;
BA_ "NetworkInitialization" BO_ 1413 0;
BA_ "GenMsgCycleTime" BO_ 1413 1000;
BA_ "GenMsgSendType" BO_ 1413 0;
BA_ "NmAsrMessage" BO_ 1413 1;
BA_ "GenMsgILSupport" BO_ 1413 0;
BA_ "NetworkInitialization" BO_ 1412 0;
BA_ "GenMsgCycleTime" BO_ 1412 1000;
BA_ "GenMsgSendType" BO_ 1412 0;
BA_ "NmAsrMessage" BO_ 1412 1;
BA_ "GenMsgILSupport" BO_ 1412 0;
BA_ "GenMsgCycleTime" BO_ 1079 1000;
BA_ "GenMsgSendType" BO_ 1079 5;
BA_ "FrameRouting" BO_ 1095 "HS1_CAN,0x447;";
BA_ "FrameGatewayNetwork" BO_ 1095 "HS1_CAN";
BA_ "FrameGatewayId" BO_ 1095 1095;
BA_ "FrameRouting" BO_ 948 "HS1_CAN,0x3B4;";
BA_ "FrameGatewayNetwork" BO_ 948 "HS1_CAN";
BA_ "FrameGatewayId" BO_ 948 948;
BA_ "FrameRouting" BO_ 840 "HS3_CAN,0x348;";
BA_ "FrameGatewayNetwork" BO_ 840 "HS3_CAN";
BA_ "FrameGatewayId" BO_ 840 840;
BA_ "FrameRouting" BO_ 132 "HS1_CAN,0x84;";
BA_ "FrameGatewayNetwork" BO_ 132 "HS1_CAN";
BA_ "FrameGatewayId" BO_ 132 132;
BA_ "FrameRouting" BO_ 945 "HS1_CAN,0x3B1;";
BA_ "FrameGatewayNetwork" BO_ 945 "HS1_CAN";
BA_ "FrameGatewayId" BO_ 945 945;
BA_ "GenMsgCycleTime" BO_ 981 1000;
BA_ "GenMsgSendType" BO_ 981 0;
BA_ "NetworkInitialization" BO_ 1446 0;
BA_ "GenMsgCycleTime" BO_ 1446 1000;
BA_ "GenMsgSendType" BO_ 1446 0;
BA_ "NmAsrMessage" BO_ 1446 1;
BA_ "GenMsgILSupport" BO_ 1446 0;
BA_ "GenMsgCycleTime" BO_ 839 100;
BA_ "GenMsgSendType" BO_ 839 0;
BA_ "FrameRouting" BO_ 838 "HS3_CAN,0x346;";
BA_ "FrameGatewayNetwork" BO_ 838 "HS3_CAN";
BA_ "FrameGatewayId" BO_ 838 838;
BA_ "GenMsgCycleTime" BO_ 850 500;
BA_ "GenMsgSendType" BO_ 850 0;
BA_ "GenMsgCycleTime" BO_ 849 500;
BA_ "GenMsgSendType" BO_ 849 0;
BA_ "FrameRouting" BO_ 846 "HS3_CAN,0x34E;";
BA_ "FrameGatewayNetwork" BO_ 846 "HS3_CAN";
BA_ "FrameGatewayId" BO_ 846 846;
BA_ "GenMsgCycleTime" BO_ 845 1000;
BA_ "GenMsgSendType" BO_ 845 5;
BA_ "GenMsgCycleTime" BO_ 844 1000;
BA_ "GenMsgSendType" BO_ 844 5;
BA_ "GenMsgCycleTime" BO_ 843 1000;
BA_ "GenMsgSendType" BO_ 843 5;
BA_ "GenMsgCycleTime" BO_ 842 1000;
BA_ "GenMsgSendType" BO_ 842 5;
BA_ "NetworkInitialization" BO_ 1994 0;
BA_ "GenMsgDelayTime" BO_ 1994 0;
BA_ "GenMsgSendType" BO_ 1994 1;
BA_ "DiagResponse" BO_ 1994 1;
BA_ "GenMsgILSupport" BO_ 1994 0;
BA_ "NetworkInitialization" BO_ 1986 0;
BA_ "GenMsgDelayTime" BO_ 1986 0;
BA_ "GenMsgSendType" BO_ 1986 1;
BA_ "DiagRequest" BO_ 1986 1;
BA_ "GenMsgILSupport" BO_ 1986 0;
BA_ "GenMsgCycleTime" BO_ 958 100;
BA_ "GenMsgSendType" BO_ 958 5;
BA_ "GenMsgCycleTime" BO_ 827 1000;
BA_ "GenMsgSendType" BO_ 827 5;
BA_ "GenMsgRoutingTimeoutTime" BO_ 827 180;
BA_ "MessageGateway" BO_ 827 1;
BA_ "GenMsgCycleTime" BO_ 902 1000;
BA_ "GenMsgSendType" BO_ 902 5;
BA_ "GenMsgCycleTime" BO_ 765 1000;
BA_ "GenMsgSendType" BO_ 765 5;
BA_ "GenMsgCycleTime" BO_ 556 1000;
BA_ "GenMsgSendType" BO_ 556 5;
BA_ "NetworkInitialization" BO_ 1815 0;
BA_ "GenMsgDelayTime" BO_ 1815 0;
BA_ "GenMsgSendType" BO_ 1815 1;
BA_ "DiagRequest" BO_ 1815 1;
BA_ "GenMsgILSupport" BO_ 1815 0;
BA_ "GenMsgCycleTime" BO_ 359 1000;
BA_ "GenMsgSendType" BO_ 359 5;
BA_ "GenMsgRoutingTimeoutTime" BO_ 359 30;
BA_ "MessageGateway" BO_ 359 1;
BA_ "GenMsgCycleTime" BO_ 131 100;
BA_ "GenMsgSendType" BO_ 131 0;
BA_ "GenMsgCycleTime" BO_ 990 1000;
BA_ "GenMsgSendType" BO_ 990 5;
BA_ "GenMsgCycleTime" BO_ 1246 100;
BA_ "GenMsgSendType" BO_ 1246 5;
BA_ "FrameRouting" BO_ 1003 "HS1_CAN,0x3EB;";
BA_ "FrameGatewayNetwork" BO_ 1003 "HS1_CAN";
BA_ "FrameGatewayId" BO_ 1003 1003;
BA_ "NetworkInitialization" BO_ 1945 0;
BA_ "GenMsgDelayTime" BO_ 1945 0;
BA_ "GenMsgSendType" BO_ 1945 1;
BA_ "DiagResponse" BO_ 1945 1;
BA_ "GenMsgILSupport" BO_ 1945 0;
BA_ "GenMsgCycleTime" BO_ 836 1000;
BA_ "GenMsgSendType" BO_ 836 0;
BA_ "GenMsgStartDelayTime" BO_ 819 100;
BA_ "GenMsgCycleTime" BO_ 819 100;
BA_ "GenMsgSendType" BO_ 819 5;
BA_ "GenMsgStartDelayTime" BO_ 818 100;
BA_ "GenMsgCycleTime" BO_ 818 100;
BA_ "GenMsgSendType" BO_ 818 5;
BA_ "FrameRouting" BO_ 817 "HS1_CAN,0x331;";
BA_ "FrameGatewayNetwork" BO_ 817 "HS1_CAN";
BA_ "FrameGatewayId" BO_ 817 817;
BA_ "GenMsgCycleTime" BO_ 1091 1000;
BA_ "GenMsgSendType" BO_ 1091 5;
BA_ "NetworkInitialization" BO_ 1865 0;
BA_ "GenMsgDelayTime" BO_ 1865 0;
BA_ "GenMsgSendType" BO_ 1865 1;
BA_ "DiagResponse" BO_ 1865 1;
BA_ "GenMsgILSupport" BO_ 1865 0;
BA_ "NetworkInitialization" BO_ 1857 0;
BA_ "GenMsgDelayTime" BO_ 1857 0;
BA_ "GenMsgSendType" BO_ 1857 1;
BA_ "DiagRequest" BO_ 1857 1;
BA_ "GenMsgILSupport" BO_ 1857 0;
BA_ "NetworkInitialization" BO_ 1819 0;
BA_ "GenMsgDelayTime" BO_ 1819 0;
BA_ "GenMsgSendType" BO_ 1819 1;
BA_ "DiagResponse" BO_ 1819 1;
BA_ "GenMsgILSupport" BO_ 1819 0;
BA_ "NetworkInitialization" BO_ 1818 0;
BA_ "GenMsgDelayTime" BO_ 1818 0;
BA_ "GenMsgSendType" BO_ 1818 1;
BA_ "DiagResponse" BO_ 1818 1;
BA_ "GenMsgILSupport" BO_ 1818 0;
BA_ "NetworkInitialization" BO_ 1811 0;
BA_ "GenMsgDelayTime" BO_ 1811 0;
BA_ "GenMsgSendType" BO_ 1811 1;
BA_ "DiagRequest" BO_ 1811 1;
BA_ "GenMsgILSupport" BO_ 1811 0;
BA_ "NetworkInitialization" BO_ 1810 0;
BA_ "GenMsgDelayTime" BO_ 1810 0;
BA_ "GenMsgSendType" BO_ 1810 1;
BA_ "DiagRequest" BO_ 1810 1;
BA_ "GenMsgILSupport" BO_ 1810 0;
BA_ "GenMsgSendType" BO_ 1310 1;
BA_ "NmMessage" BO_ 1310 1;
BA_ "GenMsgILSupport" BO_ 1310 0;
BA_ "GenMsgCycleTime" BO_ 1066 50;
BA_ "GenMsgSendType" BO_ 1066 0;
BA_ "FrameRouting" BO_ 994 "HS3_CAN,0x3E2;";
BA_ "FrameGatewayNetwork" BO_ 994 "HS3_CAN";
BA_ "FrameGatewayId" BO_ 994 994;
BA_ "GenSigSendType" SG_ 798 ClrExitAsst_D_Stat 3;
BA_ "GenSigSendType" SG_ 798 ClrExitAsstMsgTxt2_D_Rq 3;
BA_ "GenSigSendType" SG_ 798 EmPrflNo_D_Rq 3;
BA_ "GenSigSendType" SG_ 798 EmPrflKeyAssoc_D_Rq 3;
BA_ "GenSigSendType" SG_ 798 BattTracCool_B_Actl 3;
BA_ "GenSigSendType" SG_ 798 BattTracDrvSustn_B_Rq 3;
BA_ "GenSigSendType" SG_ 798 ExitNotClrRight_B_Stat 3;
BA_ "GenSigSendType" SG_ 798 ExitNotClrLeft_B_Stat 3;
BA_ "U_CD764_MY2022_Rx" SG_ 798 ClimtCool_D_RqPt_UB 1;
BA_ "U_U55X_MY2022_Rx" SG_ 798 ClimtCool_D_RqPt_UB 1;
BA_ "U_CD764_MY2022_Rx" SG_ 798 ClimtCool_D_RqPt 1;
BA_ "U_U55X_MY2022_Rx" SG_ 798 ClimtCool_D_RqPt 1;
BA_ "GenSigSendType" SG_ 798 ClimtCool_D_RqPt 3;
BA_ "U_CD764_MY2022_Rx" SG_ 798 PudSptLghtRight_D_Rq_UB 1;
BA_ "U_U55X_MY2022_Rx" SG_ 798 PudSptLghtRight_D_Rq_UB 1;
BA_ "U_T6_MCA_MY2020_Rx" SG_ 798 PudSptLghtRight_D_Rq_UB 1;
BA_ "U_CD764_MY2022_Rx" SG_ 798 PudSptLghtLeft_D_Rq_UB 1;
BA_ "U_U55X_MY2022_Rx" SG_ 798 PudSptLghtLeft_D_Rq_UB 1;
BA_ "U_T6_MCA_MY2020_Rx" SG_ 798 PudSptLghtLeft_D_Rq_UB 1;
BA_ "U_CD764_MY2022_Rx" SG_ 798 PudSptLghtRight_D_Rq 1;
BA_ "U_U55X_MY2022_Rx" SG_ 798 PudSptLghtRight_D_Rq 1;
BA_ "U_T6_MCA_MY2020_Rx" SG_ 798 PudSptLghtRight_D_Rq 1;
BA_ "GenSigSendType" SG_ 798 PudSptLghtRight_D_Rq 3;
BA_ "WakeupSignal" SG_ 798 PudSptLghtRight_D_Rq 1;
BA_ "U_CD764_MY2022_Rx" SG_ 798 PwRnngBoardPoll_D_Stat_UB 1;
BA_ "U_U55X_MY2022_Rx" SG_ 798 PwRnngBoardPoll_D_Stat_UB 1;
BA_ "U_CD764_MY2022_Rx" SG_ 798 PwRnngBoardPoll_D_Stat 1;
BA_ "U_U55X_MY2022_Rx" SG_ 798 PwRnngBoardPoll_D_Stat 1;
BA_ "GenSigSendType" SG_ 798 PwRnngBoardPoll_D_Stat 3;
BA_ "WakeupSignal" SG_ 798 PwRnngBoardPoll_D_Stat 1;
BA_ "U_CD764_MY2022_Rx" SG_ 798 AirCondRec_B_RqVehEl_UB 1;
BA_ "U_U55X_MY2022_Rx" SG_ 798 AirCondRec_B_RqVehEl_UB 1;
BA_ "U_CD542_MY2021_Rx" SG_ 798 AirCondRec_B_RqVehEl_UB 1;
BA_ "U_T6_MCA_MY2020_Rx" SG_ 798 AirCondRec_B_RqVehEl_UB 1;
BA_ "U_CD764_MY2022_Rx" SG_ 798 AirCondRec_B_RqVehEl 1;
BA_ "U_U55X_MY2022_Rx" SG_ 798 AirCondRec_B_RqVehEl 1;
BA_ "U_CD542_MY2021_Rx" SG_ 798 AirCondRec_B_RqVehEl 1;
BA_ "U_T6_MCA_MY2020_Rx" SG_ 798 AirCondRec_B_RqVehEl 1;
BA_ "GenSigSendType" SG_ 798 AirCondRec_B_RqVehEl 3;
BA_ "U_U55X_MY2022_Rx" SG_ 798 RmtCtl_D_Stat 1;
BA_ "GenSigSendType" SG_ 798 RmtCtl_D_Stat 3;
BA_ "WakeupSignal" SG_ 798 RmtCtl_D_Stat 1;
BA_ "U_U55X_MY2022_Rx" SG_ 798 RmtCtl_D_Stat_UB 1;
BA_ "U_CD764_MY2022_Rx" SG_ 798 PudSptLghtLeft_D_Rq 1;
BA_ "U_U55X_MY2022_Rx" SG_ 798 PudSptLghtLeft_D_Rq 1;
BA_ "U_T6_MCA_MY2020_Rx" SG_ 798 PudSptLghtLeft_D_Rq 1;
BA_ "GenSigSendType" SG_ 798 PudSptLghtLeft_D_Rq 3;
BA_ "WakeupSignal" SG_ 798 PudSptLghtLeft_D_Rq 1;
BA_ "U_CD764_MY2022_Rx" SG_ 798 PoliceDmngLvl_D_Stat 1;
BA_ "U_U55X_MY2022_Rx" SG_ 798 PoliceDmngLvl_D_Stat 1;
BA_ "U_CD542_MY2021_Rx" SG_ 798 PoliceDmngLvl_D_Stat 1;
BA_ "U_T6_MCA_MY2020_Rx" SG_ 798 PoliceDmngLvl_D_Stat 1;
BA_ "GenSigSendType" SG_ 798 PoliceDmngLvl_D_Stat 3;
BA_ "U_CD764_MY2022_Rx" SG_ 798 VehWlcmFrwlMde_D_Stat_UB 1;
BA_ "U_U55X_MY2022_Rx" SG_ 798 VehWlcmFrwlMde_D_Stat_UB 1;
BA_ "U_T6_MCA_MY2020_Rx" SG_ 798 VehWlcmFrwlMde_D_Stat_UB 1;
BA_ "U_CD764_MY2022_Rx" SG_ 798 VehWlcmFrwl_D_Stat_UB 1;
BA_ "U_U55X_MY2022_Rx" SG_ 798 VehWlcmFrwl_D_Stat_UB 1;
BA_ "U_T6_MCA_MY2020_Rx" SG_ 798 VehWlcmFrwl_D_Stat_UB 1;
BA_ "U_CD764_MY2022_Rx" SG_ 798 VehWlcmFrwlMde_D_Stat 1;
BA_ "U_U55X_MY2022_Rx" SG_ 798 VehWlcmFrwlMde_D_Stat 1;
BA_ "U_T6_MCA_MY2020_Rx" SG_ 798 VehWlcmFrwlMde_D_Stat 1;
BA_ "GenSigSendType" SG_ 798 VehWlcmFrwlMde_D_Stat 3;
BA_ "WakeupSignal" SG_ 798 VehWlcmFrwlMde_D_Stat 1;
BA_ "U_CD764_MY2022_Rx" SG_ 798 VehWlcmFrwl_D_Stat 1;
BA_ "U_U55X_MY2022_Rx" SG_ 798 VehWlcmFrwl_D_Stat 1;
BA_ "U_T6_MCA_MY2020_Rx" SG_ 798 VehWlcmFrwl_D_Stat 1;
BA_ "GenSigSendType" SG_ 798 VehWlcmFrwl_D_Stat 3;
BA_ "WakeupSignal" SG_ 798 VehWlcmFrwl_D_Stat 1;
BA_ "U_CD764_MY2022_Rx" SG_ 798 PoliceDmngLvl_D_Stat_UB 1;
BA_ "U_U55X_MY2022_Rx" SG_ 798 PoliceDmngLvl_D_Stat_UB 1;
BA_ "U_CD542_MY2021_Rx" SG_ 798 PoliceDmngLvl_D_Stat_UB 1;
BA_ "U_T6_MCA_MY2020_Rx" SG_ 798 PoliceDmngLvl_D_Stat_UB 1;
BA_ "GenSigStartValue" SG_ 374 TrnRng_D_Rq 14;
BA_ "ContentDependant" SG_ 374 TrnRng_D_Rq 1;
BA_ "GenSigStartValueInteger" SG_ 374 TrnRng_D_Rq 14;
BA_ "ContentDependant" SG_ 374 TrnPrkSys_D_Actl 1;
BA_ "ContentDependant" SG_ 374 GearLvr_D_ActlDrv 1;
BA_ "MetaData" SG_ 374 GearPos_No_Cs 1;
BA_ "ContentDependant" SG_ 374 GearPos_No_Cs 1;
BA_ "GenSigStartValue" SG_ 374 GearPos_D_Trg 15;
BA_ "ContentDependant" SG_ 374 GearPos_D_Trg 1;
BA_ "GenSigStartValueInteger" SG_ 374 GearPos_D_Trg 15;
BA_ "MetaData" SG_ 374 GearPos_No_Cnt 1;
BA_ "ContentDependant" SG_ 374 GearPos_No_Cnt 1;
BA_ "GenSigStartValue" SG_ 374 GearPos_D_Actl 15;
BA_ "ContentDependant" SG_ 374 GearPos_D_Actl 1;
BA_ "GenSigStartValueInteger" SG_ 374 GearPos_D_Actl 15;
BA_ "U_CD764_MY2022_Tx" SG_ 670 DrHandleOuterRl_D_Stat 1;
BA_ "GenSigSendType" SG_ 670 DrHandleOuterRl_D_Stat 3;
BA_ "U_CD764_MY2022_Tx" SG_ 670 DrHandleOuterFl_D_Stat 1;
BA_ "GenSigSendType" SG_ 670 DrHandleOuterFl_D_Stat 3;
BA_ "U_CD764_MY2022_Tx" SG_ 669 DrHandleOuterRr_D_Stat 1;
BA_ "GenSigSendType" SG_ 669 DrHandleOuterRr_D_Stat 3;
BA_ "U_CD764_MY2022_Tx" SG_ 669 DrHandleOuterFr_D_Stat 1;
BA_ "GenSigSendType" SG_ 669 DrHandleOuterFr_D_Stat 3;
BA_ "U_CD764_MY2022_Tx" SG_ 1413 PDM_GWOnBoardTester 1;
BA_ "U_U55X_MY2022_Tx" SG_ 1413 PDM_GWOnBoardTester 1;
BA_ "U_CD542_MY2021_Tx" SG_ 1413 PDM_GWOnBoardTester 1;
BA_ "U_T6_MCA_MY2020_Tx" SG_ 1413 PDM_GWOnBoardTester 1;
BA_ "U_P702_MY2021_Tx" SG_ 1413 PDM_GWOnBoardTester 1;
BA_ "GenSigStartValue" SG_ 1413 PDM_GWOnBoardTester 255;
BA_ "ContentDependant" SG_ 1413 PDM_GWOnBoardTester 1;
BA_ "GenSigStartValueInteger" SG_ 1413 PDM_GWOnBoardTester 255;
BA_ "U_CD764_MY2022_Tx" SG_ 1413 PDM_GWNMProxy 1;
BA_ "U_U55X_MY2022_Tx" SG_ 1413 PDM_GWNMProxy 1;
BA_ "U_CD542_MY2021_Tx" SG_ 1413 PDM_GWNMProxy 1;
BA_ "U_T6_MCA_MY2020_Tx" SG_ 1413 PDM_GWNMProxy 1;
BA_ "U_P702_MY2021_Tx" SG_ 1413 PDM_GWNMProxy 1;
BA_ "GenSigStartValue" SG_ 1413 PDM_GWNMProxy 255;
BA_ "ContentDependant" SG_ 1413 PDM_GWNMProxy 1;
BA_ "GenSigStartValueInteger" SG_ 1413 PDM_GWNMProxy 255;
BA_ "U_CD764_MY2022_Tx" SG_ 1413 PDM_AutoSarNMReserved4 1;
BA_ "U_U55X_MY2022_Tx" SG_ 1413 PDM_AutoSarNMReserved4 1;
BA_ "U_CD542_MY2021_Tx" SG_ 1413 PDM_AutoSarNMReserved4 1;
BA_ "U_T6_MCA_MY2020_Tx" SG_ 1413 PDM_AutoSarNMReserved4 1;
BA_ "U_P702_MY2021_Tx" SG_ 1413 PDM_AutoSarNMReserved4 1;
BA_ "GenSigStartValue" SG_ 1413 PDM_AutoSarNMReserved4 255;
BA_ "ContentDependant" SG_ 1413 PDM_AutoSarNMReserved4 1;
BA_ "GenSigStartValueInteger" SG_ 1413 PDM_AutoSarNMReserved4 255;
BA_ "U_CD764_MY2022_Tx" SG_ 1413 PDM_AutoSarNMReserved3 1;
BA_ "U_U55X_MY2022_Tx" SG_ 1413 PDM_AutoSarNMReserved3 1;
BA_ "U_CD542_MY2021_Tx" SG_ 1413 PDM_AutoSarNMReserved3 1;
BA_ "U_T6_MCA_MY2020_Tx" SG_ 1413 PDM_AutoSarNMReserved3 1;
BA_ "U_P702_MY2021_Tx" SG_ 1413 PDM_AutoSarNMReserved3 1;
BA_ "GenSigStartValue" SG_ 1413 PDM_AutoSarNMReserved3 255;
BA_ "ContentDependant" SG_ 1413 PDM_AutoSarNMReserved3 1;
BA_ "GenSigStartValueInteger" SG_ 1413 PDM_AutoSarNMReserved3 255;
BA_ "U_CD764_MY2022_Tx" SG_ 1413 PDM_AutoSarNMReserved2 1;
BA_ "U_U55X_MY2022_Tx" SG_ 1413 PDM_AutoSarNMReserved2 1;
BA_ "U_CD542_MY2021_Tx" SG_ 1413 PDM_AutoSarNMReserved2 1;
BA_ "U_T6_MCA_MY2020_Tx" SG_ 1413 PDM_AutoSarNMReserved2 1;
BA_ "U_P702_MY2021_Tx" SG_ 1413 PDM_AutoSarNMReserved2 1;
BA_ "GenSigStartValue" SG_ 1413 PDM_AutoSarNMReserved2 255;
BA_ "ContentDependant" SG_ 1413 PDM_AutoSarNMReserved2 1;
BA_ "GenSigStartValueInteger" SG_ 1413 PDM_AutoSarNMReserved2 255;
BA_ "U_CD764_MY2022_Tx" SG_ 1413 PDM_AutoSarNMReserved1 1;
BA_ "U_U55X_MY2022_Tx" SG_ 1413 PDM_AutoSarNMReserved1 1;
BA_ "U_CD542_MY2021_Tx" SG_ 1413 PDM_AutoSarNMReserved1 1;
BA_ "U_T6_MCA_MY2020_Tx" SG_ 1413 PDM_AutoSarNMReserved1 1;
BA_ "U_P702_MY2021_Tx" SG_ 1413 PDM_AutoSarNMReserved1 1;
BA_ "GenSigStartValue" SG_ 1413 PDM_AutoSarNMReserved1 255;
BA_ "ContentDependant" SG_ 1413 PDM_AutoSarNMReserved1 1;
BA_ "GenSigStartValueInteger" SG_ 1413 PDM_AutoSarNMReserved1 255;
BA_ "U_CD764_MY2022_Tx" SG_ 1413 PDM_AutoSarNMNodeId 1;
BA_ "U_U55X_MY2022_Tx" SG_ 1413 PDM_AutoSarNMNodeId 1;
BA_ "U_CD542_MY2021_Tx" SG_ 1413 PDM_AutoSarNMNodeId 1;
BA_ "U_T6_MCA_MY2020_Tx" SG_ 1413 PDM_AutoSarNMNodeId 1;
BA_ "U_P702_MY2021_Tx" SG_ 1413 PDM_AutoSarNMNodeId 1;
BA_ "GenSigStartValue" SG_ 1413 PDM_AutoSarNMNodeId 133;
BA_ "ContentDependant" SG_ 1413 PDM_AutoSarNMNodeId 1;
BA_ "GenSigStartValueInteger" SG_ 1413 PDM_AutoSarNMNodeId 133;
BA_ "U_CD764_MY2022_Tx" SG_ 1413 PDM_AutoSarNMControl 1;
BA_ "U_U55X_MY2022_Tx" SG_ 1413 PDM_AutoSarNMControl 1;
BA_ "U_CD542_MY2021_Tx" SG_ 1413 PDM_AutoSarNMControl 1;
BA_ "U_T6_MCA_MY2020_Tx" SG_ 1413 PDM_AutoSarNMControl 1;
BA_ "U_P702_MY2021_Tx" SG_ 1413 PDM_AutoSarNMControl 1;
BA_ "ContentDependant" SG_ 1413 PDM_AutoSarNMControl 1;
BA_ "U_CD764_MY2022_Tx" SG_ 1412 DDM_GWOnBoardTester 1;
BA_ "U_U55X_MY2022_Tx" SG_ 1412 DDM_GWOnBoardTester 1;
BA_ "U_CD542_MY2021_Tx" SG_ 1412 DDM_GWOnBoardTester 1;
BA_ "U_T6_MCA_MY2020_Tx" SG_ 1412 DDM_GWOnBoardTester 1;
BA_ "U_P702_MY2021_Tx" SG_ 1412 DDM_GWOnBoardTester 1;
BA_ "U_CX727_MY2021_Tx" SG_ 1412 DDM_GWOnBoardTester 1;
BA_ "GenSigStartValue" SG_ 1412 DDM_GWOnBoardTester 255;
BA_ "ContentDependant" SG_ 1412 DDM_GWOnBoardTester 1;
BA_ "GenSigStartValueInteger" SG_ 1412 DDM_GWOnBoardTester 255;
BA_ "U_CD764_MY2022_Tx" SG_ 1412 DDM_GWNMProxy 1;
BA_ "U_U55X_MY2022_Tx" SG_ 1412 DDM_GWNMProxy 1;
BA_ "U_CD542_MY2021_Tx" SG_ 1412 DDM_GWNMProxy 1;
BA_ "U_T6_MCA_MY2020_Tx" SG_ 1412 DDM_GWNMProxy 1;
BA_ "U_P702_MY2021_Tx" SG_ 1412 DDM_GWNMProxy 1;
BA_ "U_CX727_MY2021_Tx" SG_ 1412 DDM_GWNMProxy 1;
BA_ "GenSigStartValue" SG_ 1412 DDM_GWNMProxy 255;
BA_ "ContentDependant" SG_ 1412 DDM_GWNMProxy 1;
BA_ "GenSigStartValueInteger" SG_ 1412 DDM_GWNMProxy 255;
BA_ "U_CD764_MY2022_Tx" SG_ 1412 DDM_AutoSarNMReserved4 1;
BA_ "U_U55X_MY2022_Tx" SG_ 1412 DDM_AutoSarNMReserved4 1;
BA_ "U_CD542_MY2021_Tx" SG_ 1412 DDM_AutoSarNMReserved4 1;
BA_ "U_T6_MCA_MY2020_Tx" SG_ 1412 DDM_AutoSarNMReserved4 1;
BA_ "U_P702_MY2021_Tx" SG_ 1412 DDM_AutoSarNMReserved4 1;
BA_ "U_CX727_MY2021_Tx" SG_ 1412 DDM_AutoSarNMReserved4 1;
BA_ "GenSigStartValue" SG_ 1412 DDM_AutoSarNMReserved4 255;
BA_ "ContentDependant" SG_ 1412 DDM_AutoSarNMReserved4 1;
BA_ "GenSigStartValueInteger" SG_ 1412 DDM_AutoSarNMReserved4 255;
BA_ "U_CD764_MY2022_Tx" SG_ 1412 DDM_AutoSarNMReserved3 1;
BA_ "U_U55X_MY2022_Tx" SG_ 1412 DDM_AutoSarNMReserved3 1;
BA_ "U_CD542_MY2021_Tx" SG_ 1412 DDM_AutoSarNMReserved3 1;
BA_ "U_T6_MCA_MY2020_Tx" SG_ 1412 DDM_AutoSarNMReserved3 1;
BA_ "U_P702_MY2021_Tx" SG_ 1412 DDM_AutoSarNMReserved3 1;
BA_ "U_CX727_MY2021_Tx" SG_ 1412 DDM_AutoSarNMReserved3 1;
BA_ "GenSigStartValue" SG_ 1412 DDM_AutoSarNMReserved3 255;
BA_ "ContentDependant" SG_ 1412 DDM_AutoSarNMReserved3 1;
BA_ "GenSigStartValueInteger" SG_ 1412 DDM_AutoSarNMReserved3 255;
BA_ "U_CD764_MY2022_Tx" SG_ 1412 DDM_AutoSarNMReserved2 1;
BA_ "U_U55X_MY2022_Tx" SG_ 1412 DDM_AutoSarNMReserved2 1;
BA_ "U_CD542_MY2021_Tx" SG_ 1412 DDM_AutoSarNMReserved2 1;
BA_ "U_T6_MCA_MY2020_Tx" SG_ 1412 DDM_AutoSarNMReserved2 1;
BA_ "U_P702_MY2021_Tx" SG_ 1412 DDM_AutoSarNMReserved2 1;
BA_ "U_CX727_MY2021_Tx" SG_ 1412 DDM_AutoSarNMReserved2 1;
BA_ "GenSigStartValue" SG_ 1412 DDM_AutoSarNMReserved2 255;
BA_ "ContentDependant" SG_ 1412 DDM_AutoSarNMReserved2 1;
BA_ "GenSigStartValueInteger" SG_ 1412 DDM_AutoSarNMReserved2 255;
BA_ "U_CD764_MY2022_Tx" SG_ 1412 DDM_AutoSarNMReserved1 1;
BA_ "U_U55X_MY2022_Tx" SG_ 1412 DDM_AutoSarNMReserved1 1;
BA_ "U_CD542_MY2021_Tx" SG_ 1412 DDM_AutoSarNMReserved1 1;
BA_ "U_T6_MCA_MY2020_Tx" SG_ 1412 DDM_AutoSarNMReserved1 1;
BA_ "U_P702_MY2021_Tx" SG_ 1412 DDM_AutoSarNMReserved1 1;
BA_ "U_CX727_MY2021_Tx" SG_ 1412 DDM_AutoSarNMReserved1 1;
BA_ "GenSigStartValue" SG_ 1412 DDM_AutoSarNMReserved1 255;
BA_ "ContentDependant" SG_ 1412 DDM_AutoSarNMReserved1 1;
BA_ "GenSigStartValueInteger" SG_ 1412 DDM_AutoSarNMReserved1 255;
BA_ "U_CD764_MY2022_Tx" SG_ 1412 DDM_AutoSarNMNodeId 1;
BA_ "U_U55X_MY2022_Tx" SG_ 1412 DDM_AutoSarNMNodeId 1;
BA_ "U_CD542_MY2021_Tx" SG_ 1412 DDM_AutoSarNMNodeId 1;
BA_ "U_T6_MCA_MY2020_Tx" SG_ 1412 DDM_AutoSarNMNodeId 1;
BA_ "U_P702_MY2021_Tx" SG_ 1412 DDM_AutoSarNMNodeId 1;
BA_ "U_CX727_MY2021_Tx" SG_ 1412 DDM_AutoSarNMNodeId 1;
BA_ "GenSigStartValue" SG_ 1412 DDM_AutoSarNMNodeId 132;
BA_ "ContentDependant" SG_ 1412 DDM_AutoSarNMNodeId 1;
BA_ "GenSigStartValueInteger" SG_ 1412 DDM_AutoSarNMNodeId 132;
BA_ "U_CD764_MY2022_Tx" SG_ 1412 DDM_AutoSarNMControl 1;
BA_ "U_U55X_MY2022_Tx" SG_ 1412 DDM_AutoSarNMControl 1;
BA_ "U_CD542_MY2021_Tx" SG_ 1412 DDM_AutoSarNMControl 1;
BA_ "U_T6_MCA_MY2020_Tx" SG_ 1412 DDM_AutoSarNMControl 1;
BA_ "U_P702_MY2021_Tx" SG_ 1412 DDM_AutoSarNMControl 1;
BA_ "U_CX727_MY2021_Tx" SG_ 1412 DDM_AutoSarNMControl 1;
BA_ "ContentDependant" SG_ 1412 DDM_AutoSarNMControl 1;
BA_ "GenSigSendType" SG_ 1079 ApaMde_D_Stat 3;
BA_ "U_T6_MCA_MY2020_Rx" SG_ 1079 TrlrAidEnbl_D2_Stat_UB 1;
BA_ "U_T6_MCA_MY2020_Rx" SG_ 1079 TrlrAidEnbl_D2_Stat 1;
BA_ "GenSigSendType" SG_ 1079 PoliceAux4Swtch_B_Stat 3;
BA_ "GenSigSendType" SG_ 1079 PoliceAux3Swtch_B_Stat 3;
BA_ "GenSigSendType" SG_ 1079 PoliceAux2Swtch_B_Stat 3;
BA_ "GenSigSendType" SG_ 1079 PoliceAux1Swtch_B_Stat 3;
BA_ "GenSigSendType" SG_ 1079 GenericSwtch3_No_Actl 3;
BA_ "GenSigSendType" SG_ 1079 GenericSwtch2_No_Actl 3;
BA_ "ContentDependant" SG_ 1079 GenericSwtch2_No_Actl 1;
BA_ "GenSigSendType" SG_ 1079 GenericSwtch1_No_Actl 3;
BA_ "GenSigSendType" SG_ 1079 RbaSys_D_Stat 3;
BA_ "GenSigStartValue" SG_ 1079 RbaSys_D_Stat 2;
BA_ "GenSigStartValueInteger" SG_ 1079 RbaSys_D_Stat 2;
BA_ "U_CD764_MY2022_Rx" SG_ 1079 HybMdeStat_D_Dsply_UB 1;
BA_ "U_U55X_MY2022_Rx" SG_ 1079 HybMdeStat_D_Dsply_UB 1;
BA_ "U_CD542_MY2021_Rx" SG_ 1079 HybMdeStat_D_Dsply_UB 1;
BA_ "U_P702_MY2021_Rx" SG_ 1079 HybMdeStat_D_Dsply_UB 1;
BA_ "U_CX727_MY2021_Rx" SG_ 1079 HybMdeStat_D_Dsply_UB 1;
BA_ "GenSigSendType" SG_ 1079 Rba_D_Stat 3;
BA_ "GenSigStartValue" SG_ 1079 Rba_D_Stat 1;
BA_ "GenSigStartValueInteger" SG_ 1079 Rba_D_Stat 1;
BA_ "GenSigSendType" SG_ 1079 BalrMde_D_Rq 3;
BA_ "U_CD764_MY2022_Rx" SG_ 1079 ChrgGoTTouchEnbl_B_Rq 1;
BA_ "U_U55X_MY2022_Rx" SG_ 1079 ChrgGoTTouchEnbl_B_Rq 1;
BA_ "U_CD542_MY2021_Rx" SG_ 1079 ChrgGoTTouchEnbl_B_Rq 1;
BA_ "U_CX727_MY2021_Rx" SG_ 1079 ChrgGoTTouchEnbl_B_Rq 1;
BA_ "GenSigSendType" SG_ 1079 ChrgGoTTouchEnbl_B_Rq 3;
BA_ "U_CD764_MY2022_Rx" SG_ 1079 ChrgGoTExtHtrEnbl_B_Rq 1;
BA_ "U_U55X_MY2022_Rx" SG_ 1079 ChrgGoTExtHtrEnbl_B_Rq 1;
BA_ "U_CD542_MY2021_Rx" SG_ 1079 ChrgGoTExtHtrEnbl_B_Rq 1;
BA_ "U_CX727_MY2021_Rx" SG_ 1079 ChrgGoTExtHtrEnbl_B_Rq 1;
BA_ "GenSigSendType" SG_ 1079 ChrgGoTExtHtrEnbl_B_Rq 3;
BA_ "U_CD764_MY2022_Rx" SG_ 1079 ChrgGoTTouchEnbl_B_Rq_UB 1;
BA_ "U_U55X_MY2022_Rx" SG_ 1079 ChrgGoTTouchEnbl_B_Rq_UB 1;
BA_ "U_CD542_MY2021_Rx" SG_ 1079 ChrgGoTTouchEnbl_B_Rq_UB 1;
BA_ "U_CX727_MY2021_Rx" SG_ 1079 ChrgGoTTouchEnbl_B_Rq_UB 1;
BA_ "U_CD764_MY2022_Rx" SG_ 1079 ChrgGoTExtHtrEnbl_B_Rq_UB 1;
BA_ "U_U55X_MY2022_Rx" SG_ 1079 ChrgGoTExtHtrEnbl_B_Rq_UB 1;
BA_ "U_CD542_MY2021_Rx" SG_ 1079 ChrgGoTExtHtrEnbl_B_Rq_UB 1;
BA_ "U_CX727_MY2021_Rx" SG_ 1079 ChrgGoTExtHtrEnbl_B_Rq_UB 1;
BA_ "GenSigSendType" SG_ 1079 LcwaAlrtRight_B_Rq 3;
BA_ "GenSigSendType" SG_ 1079 LcwaAlrtLeft_B_Rq 3;
BA_ "U_CX727_MY2021_Rx" SG_ 1079 ApaSteScanMde_D_Stat 1;
BA_ "GenSigSendType" SG_ 1079 ApaSteScanMde_D_Stat 3;
BA_ "U_CX727_MY2021_Rx" SG_ 1079 ApaSteScanMde_D_Stat_UB 1;
BA_ "U_CD764_MY2022_Rx" SG_ 1079 BattTracClimtDis_B_Stat_UB 1;
BA_ "U_U55X_MY2022_Rx" SG_ 1079 BattTracClimtDis_B_Stat_UB 1;
BA_ "U_CD542_MY2021_Rx" SG_ 1079 BattTracClimtDis_B_Stat_UB 1;
BA_ "U_T6_MCA_MY2020_Rx" SG_ 1079 BattTracClimtDis_B_Stat_UB 1;
BA_ "U_CD764_MY2022_Rx" SG_ 1079 BattTracClimtDis_B_Stat 1;
BA_ "U_U55X_MY2022_Rx" SG_ 1079 BattTracClimtDis_B_Stat 1;
BA_ "U_CD542_MY2021_Rx" SG_ 1079 BattTracClimtDis_B_Stat 1;
BA_ "U_T6_MCA_MY2020_Rx" SG_ 1079 BattTracClimtDis_B_Stat 1;
BA_ "GenSigSendType" SG_ 1079 BattTracClimtDis_B_Stat 3;
BA_ "GenSigSendType" SG_ 1079 BalrSwtch_D_Stat 3;
BA_ "GenSigStartValue" SG_ 1079 BalrSwtch_D_Stat 1;
BA_ "GenSigStartValueInteger" SG_ 1079 BalrSwtch_D_Stat 1;
BA_ "U_T6_MCA_MY2020_Rx" SG_ 1079 TrlrAidMsgTxt_D2_Rq_UB 1;
BA_ "U_P702_MY2021_Rx" SG_ 1079 TrlrAidMsgTxt_D2_Rq_UB 1;
BA_ "U_T6_MCA_MY2020_Rx" SG_ 1079 TrlrAidMsgTxt_D2_Rq 1;
BA_ "U_P702_MY2021_Rx" SG_ 1079 TrlrAidMsgTxt_D2_Rq 1;
BA_ "GenSigSendType" SG_ 1079 TrlrAidMsgTxt_D2_Rq 3;
BA_ "U_CD764_MY2022_Rx" SG_ 1079 HybMdeStat_D_Dsply 1;
BA_ "U_U55X_MY2022_Rx" SG_ 1079 HybMdeStat_D_Dsply 1;
BA_ "U_CD542_MY2021_Rx" SG_ 1079 HybMdeStat_D_Dsply 1;
BA_ "U_P702_MY2021_Rx" SG_ 1079 HybMdeStat_D_Dsply 1;
BA_ "U_CX727_MY2021_Rx" SG_ 1079 HybMdeStat_D_Dsply 1;
BA_ "GenSigSendType" SG_ 1079 HybMdeStat_D_Dsply 3;
BA_ "GenSigStartValue" SG_ 1095 HeadLghtOn_D_Rq 1;
BA_ "GenSigStartValueInteger" SG_ 1095 HeadLghtOn_D_Rq 1;
BA_ "WakeupSignal" SG_ 1095 HeadLghtOn_D_Rq 1;
BA_ "U_U55X_MY2022_Rx" SG_ 1095 RstrtSetting_T_Actl 1;
BA_ "U_T6_MCA_MY2020_Rx" SG_ 1095 RstrtSetting_T_Actl 1;
BA_ "U_P702_MY2021_Rx" SG_ 1095 RstrtSetting_T_Actl 1;
BA_ "U_CX727_MY2021_Rx" SG_ 1095 RstrtSetting_T_Actl 1;
BA_ "U_U55X_MY2022_Rx" SG_ 1095 Rstrt_T_Actl 1;
BA_ "U_T6_MCA_MY2020_Rx" SG_ 1095 Rstrt_T_Actl 1;
BA_ "U_P702_MY2021_Rx" SG_ 1095 Rstrt_T_Actl 1;
BA_ "U_CX727_MY2021_Rx" SG_ 1095 Rstrt_T_Actl 1;
BA_ "GenSigStartValue" SG_ 948 Tire_Press_Placrd_Rear 255;
BA_ "GenSigStartValueInteger" SG_ 948 Tire_Press_Placrd_Rear 255;
BA_ "GenSigStartValue" SG_ 948 Tire_Press_Placrd_Frnt 255;
BA_ "GenSigStartValueInteger" SG_ 948 Tire_Press_Placrd_Frnt 255;
BA_ "U_U55X_MY2022_Rx" SG_ 948 Tire_Press_ILR_Stat 1;
BA_ "U_T6_MCA_MY2020_Rx" SG_ 948 Tire_Press_ILR_Stat 1;
BA_ "U_P702_MY2021_Rx" SG_ 948 Tire_Press_ILR_Stat 1;
BA_ "U_CX727_MY2021_Rx" SG_ 948 Tire_Press_ILR_Stat 1;
BA_ "U_U55X_MY2022_Rx" SG_ 948 Tire_Press_IRR_Stat 1;
BA_ "U_T6_MCA_MY2020_Rx" SG_ 948 Tire_Press_IRR_Stat 1;
BA_ "U_P702_MY2021_Rx" SG_ 948 Tire_Press_IRR_Stat 1;
BA_ "U_CX727_MY2021_Rx" SG_ 948 Tire_Press_IRR_Stat 1;
BA_ "U_U55X_MY2022_Rx" SG_ 948 Tire_Press_LR_OLR_Stat 1;
BA_ "U_T6_MCA_MY2020_Rx" SG_ 948 Tire_Press_LR_OLR_Stat 1;
BA_ "U_P702_MY2021_Rx" SG_ 948 Tire_Press_LR_OLR_Stat 1;
BA_ "U_CX727_MY2021_Rx" SG_ 948 Tire_Press_LR_OLR_Stat 1;
BA_ "U_U55X_MY2022_Rx" SG_ 948 Tire_Press_RR_ORR_Stat 1;
BA_ "U_T6_MCA_MY2020_Rx" SG_ 948 Tire_Press_RR_ORR_Stat 1;
BA_ "U_P702_MY2021_Rx" SG_ 948 Tire_Press_RR_ORR_Stat 1;
BA_ "U_CX727_MY2021_Rx" SG_ 948 Tire_Press_RR_ORR_Stat 1;
BA_ "U_U55X_MY2022_Rx" SG_ 948 Tire_Press_RF_Stat 1;
BA_ "U_T6_MCA_MY2020_Rx" SG_ 948 Tire_Press_RF_Stat 1;
BA_ "U_P702_MY2021_Rx" SG_ 948 Tire_Press_RF_Stat 1;
BA_ "U_CX727_MY2021_Rx" SG_ 948 Tire_Press_RF_Stat 1;
BA_ "U_U55X_MY2022_Rx" SG_ 948 Tire_Press_LF_Stat 1;
BA_ "U_T6_MCA_MY2020_Rx" SG_ 948 Tire_Press_LF_Stat 1;
BA_ "U_P702_MY2021_Rx" SG_ 948 Tire_Press_LF_Stat 1;
BA_ "U_CX727_MY2021_Rx" SG_ 948 Tire_Press_LF_Stat 1;
BA_ "U_U55X_MY2022_Rx" SG_ 948 Tire_Press_System_Stat 1;
BA_ "U_T6_MCA_MY2020_Rx" SG_ 948 Tire_Press_System_Stat 1;
BA_ "U_P702_MY2021_Rx" SG_ 948 Tire_Press_System_Stat 1;
BA_ "U_CX727_MY2021_Rx" SG_ 948 Tire_Press_System_Stat 1;
BA_ "U_U55X_MY2022_Rx" SG_ 948 Tire_Press_Telltale 1;
BA_ "U_T6_MCA_MY2020_Rx" SG_ 948 Tire_Press_Telltale 1;
BA_ "U_P702_MY2021_Rx" SG_ 948 Tire_Press_Telltale 1;
BA_ "U_CX727_MY2021_Rx" SG_ 948 Tire_Press_Telltale 1;
BA_ "U_U55X_MY2022_Rx" SG_ 948 TirePReset_D_Stat 1;
BA_ "U_T6_MCA_MY2020_Rx" SG_ 948 TirePReset_D_Stat 1;
BA_ "U_P702_MY2021_Rx" SG_ 948 TirePReset_D_Stat 1;
BA_ "U_CX727_MY2021_Rx" SG_ 948 TirePReset_D_Stat 1;
BA_ "ContentDependant" SG_ 840 FohT2Friday_T_Rq 1;
BA_ "ContentDependant" SG_ 840 FohT1Friday_T_Rq 1;
BA_ "ContentDependant" SG_ 840 FohT2Wednesday_T_Rq 1;
BA_ "ContentDependant" SG_ 840 FohT2Tuesday_T_Rq 1;
BA_ "ContentDependant" SG_ 840 FohT2Thursday_T_Rq 1;
BA_ "ContentDependant" SG_ 840 FohT2Sunday_T_Rq 1;
BA_ "ContentDependant" SG_ 840 FohT2Saturday_T_Rq 1;
BA_ "ContentDependant" SG_ 840 FohT2Monday_T_Rq 1;
BA_ "ContentDependant" SG_ 840 FohT1Wednesday_T_Rq 1;
BA_ "ContentDependant" SG_ 840 FohT1Tuesday_T_Rq 1;
BA_ "ContentDependant" SG_ 840 FohT1Thursday_T_Rq 1;
BA_ "ContentDependant" SG_ 840 FohT1Sunday_T_Rq 1;
BA_ "ContentDependant" SG_ 840 FohT1Saturday_T_Rq 1;
BA_ "ContentDependant" SG_ 840 FohT1Monday_T_Rq 1;
BA_ "U_CD542_MY2021_Rx" SG_ 132 GlblClkYr_No_Actl 1;
BA_ "U_T6_MCA_MY2020_Rx" SG_ 132 GlblClkYr_No_Actl 1;
BA_ "U_P702_MY2021_Rx" SG_ 132 GlblClkYr_No_Actl 1;
BA_ "U_CD542_MY2021_Rx" SG_ 132 GlblClkScnd_No_Actl 1;
BA_ "U_T6_MCA_MY2020_Rx" SG_ 132 GlblClkScnd_No_Actl 1;
BA_ "U_P702_MY2021_Rx" SG_ 132 GlblClkScnd_No_Actl 1;
BA_ "U_CD542_MY2021_Rx" SG_ 132 GlblClkMnte_No_Actl 1;
BA_ "U_T6_MCA_MY2020_Rx" SG_ 132 GlblClkMnte_No_Actl 1;
BA_ "U_P702_MY2021_Rx" SG_ 132 GlblClkMnte_No_Actl 1;
BA_ "U_CD542_MY2021_Rx" SG_ 132 GlblClkHr_No_Actl 1;
BA_ "U_T6_MCA_MY2020_Rx" SG_ 132 GlblClkHr_No_Actl 1;
BA_ "U_P702_MY2021_Rx" SG_ 132 GlblClkHr_No_Actl 1;
BA_ "U_CD542_MY2021_Rx" SG_ 132 GlblClkDay_No_Actl 1;
BA_ "U_T6_MCA_MY2020_Rx" SG_ 132 GlblClkDay_No_Actl 1;
BA_ "U_P702_MY2021_Rx" SG_ 132 GlblClkDay_No_Actl 1;
BA_ "WakeupSignal" SG_ 945 PwLoApim_T_Actl 1;
BA_ "WakeupSignal" SG_ 945 PrkLckCtlMsgTxt_D2_Rq 1;
BA_ "WakeupSignal" SG_ 945 KeyPadCodeDgt6_D_Dsply 1;
BA_ "WakeupSignal" SG_ 945 KeyPadCodeDgt5_D_Dsply 1;
BA_ "WakeupSignal" SG_ 945 KeyPadCodeDgt4_D_Dsply 1;
BA_ "WakeupSignal" SG_ 945 KeyPadCodeDgt3_D_Dsply 1;
BA_ "WakeupSignal" SG_ 945 KeyPadCodeDgt2_D_Dsply 1;
BA_ "WakeupSignal" SG_ 945 KeyPadCodeDgt1_D_Dsply 1;
BA_ "U_CD764_MY2022_Rx" SG_ 945 KeyOffMde_D_Actl 1;
BA_ "U_P702_MY2021_Rx" SG_ 945 KeyOffMde_D_Actl 1;
BA_ "U_U55X_MY2022_Rx" SG_ 945 KeyOffMde_D_Actl 1;
BA_ "U_CD542_MY2021_Rx" SG_ 945 KeyOffMde_D_Actl 1;
BA_ "U_CX727_MY2021_Rx" SG_ 945 KeyOffMde_D_Actl 1;
BA_ "U_T6_MCA_MY2020_Rx" SG_ 945 KeyOffMde_D_Actl 1;
BA_ "GenSigSendType" SG_ 945 KeyOffMde_D_Actl 3;
BA_ "U_CD764_MY2022_Rx" SG_ 981 PreCondActv_B_Actl_UB 1;
BA_ "U_U55X_MY2022_Rx" SG_ 981 PreCondActv_B_Actl_UB 1;
BA_ "U_CD542_MY2021_Rx" SG_ 981 PreCondActv_B_Actl_UB 1;
BA_ "U_T6_MCA_MY2020_Rx" SG_ 981 PreCondActv_B_Actl_UB 1;
BA_ "U_CX727_MY2021_Rx" SG_ 981 PreCondActv_B_Actl_UB 1;
BA_ "U_CD764_MY2022_Rx" SG_ 981 HvacPrecondRecirc_D_Rq_UB 1;
BA_ "U_U55X_MY2022_Rx" SG_ 981 HvacPrecondRecirc_D_Rq_UB 1;
BA_ "U_CD542_MY2021_Rx" SG_ 981 HvacPrecondRecirc_D_Rq_UB 1;
BA_ "U_CX727_MY2021_Rx" SG_ 981 HvacPrecondRecirc_D_Rq_UB 1;
BA_ "U_CD764_MY2022_Rx" SG_ 981 HvacPrecondMode2_D_Rq_UB 1;
BA_ "U_U55X_MY2022_Rx" SG_ 981 HvacPrecondMode2_D_Rq_UB 1;
BA_ "U_CD542_MY2021_Rx" SG_ 981 HvacPrecondMode2_D_Rq_UB 1;
BA_ "U_CX727_MY2021_Rx" SG_ 981 HvacPrecondMode2_D_Rq_UB 1;
BA_ "U_CD764_MY2022_Rx" SG_ 981 HvacPrecondBlwr2_D_Rq_UB 1;
BA_ "U_U55X_MY2022_Rx" SG_ 981 HvacPrecondBlwr2_D_Rq_UB 1;
BA_ "U_CD542_MY2021_Rx" SG_ 981 HvacPrecondBlwr2_D_Rq_UB 1;
BA_ "U_CX727_MY2021_Rx" SG_ 981 HvacPrecondBlwr2_D_Rq_UB 1;
BA_ "U_CD764_MY2022_Rx" SG_ 981 HvacPrecondAC_D_Rq_UB 1;
BA_ "U_U55X_MY2022_Rx" SG_ 981 HvacPrecondAC_D_Rq_UB 1;
BA_ "U_CD542_MY2021_Rx" SG_ 981 HvacPrecondAC_D_Rq_UB 1;
BA_ "U_CX727_MY2021_Rx" SG_ 981 HvacPrecondAC_D_Rq_UB 1;
BA_ "U_CD764_MY2022_Rx" SG_ 981 HvacPrecond_Te_Rq_UB 1;
BA_ "U_U55X_MY2022_Rx" SG_ 981 HvacPrecond_Te_Rq_UB 1;
BA_ "U_CD542_MY2021_Rx" SG_ 981 HvacPrecond_Te_Rq_UB 1;
BA_ "U_CX727_MY2021_Rx" SG_ 981 HvacPrecond_Te_Rq_UB 1;
BA_ "U_CD764_MY2022_Rx" SG_ 981 DrvCondTpRrDefrs_B_Rq_UB 1;
BA_ "U_U55X_MY2022_Rx" SG_ 981 DrvCondTpRrDefrs_B_Rq_UB 1;
BA_ "U_CD542_MY2021_Rx" SG_ 981 DrvCondTpRrDefrs_B_Rq_UB 1;
BA_ "U_CX727_MY2021_Rx" SG_ 981 DrvCondTpRrDefrs_B_Rq_UB 1;
BA_ "U_CD764_MY2022_Rx" SG_ 981 PreCondActv_B_Actl 1;
BA_ "U_U55X_MY2022_Rx" SG_ 981 PreCondActv_B_Actl 1;
BA_ "U_CD542_MY2021_Rx" SG_ 981 PreCondActv_B_Actl 1;
BA_ "U_T6_MCA_MY2020_Rx" SG_ 981 PreCondActv_B_Actl 1;
BA_ "U_CX727_MY2021_Rx" SG_ 981 PreCondActv_B_Actl 1;
BA_ "U_CD764_MY2022_Rx" SG_ 981 HvacPrecondRecirc_D_Rq 1;
BA_ "U_U55X_MY2022_Rx" SG_ 981 HvacPrecondRecirc_D_Rq 1;
BA_ "U_CD542_MY2021_Rx" SG_ 981 HvacPrecondRecirc_D_Rq 1;
BA_ "U_CX727_MY2021_Rx" SG_ 981 HvacPrecondRecirc_D_Rq 1;
BA_ "U_CD764_MY2022_Rx" SG_ 981 HvacPrecondMode2_D_Rq 1;
BA_ "U_U55X_MY2022_Rx" SG_ 981 HvacPrecondMode2_D_Rq 1;
BA_ "U_CD542_MY2021_Rx" SG_ 981 HvacPrecondMode2_D_Rq 1;
BA_ "U_CX727_MY2021_Rx" SG_ 981 HvacPrecondMode2_D_Rq 1;
BA_ "ContentDependant" SG_ 981 HvacPrecondMode2_D_Rq 1;
BA_ "WakeupSignal" SG_ 981 HvacPrecondMode2_D_Rq 1;
BA_ "U_CD764_MY2022_Rx" SG_ 981 HvacPrecondBlwr2_D_Rq 1;
BA_ "U_U55X_MY2022_Rx" SG_ 981 HvacPrecondBlwr2_D_Rq 1;
BA_ "U_CD542_MY2021_Rx" SG_ 981 HvacPrecondBlwr2_D_Rq 1;
BA_ "U_CX727_MY2021_Rx" SG_ 981 HvacPrecondBlwr2_D_Rq 1;
BA_ "ContentDependant" SG_ 981 HvacPrecondBlwr2_D_Rq 1;
BA_ "WakeupSignal" SG_ 981 HvacPrecondBlwr2_D_Rq 1;
BA_ "U_CD764_MY2022_Rx" SG_ 981 HvacPrecondAC_D_Rq 1;
BA_ "U_U55X_MY2022_Rx" SG_ 981 HvacPrecondAC_D_Rq 1;
BA_ "U_CD542_MY2021_Rx" SG_ 981 HvacPrecondAC_D_Rq 1;
BA_ "U_CX727_MY2021_Rx" SG_ 981 HvacPrecondAC_D_Rq 1;
BA_ "U_CD764_MY2022_Rx" SG_ 981 HvacPrecond_Te_Rq 1;
BA_ "U_U55X_MY2022_Rx" SG_ 981 HvacPrecond_Te_Rq 1;
BA_ "U_CD542_MY2021_Rx" SG_ 981 HvacPrecond_Te_Rq 1;
BA_ "U_CX727_MY2021_Rx" SG_ 981 HvacPrecond_Te_Rq 1;
BA_ "GenSigStartValue" SG_ 981 HvacPrecond_Te_Rq 2;
BA_ "GenSigStartValueInteger" SG_ 981 HvacPrecond_Te_Rq 2;
BA_ "U_CD764_MY2022_Rx" SG_ 981 DrvCondTpRrDefrs_B_Rq 1;
BA_ "U_U55X_MY2022_Rx" SG_ 981 DrvCondTpRrDefrs_B_Rq 1;
BA_ "U_CD542_MY2021_Rx" SG_ 981 DrvCondTpRrDefrs_B_Rq 1;
BA_ "U_CX727_MY2021_Rx" SG_ 981 DrvCondTpRrDefrs_B_Rq 1;
BA_ "U_U55X_MY2022_Tx" SG_ 1446 RGTM_GWOnBoardTester 1;
BA_ "U_CD542_MY2021_Tx" SG_ 1446 RGTM_GWOnBoardTester 1;
BA_ "U_T6_MCA_MY2020_Tx" SG_ 1446 RGTM_GWOnBoardTester 1;
BA_ "U_CX727_MY2021_Tx" SG_ 1446 RGTM_GWOnBoardTester 1;
BA_ "GenSigStartValue" SG_ 1446 RGTM_GWOnBoardTester 255;
BA_ "ContentDependant" SG_ 1446 RGTM_GWOnBoardTester 1;
BA_ "GenSigStartValueInteger" SG_ 1446 RGTM_GWOnBoardTester 255;
BA_ "U_U55X_MY2022_Tx" SG_ 1446 RGTM_GWNMProxy 1;
BA_ "U_CD542_MY2021_Tx" SG_ 1446 RGTM_GWNMProxy 1;
BA_ "U_T6_MCA_MY2020_Tx" SG_ 1446 RGTM_GWNMProxy 1;
BA_ "U_CX727_MY2021_Tx" SG_ 1446 RGTM_GWNMProxy 1;
BA_ "GenSigStartValue" SG_ 1446 RGTM_GWNMProxy 255;
BA_ "ContentDependant" SG_ 1446 RGTM_GWNMProxy 1;
BA_ "GenSigStartValueInteger" SG_ 1446 RGTM_GWNMProxy 255;
BA_ "U_U55X_MY2022_Tx" SG_ 1446 RGTM_AutoSarNMReserved4 1;
BA_ "U_CD542_MY2021_Tx" SG_ 1446 RGTM_AutoSarNMReserved4 1;
BA_ "U_T6_MCA_MY2020_Tx" SG_ 1446 RGTM_AutoSarNMReserved4 1;
BA_ "U_CX727_MY2021_Tx" SG_ 1446 RGTM_AutoSarNMReserved4 1;
BA_ "GenSigStartValue" SG_ 1446 RGTM_AutoSarNMReserved4 255;
BA_ "ContentDependant" SG_ 1446 RGTM_AutoSarNMReserved4 1;
BA_ "GenSigStartValueInteger" SG_ 1446 RGTM_AutoSarNMReserved4 255;
BA_ "U_U55X_MY2022_Tx" SG_ 1446 RGTM_AutoSarNMReserved3 1;
BA_ "U_CD542_MY2021_Tx" SG_ 1446 RGTM_AutoSarNMReserved3 1;
BA_ "U_T6_MCA_MY2020_Tx" SG_ 1446 RGTM_AutoSarNMReserved3 1;
BA_ "U_CX727_MY2021_Tx" SG_ 1446 RGTM_AutoSarNMReserved3 1;
BA_ "GenSigStartValue" SG_ 1446 RGTM_AutoSarNMReserved3 255;
BA_ "ContentDependant" SG_ 1446 RGTM_AutoSarNMReserved3 1;
BA_ "GenSigStartValueInteger" SG_ 1446 RGTM_AutoSarNMReserved3 255;
BA_ "U_U55X_MY2022_Tx" SG_ 1446 RGTM_AutoSarNMReserved2 1;
BA_ "U_CD542_MY2021_Tx" SG_ 1446 RGTM_AutoSarNMReserved2 1;
BA_ "U_T6_MCA_MY2020_Tx" SG_ 1446 RGTM_AutoSarNMReserved2 1;
BA_ "U_CX727_MY2021_Tx" SG_ 1446 RGTM_AutoSarNMReserved2 1;
BA_ "GenSigStartValue" SG_ 1446 RGTM_AutoSarNMReserved2 255;
BA_ "ContentDependant" SG_ 1446 RGTM_AutoSarNMReserved2 1;
BA_ "GenSigStartValueInteger" SG_ 1446 RGTM_AutoSarNMReserved2 255;
BA_ "U_U55X_MY2022_Tx" SG_ 1446 RGTM_AutoSarNMReserved1 1;
BA_ "U_CD542_MY2021_Tx" SG_ 1446 RGTM_AutoSarNMReserved1 1;
BA_ "U_T6_MCA_MY2020_Tx" SG_ 1446 RGTM_AutoSarNMReserved1 1;
BA_ "U_CX727_MY2021_Tx" SG_ 1446 RGTM_AutoSarNMReserved1 1;
BA_ "GenSigStartValue" SG_ 1446 RGTM_AutoSarNMReserved1 255;
BA_ "ContentDependant" SG_ 1446 RGTM_AutoSarNMReserved1 1;
BA_ "GenSigStartValueInteger" SG_ 1446 RGTM_AutoSarNMReserved1 255;
BA_ "U_U55X_MY2022_Tx" SG_ 1446 RGTM_AutoSarNMNodeId 1;
BA_ "U_CD542_MY2021_Tx" SG_ 1446 RGTM_AutoSarNMNodeId 1;
BA_ "U_T6_MCA_MY2020_Tx" SG_ 1446 RGTM_AutoSarNMNodeId 1;
BA_ "U_CX727_MY2021_Tx" SG_ 1446 RGTM_AutoSarNMNodeId 1;
BA_ "GenSigStartValue" SG_ 1446 RGTM_AutoSarNMNodeId 166;
BA_ "ContentDependant" SG_ 1446 RGTM_AutoSarNMNodeId 1;
BA_ "GenSigStartValueInteger" SG_ 1446 RGTM_AutoSarNMNodeId 166;
BA_ "U_U55X_MY2022_Tx" SG_ 1446 RGTM_AutoSarNMControl 1;
BA_ "U_CD542_MY2021_Tx" SG_ 1446 RGTM_AutoSarNMControl 1;
BA_ "U_T6_MCA_MY2020_Tx" SG_ 1446 RGTM_AutoSarNMControl 1;
BA_ "U_CX727_MY2021_Tx" SG_ 1446 RGTM_AutoSarNMControl 1;
BA_ "ContentDependant" SG_ 1446 RGTM_AutoSarNMControl 1;
BA_ "GenSigStartValue" SG_ 839 FohStop_B_Stat 3;
BA_ "ContentDependant" SG_ 839 FohStop_B_Stat 1;
BA_ "GenSigStartValueInteger" SG_ 839 FohStop_B_Stat 3;
BA_ "WakeupSignal" SG_ 839 FohStop_B_Stat 1;
BA_ "ContentDependant" SG_ 839 FohMsgTxt_D_Rq 1;
BA_ "ContentDependant" SG_ 839 FohKeyOff_B_Rq 1;
BA_ "WakeupSignal" SG_ 839 FohKeyOff_B_Rq 1;
BA_ "ContentDependant" SG_ 839 FohEnbl_B_Rq 1;
BA_ "WakeupSignal" SG_ 839 FohEnbl_B_Rq 1;
BA_ "GenSigStartValue" SG_ 839 FohTAllEnable_B_Stat 3;
BA_ "ContentDependant" SG_ 839 FohTAllEnable_B_Stat 1;
BA_ "GenSigStartValueInteger" SG_ 839 FohTAllEnable_B_Stat 3;
BA_ "ContentDependant" SG_ 839 FohT2Mnte_T_Stat 1;
BA_ "ContentDependant" SG_ 839 FohT2Hr_T_Stat 1;
BA_ "ContentDependant" SG_ 839 FohT2Enable_B_Stat 1;
BA_ "ContentDependant" SG_ 839 FohT1Mnte_T_Stat 1;
BA_ "ContentDependant" SG_ 839 FohT1Hr_T_Stat 1;
BA_ "ContentDependant" SG_ 839 FohT1Enable_B_Stat 1;
BA_ "ContentDependant" SG_ 839 FohStrtMnte_T_Stat 1;
BA_ "ContentDependant" SG_ 839 FohStrtHr_T_Stat 1;
BA_ "ContentDependant" SG_ 839 FohStrtEnable_B_Stat 1;
BA_ "GenSigStartValue" SG_ 839 FohContOn_B_Stat 3;
BA_ "ContentDependant" SG_ 839 FohContOn_B_Stat 1;
BA_ "GenSigStartValueInteger" SG_ 839 FohContOn_B_Stat 3;
BA_ "ContentDependant" SG_ 839 FohT2Wednesday_T_Stat 1;
BA_ "ContentDependant" SG_ 839 FohT2Tuesday_T_Stat 1;
BA_ "ContentDependant" SG_ 839 FohT2Thursday_T_Stat 1;
BA_ "ContentDependant" SG_ 839 FohT2Sunday_T_Stat 1;
BA_ "ContentDependant" SG_ 839 FohT2Saturday_T_Stat 1;
BA_ "ContentDependant" SG_ 839 FohT2Monday_T_Stat 1;
BA_ "ContentDependant" SG_ 839 FohT2Friday_T_Stat 1;
BA_ "ContentDependant" SG_ 839 FohT1Wednesday_T_Stat 1;
BA_ "ContentDependant" SG_ 839 FohT1Tuesday_T_Stat 1;
BA_ "ContentDependant" SG_ 839 FohT1Thursday_T_Stat 1;
BA_ "ContentDependant" SG_ 839 FohT1Sunday_T_Stat 1;
BA_ "ContentDependant" SG_ 839 FohT1Saturday_T_Stat 1;
BA_ "ContentDependant" SG_ 839 FohT1Monday_T_Stat 1;
BA_ "ContentDependant" SG_ 839 FohT1Friday_T_Stat 1;
BA_ "GenSigStartValue" SG_ 838 FohStop_B_Rq 3;
BA_ "GenSigStartValueInteger" SG_ 838 FohStop_B_Rq 3;
BA_ "GenSigStartValue" SG_ 838 FohTAllEnable_B_Rq 3;
BA_ "GenSigStartValueInteger" SG_ 838 FohTAllEnable_B_Rq 3;
BA_ "GenSigStartValue" SG_ 838 FohContOn_B_Rq 3;
BA_ "GenSigStartValueInteger" SG_ 838 FohContOn_B_Rq 3;
BA_ "U_CD764_MY2022_Tx" SG_ 850 SeatCshnPsgrRR_Pc_Actl 1;
BA_ "U_U55X_MY2022_Tx" SG_ 850 SeatCshnPsgrRR_Pc_Actl 1;
BA_ "U_P702_MY2021_Tx" SG_ 850 SeatCshnPsgrRR_Pc_Actl 1;
BA_ "GenSigStartValue" SG_ 850 SeatCshnPsgrRR_Pc_Actl 127;
BA_ "GenSigStartValueInteger" SG_ 850 SeatCshnPsgrRR_Pc_Actl 127;
BA_ "U_CD764_MY2022_Tx" SG_ 850 SeatCshnPsgrRL_Pc_Actl 1;
BA_ "U_U55X_MY2022_Tx" SG_ 850 SeatCshnPsgrRL_Pc_Actl 1;
BA_ "U_P702_MY2021_Tx" SG_ 850 SeatCshnPsgrRL_Pc_Actl 1;
BA_ "GenSigStartValue" SG_ 850 SeatCshnPsgrRL_Pc_Actl 127;
BA_ "GenSigStartValueInteger" SG_ 850 SeatCshnPsgrRL_Pc_Actl 127;
BA_ "U_CD764_MY2022_Tx" SG_ 850 SeatCshnPsgrFR_Pc_Actl 1;
BA_ "U_U55X_MY2022_Tx" SG_ 850 SeatCshnPsgrFR_Pc_Actl 1;
BA_ "U_P702_MY2021_Tx" SG_ 850 SeatCshnPsgrFR_Pc_Actl 1;
BA_ "GenSigStartValue" SG_ 850 SeatCshnPsgrFR_Pc_Actl 127;
BA_ "GenSigStartValueInteger" SG_ 850 SeatCshnPsgrFR_Pc_Actl 127;
BA_ "U_CD764_MY2022_Tx" SG_ 850 SeatCshnPsgrFL_Pc_Actl 1;
BA_ "U_U55X_MY2022_Tx" SG_ 850 SeatCshnPsgrFL_Pc_Actl 1;
BA_ "U_P702_MY2021_Tx" SG_ 850 SeatCshnPsgrFL_Pc_Actl 1;
BA_ "GenSigStartValue" SG_ 850 SeatCshnPsgrFL_Pc_Actl 127;
BA_ "GenSigStartValueInteger" SG_ 850 SeatCshnPsgrFL_Pc_Actl 127;
BA_ "U_CD764_MY2022_Tx" SG_ 850 SeatBlLoPsgr_Pc_Actl2 1;
BA_ "U_U55X_MY2022_Tx" SG_ 850 SeatBlLoPsgr_Pc_Actl2 1;
BA_ "U_P702_MY2021_Tx" SG_ 850 SeatBlLoPsgr_Pc_Actl2 1;
BA_ "GenSigStartValue" SG_ 850 SeatBlLoPsgr_Pc_Actl2 127;
BA_ "GenSigStartValueInteger" SG_ 850 SeatBlLoPsgr_Pc_Actl2 127;
BA_ "U_CD764_MY2022_Tx" SG_ 849 SeatCshnDrvRR_Pc_Actl 1;
BA_ "U_U55X_MY2022_Tx" SG_ 849 SeatCshnDrvRR_Pc_Actl 1;
BA_ "U_P702_MY2021_Tx" SG_ 849 SeatCshnDrvRR_Pc_Actl 1;
BA_ "GenSigStartValue" SG_ 849 SeatCshnDrvRR_Pc_Actl 127;
BA_ "GenSigStartValueInteger" SG_ 849 SeatCshnDrvRR_Pc_Actl 127;
BA_ "U_CD764_MY2022_Tx" SG_ 849 SeatCshnDrvRL_Pc_Actl 1;
BA_ "U_U55X_MY2022_Tx" SG_ 849 SeatCshnDrvRL_Pc_Actl 1;
BA_ "U_P702_MY2021_Tx" SG_ 849 SeatCshnDrvRL_Pc_Actl 1;
BA_ "GenSigStartValue" SG_ 849 SeatCshnDrvRL_Pc_Actl 127;
BA_ "GenSigStartValueInteger" SG_ 849 SeatCshnDrvRL_Pc_Actl 127;
BA_ "U_CD764_MY2022_Tx" SG_ 849 SeatCshnDrvFR_Pc_Actl 1;
BA_ "U_U55X_MY2022_Tx" SG_ 849 SeatCshnDrvFR_Pc_Actl 1;
BA_ "U_P702_MY2021_Tx" SG_ 849 SeatCshnDrvFR_Pc_Actl 1;
BA_ "GenSigStartValue" SG_ 849 SeatCshnDrvFR_Pc_Actl 127;
BA_ "GenSigStartValueInteger" SG_ 849 SeatCshnDrvFR_Pc_Actl 127;
BA_ "U_CD764_MY2022_Tx" SG_ 849 SeatCshnDrvFL_Pc_Actl 1;
BA_ "U_U55X_MY2022_Tx" SG_ 849 SeatCshnDrvFL_Pc_Actl 1;
BA_ "U_P702_MY2021_Tx" SG_ 849 SeatCshnDrvFL_Pc_Actl 1;
BA_ "GenSigStartValue" SG_ 849 SeatCshnDrvFL_Pc_Actl 127;
BA_ "GenSigStartValueInteger" SG_ 849 SeatCshnDrvFL_Pc_Actl 127;
BA_ "U_U55X_MY2022_Rx" SG_ 846 SeatMasgDrv_D_Rq 1;
BA_ "U_P702_MY2021_Rx" SG_ 846 SeatMasgDrv_D_Rq 1;
BA_ "U_U55X_MY2022_Rx" SG_ 846 SeatMasgPsngr_D_Rq 1;
BA_ "U_P702_MY2021_Rx" SG_ 846 SeatMasgPsngr_D_Rq 1;
BA_ "U_CD764_MY2022_Rx" SG_ 846 SeatLmbr_D_Rq 1;
BA_ "U_CD542_MY2021_Rx" SG_ 846 SeatLmbr_D_Rq 1;
BA_ "U_T6_MCA_MY2020_Rx" SG_ 846 SeatLmbr_D_Rq 1;
BA_ "U_P702_MY2021_Rx" SG_ 846 SeatLmbr_D_Rq 1;
BA_ "U_CX727_MY2021_Rx" SG_ 846 SeatLmbr_D_Rq 1;
BA_ "U_U55X_MY2022_Rx" SG_ 846 SeatLmbr_D_Rq 1;
BA_ "U_CD764_MY2022_Rx" SG_ 846 SeatFnChngPsgr2_D_Rq 1;
BA_ "U_U55X_MY2022_Rx" SG_ 846 SeatFnChngPsgr2_D_Rq 1;
BA_ "U_P702_MY2021_Rx" SG_ 846 SeatFnChngPsgr2_D_Rq 1;
BA_ "U_CD764_MY2022_Rx" SG_ 846 SeatFnChngDrv2_D_Rq 1;
BA_ "U_U55X_MY2022_Rx" SG_ 846 SeatFnChngDrv2_D_Rq 1;
BA_ "U_P702_MY2021_Rx" SG_ 846 SeatFnChngDrv2_D_Rq 1;
BA_ "U_CD764_MY2022_Rx" SG_ 846 SeatFnPsgr_D_Rq 1;
BA_ "U_U55X_MY2022_Rx" SG_ 846 SeatFnPsgr_D_Rq 1;
BA_ "U_P702_MY2021_Rx" SG_ 846 SeatFnPsgr_D_Rq 1;
BA_ "U_CD764_MY2022_Rx" SG_ 846 SeatFnDrv_D_Rq 1;
BA_ "U_U55X_MY2022_Rx" SG_ 846 SeatFnDrv_D_Rq 1;
BA_ "U_P702_MY2021_Rx" SG_ 846 SeatFnDrv_D_Rq 1;
BA_ "U_CD764_MY2022_Rx" SG_ 846 SeatFnDfaltPsgr_B_Rq 1;
BA_ "U_U55X_MY2022_Rx" SG_ 846 SeatFnDfaltPsgr_B_Rq 1;
BA_ "U_P702_MY2021_Rx" SG_ 846 SeatFnDfaltPsgr_B_Rq 1;
BA_ "U_CD764_MY2022_Rx" SG_ 846 SeatFnDfaltDrv_B_Rq 1;
BA_ "U_U55X_MY2022_Rx" SG_ 846 SeatFnDfaltDrv_B_Rq 1;
BA_ "U_P702_MY2021_Rx" SG_ 846 SeatFnDfaltDrv_B_Rq 1;
BA_ "U_CD764_MY2022_Rx" SG_ 846 SeatFnChngPsgr_D_Rq 1;
BA_ "U_U55X_MY2022_Rx" SG_ 846 SeatFnChngPsgr_D_Rq 1;
BA_ "U_P702_MY2021_Rx" SG_ 846 SeatFnChngPsgr_D_Rq 1;
BA_ "U_CD764_MY2022_Rx" SG_ 846 SeatFnChngDrv_D_Rq 1;
BA_ "U_U55X_MY2022_Rx" SG_ 846 SeatFnChngDrv_D_Rq 1;
BA_ "U_P702_MY2021_Rx" SG_ 846 SeatFnChngDrv_D_Rq 1;
BA_ "U_CD764_MY2022_Rx" SG_ 846 PsgrMemory_Rq 1;
BA_ "U_U55X_MY2022_Rx" SG_ 846 PsgrMemory_Rq 1;
BA_ "U_P702_MY2021_Rx" SG_ 846 PsgrMemory_Rq 1;
BA_ "U_U55X_MY2022_Tx" SG_ 845 SeatMasgPsngr_D_Stat 1;
BA_ "U_P702_MY2021_Tx" SG_ 845 SeatMasgPsngr_D_Stat 1;
BA_ "GenSigSendType" SG_ 845 SeatMasgPsngr_D_Stat 3;
BA_ "U_U55X_MY2022_Tx" SG_ 845 SeatIntnsPsngr_D_Stat 1;
BA_ "U_P702_MY2021_Tx" SG_ 845 SeatIntnsPsngr_D_Stat 1;
BA_ "GenSigSendType" SG_ 845 SeatIntnsPsngr_D_Stat 3;
BA_ "U_CD764_MY2022_Tx" SG_ 845 StmsLmbrPsgr_D_Stat 1;
BA_ "U_U55X_MY2022_Tx" SG_ 845 StmsLmbrPsgr_D_Stat 1;
BA_ "U_P702_MY2021_Tx" SG_ 845 StmsLmbrPsgr_D_Stat 1;
BA_ "GenSigSendType" SG_ 845 StmsLmbrPsgr_D_Stat 3;
BA_ "U_CD764_MY2022_Tx" SG_ 845 StmsCshnPsgr_D_Stat 1;
BA_ "U_U55X_MY2022_Tx" SG_ 845 StmsCshnPsgr_D_Stat 1;
BA_ "U_P702_MY2021_Tx" SG_ 845 StmsCshnPsgr_D_Stat 1;
BA_ "GenSigSendType" SG_ 845 StmsCshnPsgr_D_Stat 3;
BA_ "U_CD764_MY2022_Tx" SG_ 845 SeatSwtchPsgr_B_Stat 1;
BA_ "U_U55X_MY2022_Tx" SG_ 845 SeatSwtchPsgr_B_Stat 1;
BA_ "U_P702_MY2021_Tx" SG_ 845 SeatSwtchPsgr_B_Stat 1;
BA_ "GenSigSendType" SG_ 845 SeatSwtchPsgr_B_Stat 3;
BA_ "U_CD764_MY2022_Tx" SG_ 845 SeatPPsgr_B_Stat 1;
BA_ "U_U55X_MY2022_Tx" SG_ 845 SeatPPsgr_B_Stat 1;
BA_ "U_P702_MY2021_Tx" SG_ 845 SeatPPsgr_B_Stat 1;
BA_ "GenSigSendType" SG_ 845 SeatPPsgr_B_Stat 3;
BA_ "U_CD764_MY2022_Tx" SG_ 845 SeatFnPsgr_D_Stat 1;
BA_ "U_U55X_MY2022_Tx" SG_ 845 SeatFnPsgr_D_Stat 1;
BA_ "U_P702_MY2021_Tx" SG_ 845 SeatFnPsgr_D_Stat 1;
BA_ "GenSigSendType" SG_ 845 SeatFnPsgr_D_Stat 3;
BA_ "U_CD764_MY2022_Tx" SG_ 845 PsgrMemFeedback_Rsp 1;
BA_ "U_U55X_MY2022_Tx" SG_ 845 PsgrMemFeedback_Rsp 1;
BA_ "U_P702_MY2021_Tx" SG_ 845 PsgrMemFeedback_Rsp 1;
BA_ "GenSigSendType" SG_ 845 PsgrMemFeedback_Rsp 3;
BA_ "U_U55X_MY2022_Tx" SG_ 844 SeatMasgDrv_D_Stat 1;
BA_ "U_P702_MY2021_Tx" SG_ 844 SeatMasgDrv_D_Stat 1;
BA_ "GenSigSendType" SG_ 844 SeatMasgDrv_D_Stat 3;
BA_ "U_U55X_MY2022_Tx" SG_ 844 SeatIntnsDrv_D_Stat 1;
BA_ "U_P702_MY2021_Tx" SG_ 844 SeatIntnsDrv_D_Stat 1;
BA_ "GenSigSendType" SG_ 844 SeatIntnsDrv_D_Stat 3;
BA_ "U_CD764_MY2022_Tx" SG_ 844 StmsLmbrDrv_D_Stat 1;
BA_ "U_U55X_MY2022_Tx" SG_ 844 StmsLmbrDrv_D_Stat 1;
BA_ "U_P702_MY2021_Tx" SG_ 844 StmsLmbrDrv_D_Stat 1;
BA_ "GenSigSendType" SG_ 844 StmsLmbrDrv_D_Stat 3;
BA_ "U_CD764_MY2022_Tx" SG_ 844 StmsCshnDrv_D_Stat 1;
BA_ "U_U55X_MY2022_Tx" SG_ 844 StmsCshnDrv_D_Stat 1;
BA_ "U_P702_MY2021_Tx" SG_ 844 StmsCshnDrv_D_Stat 1;
BA_ "GenSigSendType" SG_ 844 StmsCshnDrv_D_Stat 3;
BA_ "U_CD764_MY2022_Tx" SG_ 844 SeatSwtchDrv_B_Stat 1;
BA_ "U_U55X_MY2022_Tx" SG_ 844 SeatSwtchDrv_B_Stat 1;
BA_ "U_P702_MY2021_Tx" SG_ 844 SeatSwtchDrv_B_Stat 1;
BA_ "GenSigSendType" SG_ 844 SeatSwtchDrv_B_Stat 3;
BA_ "U_CD764_MY2022_Tx" SG_ 844 SeatFnDrv_D_Stat 1;
BA_ "U_U55X_MY2022_Tx" SG_ 844 SeatFnDrv_D_Stat 1;
BA_ "U_P702_MY2021_Tx" SG_ 844 SeatFnDrv_D_Stat 1;
BA_ "GenSigSendType" SG_ 844 SeatFnDrv_D_Stat 3;
BA_ "U_CD764_MY2022_Tx" SG_ 844 SeatAirAmb_P_Actl 1;
BA_ "U_U55X_MY2022_Tx" SG_ 844 SeatAirAmb_P_Actl 1;
BA_ "U_P702_MY2021_Tx" SG_ 844 SeatAirAmb_P_Actl 1;
BA_ "U_CD764_MY2022_Rx" SG_ 844 SeatAirAmb_P_Actl 1;
BA_ "U_U55X_MY2022_Rx" SG_ 844 SeatAirAmb_P_Actl 1;
BA_ "U_P702_MY2021_Rx" SG_ 844 SeatAirAmb_P_Actl 1;
BA_ "U_CD764_MY2022_Tx" SG_ 844 SeatPDrv_B_Stat 1;
BA_ "U_U55X_MY2022_Tx" SG_ 844 SeatPDrv_B_Stat 1;
BA_ "U_P702_MY2021_Tx" SG_ 844 SeatPDrv_B_Stat 1;
BA_ "GenSigSendType" SG_ 844 SeatPDrv_B_Stat 3;
BA_ "U_CD764_MY2022_Tx" SG_ 843 SeatLmbrUpPsgr_Pc_Actl 1;
BA_ "U_U55X_MY2022_Tx" SG_ 843 SeatLmbrUpPsgr_Pc_Actl 1;
BA_ "U_P702_MY2021_Tx" SG_ 843 SeatLmbrUpPsgr_Pc_Actl 1;
BA_ "GenSigSendType" SG_ 843 SeatLmbrUpPsgr_Pc_Actl 3;
BA_ "GenSigStartValue" SG_ 843 SeatLmbrUpPsgr_Pc_Actl 127;
BA_ "GenSigStartValueInteger" SG_ 843 SeatLmbrUpPsgr_Pc_Actl 127;
BA_ "U_CD764_MY2022_Tx" SG_ 843 SeatLmbrMidPsgr_Pc_Actl 1;
BA_ "U_U55X_MY2022_Tx" SG_ 843 SeatLmbrMidPsgr_Pc_Actl 1;
BA_ "U_P702_MY2021_Tx" SG_ 843 SeatLmbrMidPsgr_Pc_Actl 1;
BA_ "GenSigSendType" SG_ 843 SeatLmbrMidPsgr_Pc_Actl 3;
BA_ "GenSigStartValue" SG_ 843 SeatLmbrMidPsgr_Pc_Actl 127;
BA_ "GenSigStartValueInteger" SG_ 843 SeatLmbrMidPsgr_Pc_Actl 127;
BA_ "U_CD764_MY2022_Tx" SG_ 843 SeatLmbrLoPsgr_Pc_Actl 1;
BA_ "U_U55X_MY2022_Tx" SG_ 843 SeatLmbrLoPsgr_Pc_Actl 1;
BA_ "U_P702_MY2021_Tx" SG_ 843 SeatLmbrLoPsgr_Pc_Actl 1;
BA_ "GenSigSendType" SG_ 843 SeatLmbrLoPsgr_Pc_Actl 3;
BA_ "GenSigStartValue" SG_ 843 SeatLmbrLoPsgr_Pc_Actl 127;
BA_ "GenSigStartValueInteger" SG_ 843 SeatLmbrLoPsgr_Pc_Actl 127;
BA_ "U_CD764_MY2022_Tx" SG_ 843 SeatBlUpPsgr_Pc_Actl 1;
BA_ "U_U55X_MY2022_Tx" SG_ 843 SeatBlUpPsgr_Pc_Actl 1;
BA_ "U_P702_MY2021_Tx" SG_ 843 SeatBlUpPsgr_Pc_Actl 1;
BA_ "GenSigSendType" SG_ 843 SeatBlUpPsgr_Pc_Actl 3;
BA_ "GenSigStartValue" SG_ 843 SeatBlUpPsgr_Pc_Actl 127;
BA_ "GenSigStartValueInteger" SG_ 843 SeatBlUpPsgr_Pc_Actl 127;
BA_ "U_CD764_MY2022_Tx" SG_ 843 SeatBlLoPsgr_Pc_Actl 1;
BA_ "U_U55X_MY2022_Tx" SG_ 843 SeatBlLoPsgr_Pc_Actl 1;
BA_ "U_P702_MY2021_Tx" SG_ 843 SeatBlLoPsgr_Pc_Actl 1;
BA_ "GenSigSendType" SG_ 843 SeatBlLoPsgr_Pc_Actl 3;
BA_ "GenSigStartValue" SG_ 843 SeatBlLoPsgr_Pc_Actl 127;
BA_ "GenSigStartValueInteger" SG_ 843 SeatBlLoPsgr_Pc_Actl 127;
BA_ "U_CD764_MY2022_Tx" SG_ 842 SeatLmbrUpDrv_Pc_Actl 1;
BA_ "U_U55X_MY2022_Tx" SG_ 842 SeatLmbrUpDrv_Pc_Actl 1;
BA_ "U_P702_MY2021_Tx" SG_ 842 SeatLmbrUpDrv_Pc_Actl 1;
BA_ "GenSigSendType" SG_ 842 SeatLmbrUpDrv_Pc_Actl 3;
BA_ "GenSigStartValue" SG_ 842 SeatLmbrUpDrv_Pc_Actl 127;
BA_ "GenSigStartValueInteger" SG_ 842 SeatLmbrUpDrv_Pc_Actl 127;
BA_ "U_CD764_MY2022_Tx" SG_ 842 SeatLmbrMidDrv_Pc_Actl 1;
BA_ "U_U55X_MY2022_Tx" SG_ 842 SeatLmbrMidDrv_Pc_Actl 1;
BA_ "U_P702_MY2021_Tx" SG_ 842 SeatLmbrMidDrv_Pc_Actl 1;
BA_ "GenSigSendType" SG_ 842 SeatLmbrMidDrv_Pc_Actl 3;
BA_ "GenSigStartValue" SG_ 842 SeatLmbrMidDrv_Pc_Actl 127;
BA_ "GenSigStartValueInteger" SG_ 842 SeatLmbrMidDrv_Pc_Actl 127;
BA_ "U_CD764_MY2022_Tx" SG_ 842 SeatLmbrLoDrv_Pc_Actl 1;
BA_ "U_U55X_MY2022_Tx" SG_ 842 SeatLmbrLoDrv_Pc_Actl 1;
BA_ "U_P702_MY2021_Tx" SG_ 842 SeatLmbrLoDrv_Pc_Actl 1;
BA_ "GenSigSendType" SG_ 842 SeatLmbrLoDrv_Pc_Actl 3;
BA_ "GenSigStartValue" SG_ 842 SeatLmbrLoDrv_Pc_Actl 127;
BA_ "GenSigStartValueInteger" SG_ 842 SeatLmbrLoDrv_Pc_Actl 127;
BA_ "U_CD764_MY2022_Tx" SG_ 842 SeatBlUpDrv_Pc_Actl 1;
BA_ "U_U55X_MY2022_Tx" SG_ 842 SeatBlUpDrv_Pc_Actl 1;
BA_ "U_P702_MY2021_Tx" SG_ 842 SeatBlUpDrv_Pc_Actl 1;
BA_ "GenSigSendType" SG_ 842 SeatBlUpDrv_Pc_Actl 3;
BA_ "GenSigStartValue" SG_ 842 SeatBlUpDrv_Pc_Actl 127;
BA_ "GenSigStartValueInteger" SG_ 842 SeatBlUpDrv_Pc_Actl 127;
BA_ "U_CD764_MY2022_Tx" SG_ 842 SeatBlLoDrv_Pc_Actl 1;
BA_ "U_U55X_MY2022_Tx" SG_ 842 SeatBlLoDrv_Pc_Actl 1;
BA_ "U_P702_MY2021_Tx" SG_ 842 SeatBlLoDrv_Pc_Actl 1;
BA_ "GenSigSendType" SG_ 842 SeatBlLoDrv_Pc_Actl 3;
BA_ "GenSigStartValue" SG_ 842 SeatBlLoDrv_Pc_Actl 127;
BA_ "GenSigStartValueInteger" SG_ 842 SeatBlLoDrv_Pc_Actl 127;
BA_ "U_U55X_MY2022_Tx" SG_ 1994 TesterPhysicalResRSM 1;
BA_ "U_T6_MCA_MY2020_Tx" SG_ 1994 TesterPhysicalResRSM 1;
BA_ "U_P702_MY2021_Tx" SG_ 1994 TesterPhysicalResRSM 1;
BA_ "U_CX727_MY2021_Tx" SG_ 1994 TesterPhysicalResRSM 1;
BA_ "GenSigSendType" SG_ 1994 TesterPhysicalResRSM 3;
BA_ "U_U55X_MY2022_Rx" SG_ 1986 TesterPhysicalReqRSM 1;
BA_ "U_T6_MCA_MY2020_Rx" SG_ 1986 TesterPhysicalReqRSM 1;
BA_ "U_P702_MY2021_Rx" SG_ 1986 TesterPhysicalReqRSM 1;
BA_ "U_CX727_MY2021_Rx" SG_ 1986 TesterPhysicalReqRSM 1;
BA_ "GenSigSendType" SG_ 1986 TesterPhysicalReqRSM 3;
BA_ "U_CD764_MY2022_Rx" SG_ 958 ElCmprOverTe_D_Stat 1;
BA_ "U_U55X_MY2022_Rx" SG_ 958 ElCmprOverTe_D_Stat 1;
BA_ "U_CD542_MY2021_Rx" SG_ 958 ElCmprOverTe_D_Stat 1;
BA_ "U_T6_MCA_MY2020_Rx" SG_ 958 ElCmprOverTe_D_Stat 1;
BA_ "U_P702_MY2021_Rx" SG_ 958 ElCmprOverTe_D_Stat 1;
BA_ "U_CX727_MY2021_Rx" SG_ 958 ElCmprOverTe_D_Stat 1;
BA_ "GenSigSendType" SG_ 958 ElCmprOverTe_D_Stat 3;
BA_ "U_CD764_MY2022_Rx" SG_ 958 ElCmprOverTe_D_Stat_UB 1;
BA_ "U_U55X_MY2022_Rx" SG_ 958 ElCmprOverTe_D_Stat_UB 1;
BA_ "U_CD542_MY2021_Rx" SG_ 958 ElCmprOverTe_D_Stat_UB 1;
BA_ "U_T6_MCA_MY2020_Rx" SG_ 958 ElCmprOverTe_D_Stat_UB 1;
BA_ "U_P702_MY2021_Rx" SG_ 958 ElCmprOverTe_D_Stat_UB 1;
BA_ "U_CX727_MY2021_Rx" SG_ 958 ElCmprOverTe_D_Stat_UB 1;
BA_ "U_CD764_MY2022_Rx" SG_ 958 EngOff_T_Actl 1;
BA_ "U_U55X_MY2022_Rx" SG_ 958 EngOff_T_Actl 1;
BA_ "U_CD542_MY2021_Rx" SG_ 958 EngOff_T_Actl 1;
BA_ "U_T6_MCA_MY2020_Rx" SG_ 958 EngOff_T_Actl 1;
BA_ "U_P702_MY2021_Rx" SG_ 958 EngOff_T_Actl 1;
BA_ "U_CX727_MY2021_Rx" SG_ 958 EngOff_T_Actl 1;
BA_ "GenSigSendType" SG_ 958 EngOff_T_Actl 3;
BA_ "U_CD764_MY2022_Rx" SG_ 958 EngOff_T_Actl_UB 1;
BA_ "U_U55X_MY2022_Rx" SG_ 958 EngOff_T_Actl_UB 1;
BA_ "U_CD542_MY2021_Rx" SG_ 958 EngOff_T_Actl_UB 1;
BA_ "U_T6_MCA_MY2020_Rx" SG_ 958 EngOff_T_Actl_UB 1;
BA_ "U_P702_MY2021_Rx" SG_ 958 EngOff_T_Actl_UB 1;
BA_ "U_CX727_MY2021_Rx" SG_ 958 EngOff_T_Actl_UB 1;
BA_ "U_T6_MCA_MY2020_Rx" SG_ 958 StopStrtDrvMde_D_Indic_UB 1;
BA_ "U_CD764_MY2022_Rx" SG_ 958 StopStrtDrvMde_D_Indic_UB 1;
BA_ "U_U55X_MY2022_Rx" SG_ 958 StopStrtDrvMde_D_Indic_UB 1;
BA_ "U_CD542_MY2021_Rx" SG_ 958 StopStrtDrvMde_D_Indic_UB 1;
BA_ "U_CX727_MY2021_Rx" SG_ 958 StopStrtDrvMde_D_Indic_UB 1;
BA_ "U_U55X_MY2022_Rx" SG_ 958 PrmtrAlrmEvnt_D_Stat 1;
BA_ "U_T6_MCA_MY2020_Rx" SG_ 958 PrmtrAlrmEvnt_D_Stat 1;
BA_ "U_P702_MY2021_Rx" SG_ 958 PrmtrAlrmEvnt_D_Stat 1;
BA_ "U_CX727_MY2021_Rx" SG_ 958 PrmtrAlrmEvnt_D_Stat 1;
BA_ "GenSigSendType" SG_ 958 PrmtrAlrmEvnt_D_Stat 3;
BA_ "U_U55X_MY2022_Rx" SG_ 958 PrmtrAlrmEvnt_D_Stat_UB 1;
BA_ "U_T6_MCA_MY2020_Rx" SG_ 958 PrmtrAlrmEvnt_D_Stat_UB 1;
BA_ "U_P702_MY2021_Rx" SG_ 958 PrmtrAlrmEvnt_D_Stat_UB 1;
BA_ "U_CX727_MY2021_Rx" SG_ 958 PrmtrAlrmEvnt_D_Stat_UB 1;
BA_ "U_T6_MCA_MY2020_Rx" SG_ 958 StopStrtDrvMde_D_Indic 1;
BA_ "U_CD764_MY2022_Rx" SG_ 958 StopStrtDrvMde_D_Indic 1;
BA_ "U_U55X_MY2022_Rx" SG_ 958 StopStrtDrvMde_D_Indic 1;
BA_ "U_CD542_MY2021_Rx" SG_ 958 StopStrtDrvMde_D_Indic 1;
BA_ "U_CX727_MY2021_Rx" SG_ 958 StopStrtDrvMde_D_Indic 1;
BA_ "GenSigSendType" SG_ 958 StopStrtDrvMde_D_Indic 3;
BA_ "GenSigSendType" SG_ 958 FuelLvl_Pc_Dsply 3;
BA_ "U_CD764_MY2022_Rx" SG_ 958 OdometerMasterValue_UB 1;
BA_ "U_P702_MY2021_Rx" SG_ 958 OdometerMasterValue_UB 1;
BA_ "U_U55X_MY2022_Rx" SG_ 958 OdometerMasterValue_UB 1;
BA_ "U_CD542_MY2021_Rx" SG_ 958 OdometerMasterValue_UB 1;
BA_ "U_CX727_MY2021_Rx" SG_ 958 OdometerMasterValue_UB 1;
BA_ "U_CD764_MY2022_Rx" SG_ 958 OdometerMasterValue 1;
BA_ "U_P702_MY2021_Rx" SG_ 958 OdometerMasterValue 1;
BA_ "U_U55X_MY2022_Rx" SG_ 958 OdometerMasterValue 1;
BA_ "U_CD542_MY2021_Rx" SG_ 958 OdometerMasterValue 1;
BA_ "U_CX727_MY2021_Rx" SG_ 958 OdometerMasterValue 1;
BA_ "GenSigSendType" SG_ 958 OdometerMasterValue 3;
BA_ "GenSigSendType" SG_ 827 LghtAmbIntns_D2_Sns 3;
BA_ "GenSigStartValue" SG_ 827 LghtAmbIntns_D2_Sns 3;
BA_ "U_CD764_MY2022_Rx" SG_ 827 SteClmnSwtchTlt_D_Stat 1;
BA_ "U_U55X_MY2022_Rx" SG_ 827 SteClmnSwtchTlt_D_Stat 1;
BA_ "U_CD542_MY2021_Rx" SG_ 827 SteClmnSwtchTlt_D_Stat 1;
BA_ "U_T6_MCA_MY2020_Rx" SG_ 827 SteClmnSwtchTlt_D_Stat 1;
BA_ "U_P702_MY2021_Rx" SG_ 827 SteClmnSwtchTlt_D_Stat 1;
BA_ "U_CX727_MY2021_Rx" SG_ 827 SteClmnSwtchTlt_D_Stat 1;
BA_ "GenSigSendType" SG_ 827 SteClmnSwtchTlt_D_Stat 3;
BA_ "WakeupSignal" SG_ 827 SteClmnSwtchTlt_D_Stat 1;
BA_ "U_CD764_MY2022_Rx" SG_ 827 SteClmnSwtchTel_D_Stat 1;
BA_ "U_U55X_MY2022_Rx" SG_ 827 SteClmnSwtchTel_D_Stat 1;
BA_ "U_CD542_MY2021_Rx" SG_ 827 SteClmnSwtchTel_D_Stat 1;
BA_ "U_T6_MCA_MY2020_Rx" SG_ 827 SteClmnSwtchTel_D_Stat 1;
BA_ "U_P702_MY2021_Rx" SG_ 827 SteClmnSwtchTel_D_Stat 1;
BA_ "U_CX727_MY2021_Rx" SG_ 827 SteClmnSwtchTel_D_Stat 1;
BA_ "GenSigSendType" SG_ 827 SteClmnSwtchTel_D_Stat 3;
BA_ "WakeupSignal" SG_ 827 SteClmnSwtchTel_D_Stat 1;
BA_ "GenSigSendType" SG_ 827 LghtAmbIntns_D_Sns 3;
BA_ "U_U55X_MY2022_Tx" SG_ 902 PrmtrAlrmWarnRq_No_Actl 1;
BA_ "U_T6_MCA_MY2020_Tx" SG_ 902 PrmtrAlrmWarnRq_No_Actl 1;
BA_ "U_P702_MY2021_Tx" SG_ 902 PrmtrAlrmWarnRq_No_Actl 1;
BA_ "U_CX727_MY2021_Tx" SG_ 902 PrmtrAlrmWarnRq_No_Actl 1;
BA_ "GenSigSendType" SG_ 902 PrmtrAlrmWarnRq_No_Actl 3;
BA_ "WakeupSignal" SG_ 902 PrmtrAlrmWarnRq_No_Actl 1;
BA_ "U_U55X_MY2022_Tx" SG_ 902 PrmtrAlrmTrgRq_No_Actl 1;
BA_ "U_T6_MCA_MY2020_Tx" SG_ 902 PrmtrAlrmTrgRq_No_Actl 1;
BA_ "U_P702_MY2021_Tx" SG_ 902 PrmtrAlrmTrgRq_No_Actl 1;
BA_ "U_CX727_MY2021_Tx" SG_ 902 PrmtrAlrmTrgRq_No_Actl 1;
BA_ "GenSigSendType" SG_ 902 PrmtrAlrmTrgRq_No_Actl 3;
BA_ "WakeupSignal" SG_ 902 PrmtrAlrmTrgRq_No_Actl 1;
BA_ "U_U55X_MY2022_Tx" SG_ 902 Remote_Start_Req 1;
BA_ "U_T6_MCA_MY2020_Tx" SG_ 902 Remote_Start_Req 1;
BA_ "U_P702_MY2021_Tx" SG_ 902 Remote_Start_Req 1;
BA_ "U_CX727_MY2021_Tx" SG_ 902 Remote_Start_Req 1;
BA_ "GenSigSendType" SG_ 902 Remote_Start_Req 3;
BA_ "WakeupSignal" SG_ 902 Remote_Start_Req 1;
BA_ "U_U55X_MY2022_Tx" SG_ 902 RollCode_No_ActlRsm 1;
BA_ "U_T6_MCA_MY2020_Tx" SG_ 902 RollCode_No_ActlRsm 1;
BA_ "U_P702_MY2021_Tx" SG_ 902 RollCode_No_ActlRsm 1;
BA_ "U_CX727_MY2021_Tx" SG_ 902 RollCode_No_ActlRsm 1;
BA_ "GenSigSendType" SG_ 902 RollCode_No_ActlRsm 3;
BA_ "WakeupSignal" SG_ 902 RollCode_No_ActlRsm 1;
BA_ "U_U55X_MY2022_Tx" SG_ 902 PrmtrAlrmWarn_B_Rq 1;
BA_ "U_T6_MCA_MY2020_Tx" SG_ 902 PrmtrAlrmWarn_B_Rq 1;
BA_ "U_P702_MY2021_Tx" SG_ 902 PrmtrAlrmWarn_B_Rq 1;
BA_ "U_CX727_MY2021_Tx" SG_ 902 PrmtrAlrmWarn_B_Rq 1;
BA_ "GenSigSendType" SG_ 902 PrmtrAlrmWarn_B_Rq 3;
BA_ "WakeupSignal" SG_ 902 PrmtrAlrmWarn_B_Rq 1;
BA_ "U_U55X_MY2022_Tx" SG_ 902 PrmtrAlrmTrg_B_Rq 1;
BA_ "U_T6_MCA_MY2020_Tx" SG_ 902 PrmtrAlrmTrg_B_Rq 1;
BA_ "U_P702_MY2021_Tx" SG_ 902 PrmtrAlrmTrg_B_Rq 1;
BA_ "U_CX727_MY2021_Tx" SG_ 902 PrmtrAlrmTrg_B_Rq 1;
BA_ "GenSigSendType" SG_ 902 PrmtrAlrmTrg_B_Rq 3;
BA_ "WakeupSignal" SG_ 902 PrmtrAlrmTrg_B_Rq 1;
BA_ "U_U55X_MY2022_Tx" SG_ 902 PanicRq_No_ActlRsm 1;
BA_ "U_T6_MCA_MY2020_Tx" SG_ 902 PanicRq_No_ActlRsm 1;
BA_ "U_P702_MY2021_Tx" SG_ 902 PanicRq_No_ActlRsm 1;
BA_ "U_CX727_MY2021_Tx" SG_ 902 PanicRq_No_ActlRsm 1;
BA_ "GenSigSendType" SG_ 902 PanicRq_No_ActlRsm 3;
BA_ "WakeupSignal" SG_ 902 PanicRq_No_ActlRsm 1;
BA_ "U_U55X_MY2022_Tx" SG_ 902 Panic_D_RqRsm 1;
BA_ "U_T6_MCA_MY2020_Tx" SG_ 902 Panic_D_RqRsm 1;
BA_ "U_P702_MY2021_Tx" SG_ 902 Panic_D_RqRsm 1;
BA_ "U_CX727_MY2021_Tx" SG_ 902 Panic_D_RqRsm 1;
BA_ "GenSigSendType" SG_ 902 Panic_D_RqRsm 3;
BA_ "WakeupSignal" SG_ 902 Panic_D_RqRsm 1;
BA_ "U_U55X_MY2022_Tx" SG_ 902 CellLockRq_No_ActlRsm 1;
BA_ "U_T6_MCA_MY2020_Tx" SG_ 902 CellLockRq_No_ActlRsm 1;
BA_ "U_P702_MY2021_Tx" SG_ 902 CellLockRq_No_ActlRsm 1;
BA_ "U_CX727_MY2021_Tx" SG_ 902 CellLockRq_No_ActlRsm 1;
BA_ "GenSigSendType" SG_ 902 CellLockRq_No_ActlRsm 3;
BA_ "WakeupSignal" SG_ 902 CellLockRq_No_ActlRsm 1;
BA_ "U_U55X_MY2022_Tx" SG_ 902 CellLock_D_RqRsm 1;
BA_ "U_T6_MCA_MY2020_Tx" SG_ 902 CellLock_D_RqRsm 1;
BA_ "U_P702_MY2021_Tx" SG_ 902 CellLock_D_RqRsm 1;
BA_ "U_CX727_MY2021_Tx" SG_ 902 CellLock_D_RqRsm 1;
BA_ "GenSigSendType" SG_ 902 CellLock_D_RqRsm 3;
BA_ "WakeupSignal" SG_ 902 CellLock_D_RqRsm 1;
BA_ "U_CD764_MY2022_Rx" SG_ 765 CcStat_D_Actl_UB 1;
BA_ "U_U55X_MY2022_Rx" SG_ 765 CcStat_D_Actl_UB 1;
BA_ "U_CD542_MY2021_Rx" SG_ 765 CcStat_D_Actl_UB 1;
BA_ "U_T6_MCA_MY2020_Rx" SG_ 765 CcStat_D_Actl_UB 1;
BA_ "U_CD764_MY2022_Rx" SG_ 765 CcStat_D_Actl 1;
BA_ "U_U55X_MY2022_Rx" SG_ 765 CcStat_D_Actl 1;
BA_ "U_CD542_MY2021_Rx" SG_ 765 CcStat_D_Actl 1;
BA_ "U_T6_MCA_MY2020_Rx" SG_ 765 CcStat_D_Actl 1;
BA_ "U_CD764_MY2022_Rx" SG_ 765 PrplTqMnSat_B_Actl_UB 1;
BA_ "U_U55X_MY2022_Rx" SG_ 765 PrplTqMnSat_B_Actl_UB 1;
BA_ "U_CD542_MY2021_Rx" SG_ 765 PrplTqMnSat_B_Actl_UB 1;
BA_ "U_T6_MCA_MY2020_Rx" SG_ 765 PrplTqMnSat_B_Actl_UB 1;
BA_ "U_CD764_MY2022_Rx" SG_ 765 PrplTqMnSat_B_Actl 1;
BA_ "U_U55X_MY2022_Rx" SG_ 765 PrplTqMnSat_B_Actl 1;
BA_ "U_CD542_MY2021_Rx" SG_ 765 PrplTqMnSat_B_Actl 1;
BA_ "U_T6_MCA_MY2020_Rx" SG_ 765 PrplTqMnSat_B_Actl 1;
BA_ "U_CD764_MY2022_Rx" SG_ 765 ClimtBlwrLim_B_Rq 1;
BA_ "U_U55X_MY2022_Rx" SG_ 765 ClimtBlwrLim_B_Rq 1;
BA_ "U_CD542_MY2021_Rx" SG_ 765 ClimtBlwrLim_B_Rq 1;
BA_ "U_T6_MCA_MY2020_Rx" SG_ 765 ClimtBlwrLim_B_Rq 1;
BA_ "GenSigSendType" SG_ 765 ClimtBlwrLim_B_Rq 3;
BA_ "ContentDependant" SG_ 765 ClimtBlwrLim_B_Rq 1;
BA_ "U_CD764_MY2022_Rx" SG_ 765 ClimtBlwrLim_B_Rq_UB 1;
BA_ "U_U55X_MY2022_Rx" SG_ 765 ClimtBlwrLim_B_Rq_UB 1;
BA_ "U_CD542_MY2021_Rx" SG_ 765 ClimtBlwrLim_B_Rq_UB 1;
BA_ "U_T6_MCA_MY2020_Rx" SG_ 765 ClimtBlwrLim_B_Rq_UB 1;
BA_ "U_CX727_MY2021_Rx" SG_ 765 ClimtBlwrLim_B_Rq_UB 1;
BA_ "GenSigSendType" SG_ 765 TrlrBrkActCnnct_B_Actl 3;
BA_ "U_CD764_MY2022_Rx" SG_ 765 EmPrflButtnAssoc_D_Rq 1;
BA_ "U_U55X_MY2022_Rx" SG_ 765 EmPrflButtnAssoc_D_Rq 1;
BA_ "U_CD542_MY2021_Rx" SG_ 765 EmPrflButtnAssoc_D_Rq 1;
BA_ "U_T6_MCA_MY2020_Rx" SG_ 765 EmPrflButtnAssoc_D_Rq 1;
BA_ "U_P702_MY2021_Rx" SG_ 765 EmPrflButtnAssoc_D_Rq 1;
BA_ "U_CX727_MY2021_Rx" SG_ 765 EmPrflButtnAssoc_D_Rq 1;
BA_ "GenSigSendType" SG_ 765 EmPrflButtnAssoc_D_Rq 3;
BA_ "U_CD764_MY2022_Rx" SG_ 765 EmPrflButtnAssoc_D_Rq_UB 1;
BA_ "U_U55X_MY2022_Rx" SG_ 765 EmPrflButtnAssoc_D_Rq_UB 1;
BA_ "U_CD542_MY2021_Rx" SG_ 765 EmPrflButtnAssoc_D_Rq_UB 1;
BA_ "U_T6_MCA_MY2020_Rx" SG_ 765 EmPrflButtnAssoc_D_Rq_UB 1;
BA_ "U_P702_MY2021_Rx" SG_ 765 EmPrflButtnAssoc_D_Rq_UB 1;
BA_ "U_CX727_MY2021_Rx" SG_ 765 EmPrflButtnAssoc_D_Rq_UB 1;
BA_ "U_CD764_MY2022_Rx" SG_ 765 CamraFrntStat_D_Stat_UB 1;
BA_ "U_U55X_MY2022_Rx" SG_ 765 CamraFrntStat_D_Stat_UB 1;
BA_ "U_CD542_MY2021_Rx" SG_ 765 CamraFrntStat_D_Stat_UB 1;
BA_ "U_T6_MCA_MY2020_Rx" SG_ 765 CamraFrntStat_D_Stat_UB 1;
BA_ "U_CX727_MY2021_Rx" SG_ 765 CamraFrntStat_D_Stat_UB 1;
BA_ "U_CD764_MY2022_Rx" SG_ 765 CamraFrntStat_D_Stat 1;
BA_ "U_U55X_MY2022_Rx" SG_ 765 CamraFrntStat_D_Stat 1;
BA_ "U_CD542_MY2021_Rx" SG_ 765 CamraFrntStat_D_Stat 1;
BA_ "U_T6_MCA_MY2020_Rx" SG_ 765 CamraFrntStat_D_Stat 1;
BA_ "U_CX727_MY2021_Rx" SG_ 765 CamraFrntStat_D_Stat 1;
BA_ "GenSigSendType" SG_ 765 CamraFrntStat_D_Stat 3;
BA_ "U_U55X_MY2022_Rx" SG_ 765 AutoHoldSwMde_B_Ind_UB 1;
BA_ "U_CD542_MY2021_Rx" SG_ 765 AutoHoldSwMde_B_Ind_UB 1;
BA_ "U_CX727_MY2021_Rx" SG_ 765 AutoHoldSwMde_B_Ind_UB 1;
BA_ "U_U55X_MY2022_Rx" SG_ 765 AutoHoldSwMde_B_Ind 1;
BA_ "U_CD542_MY2021_Rx" SG_ 765 AutoHoldSwMde_B_Ind 1;
BA_ "U_CX727_MY2021_Rx" SG_ 765 AutoHoldSwMde_B_Ind 1;
BA_ "GenSigSendType" SG_ 765 AutoHoldSwMde_B_Ind 3;
BA_ "ContentDependant" SG_ 765 AutoHoldSwMde_B_Ind 1;
BA_ "U_CD764_MY2022_Rx" SG_ 765 ValetMode_D_Stat_UB 1;
BA_ "U_U55X_MY2022_Rx" SG_ 765 ValetMode_D_Stat_UB 1;
BA_ "U_CD542_MY2021_Rx" SG_ 765 ValetMode_D_Stat_UB 1;
BA_ "U_T6_MCA_MY2020_Rx" SG_ 765 ValetMode_D_Stat_UB 1;
BA_ "U_P702_MY2021_Rx" SG_ 765 ValetMode_D_Stat_UB 1;
BA_ "U_CX727_MY2021_Rx" SG_ 765 ValetMode_D_Stat_UB 1;
BA_ "U_CD764_MY2022_Rx" SG_ 765 ValetMode_D_Stat 1;
BA_ "U_U55X_MY2022_Rx" SG_ 765 ValetMode_D_Stat 1;
BA_ "U_CD542_MY2021_Rx" SG_ 765 ValetMode_D_Stat 1;
BA_ "U_T6_MCA_MY2020_Rx" SG_ 765 ValetMode_D_Stat 1;
BA_ "U_P702_MY2021_Rx" SG_ 765 ValetMode_D_Stat 1;
BA_ "U_CX727_MY2021_Rx" SG_ 765 ValetMode_D_Stat 1;
BA_ "GenSigSendType" SG_ 765 ValetMode_D_Stat 3;
BA_ "U_CD764_MY2022_Rx" SG_ 765 SteWhlHeat_D_Stat 1;
BA_ "U_U55X_MY2022_Rx" SG_ 765 SteWhlHeat_D_Stat 1;
BA_ "U_CD542_MY2021_Rx" SG_ 765 SteWhlHeat_D_Stat 1;
BA_ "U_CX727_MY2021_Rx" SG_ 765 SteWhlHeat_D_Stat 1;
BA_ "GenSigSendType" SG_ 765 SteWhlHeat_D_Stat 3;
BA_ "U_U55X_MY2022_Rx" SG_ 765 Running_Board_Cmd_UB 1;
BA_ "U_P702_MY2021_Rx" SG_ 765 Running_Board_Cmd_UB 1;
BA_ "U_U55X_MY2022_Rx" SG_ 765 Running_Board_Cmd 1;
BA_ "U_P702_MY2021_Rx" SG_ 765 Running_Board_Cmd 1;
BA_ "GenSigSendType" SG_ 765 Running_Board_Cmd 3;
BA_ "U_U55X_MY2022_Rx" SG_ 765 Bezel_Beeps_Rq_UB 1;
BA_ "U_T6_MCA_MY2020_Rx" SG_ 765 Bezel_Beeps_Rq_UB 1;
BA_ "U_U55X_MY2022_Rx" SG_ 765 Bezel_Beeps_Rq 1;
BA_ "U_T6_MCA_MY2020_Rx" SG_ 765 Bezel_Beeps_Rq 1;
BA_ "GenSigSendType" SG_ 765 Bezel_Beeps_Rq 3;
BA_ "WakeupSignal" SG_ 765 Bezel_Beeps_Rq 1;
BA_ "U_CD764_MY2022_Rx" SG_ 765 Diagnostic_Operation_Rq_UB 1;
BA_ "U_U55X_MY2022_Rx" SG_ 765 Diagnostic_Operation_Rq_UB 1;
BA_ "U_CD542_MY2021_Rx" SG_ 765 Diagnostic_Operation_Rq_UB 1;
BA_ "U_T6_MCA_MY2020_Rx" SG_ 765 Diagnostic_Operation_Rq_UB 1;
BA_ "U_P702_MY2021_Rx" SG_ 765 Diagnostic_Operation_Rq_UB 1;
BA_ "U_CX727_MY2021_Rx" SG_ 765 Diagnostic_Operation_Rq_UB 1;
BA_ "U_U55X_MY2022_Rx" SG_ 765 Bezel_Diag_State_Rq_UB 1;
BA_ "U_T6_MCA_MY2020_Rx" SG_ 765 Bezel_Diag_State_Rq_UB 1;
BA_ "U_U55X_MY2022_Rx" SG_ 765 Bezel_Diag_Module_Rq_UB 1;
BA_ "U_T6_MCA_MY2020_Rx" SG_ 765 Bezel_Diag_Module_Rq_UB 1;
BA_ "U_CD764_MY2022_Rx" SG_ 765 Diagnostic_Operation_Rq 1;
BA_ "U_U55X_MY2022_Rx" SG_ 765 Diagnostic_Operation_Rq 1;
BA_ "U_CD542_MY2021_Rx" SG_ 765 Diagnostic_Operation_Rq 1;
BA_ "U_T6_MCA_MY2020_Rx" SG_ 765 Diagnostic_Operation_Rq 1;
BA_ "U_P702_MY2021_Rx" SG_ 765 Diagnostic_Operation_Rq 1;
BA_ "U_CX727_MY2021_Rx" SG_ 765 Diagnostic_Operation_Rq 1;
BA_ "GenSigSendType" SG_ 765 Diagnostic_Operation_Rq 3;
BA_ "U_U55X_MY2022_Rx" SG_ 765 Bezel_Diag_State_Rq 1;
BA_ "U_T6_MCA_MY2020_Rx" SG_ 765 Bezel_Diag_State_Rq 1;
BA_ "GenSigSendType" SG_ 765 Bezel_Diag_State_Rq 3;
BA_ "U_U55X_MY2022_Rx" SG_ 765 Bezel_Diag_Module_Rq 1;
BA_ "U_T6_MCA_MY2020_Rx" SG_ 765 Bezel_Diag_Module_Rq 1;
BA_ "GenSigSendType" SG_ 765 Bezel_Diag_Module_Rq 3;
BA_ "U_P702_MY2021_Rx" SG_ 765 HMI_HMIMode_St_UB 1;
BA_ "U_CD764_MY2022_Rx" SG_ 765 HMI_HMIMode_St_UB 1;
BA_ "U_U55X_MY2022_Rx" SG_ 765 HMI_HMIMode_St_UB 1;
BA_ "U_CD542_MY2021_Rx" SG_ 765 HMI_HMIMode_St_UB 1;
BA_ "U_T6_MCA_MY2020_Rx" SG_ 765 HMI_HMIMode_St_UB 1;
BA_ "U_CX727_MY2021_Rx" SG_ 765 HMI_HMIMode_St_UB 1;
BA_ "U_P702_MY2021_Rx" SG_ 765 HMI_HMIMode_St 1;
BA_ "U_CD764_MY2022_Rx" SG_ 765 HMI_HMIMode_St 1;
BA_ "U_U55X_MY2022_Rx" SG_ 765 HMI_HMIMode_St 1;
BA_ "U_CD542_MY2021_Rx" SG_ 765 HMI_HMIMode_St 1;
BA_ "U_T6_MCA_MY2020_Rx" SG_ 765 HMI_HMIMode_St 1;
BA_ "U_CX727_MY2021_Rx" SG_ 765 HMI_HMIMode_St 1;
BA_ "GenSigSendType" SG_ 765 HMI_HMIMode_St 3;
BA_ "WakeupSignal" SG_ 765 HMI_HMIMode_St 1;
BA_ "U_CD764_MY2022_Rx" SG_ 765 Mc_VehUnitTempUsrSel_St_UB 1;
BA_ "U_U55X_MY2022_Rx" SG_ 765 Mc_VehUnitTempUsrSel_St_UB 1;
BA_ "U_CD542_MY2021_Rx" SG_ 765 Mc_VehUnitTempUsrSel_St_UB 1;
BA_ "U_T6_MCA_MY2020_Rx" SG_ 765 Mc_VehUnitTempUsrSel_St_UB 1;
BA_ "U_P702_MY2021_Rx" SG_ 765 Mc_VehUnitTempUsrSel_St_UB 1;
BA_ "U_CX727_MY2021_Rx" SG_ 765 Mc_VehUnitTempUsrSel_St_UB 1;
BA_ "U_CD764_MY2022_Rx" SG_ 765 Mc_VehUnitTempUsrSel_St 1;
BA_ "U_U55X_MY2022_Rx" SG_ 765 Mc_VehUnitTempUsrSel_St 1;
BA_ "U_CD542_MY2021_Rx" SG_ 765 Mc_VehUnitTempUsrSel_St 1;
BA_ "U_T6_MCA_MY2020_Rx" SG_ 765 Mc_VehUnitTempUsrSel_St 1;
BA_ "U_P702_MY2021_Rx" SG_ 765 Mc_VehUnitTempUsrSel_St 1;
BA_ "U_CX727_MY2021_Rx" SG_ 765 Mc_VehUnitTempUsrSel_St 1;
BA_ "GenSigSendType" SG_ 765 Mc_VehUnitTempUsrSel_St 3;
BA_ "U_CD764_MY2022_Rx" SG_ 765 PsngrFrntDetct_D_Actl_UB 1;
BA_ "U_U55X_MY2022_Rx" SG_ 765 PsngrFrntDetct_D_Actl_UB 1;
BA_ "U_CD542_MY2021_Rx" SG_ 765 PsngrFrntDetct_D_Actl_UB 1;
BA_ "U_T6_MCA_MY2020_Rx" SG_ 765 PsngrFrntDetct_D_Actl_UB 1;
BA_ "U_P702_MY2021_Rx" SG_ 765 PsngrFrntDetct_D_Actl_UB 1;
BA_ "U_CX727_MY2021_Rx" SG_ 765 PsngrFrntDetct_D_Actl_UB 1;
BA_ "U_CD764_MY2022_Rx" SG_ 765 PsngrFrntDetct_D_Actl 1;
BA_ "U_U55X_MY2022_Rx" SG_ 765 PsngrFrntDetct_D_Actl 1;
BA_ "U_CD542_MY2021_Rx" SG_ 765 PsngrFrntDetct_D_Actl 1;
BA_ "U_T6_MCA_MY2020_Rx" SG_ 765 PsngrFrntDetct_D_Actl 1;
BA_ "U_P702_MY2021_Rx" SG_ 765 PsngrFrntDetct_D_Actl 1;
BA_ "U_CX727_MY2021_Rx" SG_ 765 PsngrFrntDetct_D_Actl 1;
BA_ "GenSigSendType" SG_ 765 PsngrFrntDetct_D_Actl 3;
BA_ "GenSigStartValue" SG_ 765 PsngrFrntDetct_D_Actl 3;
BA_ "GenSigStartValueInteger" SG_ 765 PsngrFrntDetct_D_Actl 3;
BA_ "U_CD764_MY2022_Rx" SG_ 765 SteWhlHeat_D_Stat_UB 1;
BA_ "U_U55X_MY2022_Rx" SG_ 765 SteWhlHeat_D_Stat_UB 1;
BA_ "U_CD542_MY2021_Rx" SG_ 765 SteWhlHeat_D_Stat_UB 1;
BA_ "U_T6_MCA_MY2020_Rx" SG_ 765 SteWhlHeat_D_Stat_UB 1;
BA_ "U_CX727_MY2021_Rx" SG_ 765 SteWhlHeat_D_Stat_UB 1;
BA_ "GenSigSendType" SG_ 765 PrkAidLamp_D_Rq 3;
BA_ "U_U55X_MY2022_Rx" SG_ 765 ParkDetect_Stat_UB 1;
BA_ "U_T6_MCA_MY2020_Rx" SG_ 765 ParkDetect_Stat_UB 1;
BA_ "U_P702_MY2021_Rx" SG_ 765 ParkDetect_Stat_UB 1;
BA_ "U_CX727_MY2021_Rx" SG_ 765 ParkDetect_Stat_UB 1;
BA_ "U_U55X_MY2022_Rx" SG_ 765 ParkDetect_Stat 1;
BA_ "U_T6_MCA_MY2020_Rx" SG_ 765 ParkDetect_Stat 1;
BA_ "U_P702_MY2021_Rx" SG_ 765 ParkDetect_Stat 1;
BA_ "U_CX727_MY2021_Rx" SG_ 765 ParkDetect_Stat 1;
BA_ "GenSigSendType" SG_ 765 ParkDetect_Stat 3;
BA_ "U_CD764_MY2022_Rx" SG_ 765 Voice_Blower_Limit 1;
BA_ "U_U55X_MY2022_Rx" SG_ 765 Voice_Blower_Limit 1;
BA_ "U_CD542_MY2021_Rx" SG_ 765 Voice_Blower_Limit 1;
BA_ "U_T6_MCA_MY2020_Rx" SG_ 765 Voice_Blower_Limit 1;
BA_ "GenSigSendType" SG_ 765 Voice_Blower_Limit 3;
BA_ "U_CD764_MY2022_Rx" SG_ 765 Voice_Blower_Limit_UB 1;
BA_ "U_U55X_MY2022_Rx" SG_ 765 Voice_Blower_Limit_UB 1;
BA_ "U_CD542_MY2021_Rx" SG_ 765 Voice_Blower_Limit_UB 1;
BA_ "U_T6_MCA_MY2020_Rx" SG_ 765 Voice_Blower_Limit_UB 1;
BA_ "U_CD542_MY2021_Rx" SG_ 765 PwStep_D_DrvInhbt_UB 1;
BA_ "U_T6_MCA_MY2020_Rx" SG_ 765 PwStep_D_DrvInhbt_UB 1;
BA_ "U_P702_MY2021_Rx" SG_ 765 PwStep_D_DrvInhbt_UB 1;
BA_ "U_U55X_MY2022_Rx" SG_ 765 PwStep_D_DrvInhbt_UB 1;
BA_ "U_CD542_MY2021_Rx" SG_ 765 PwStep_D_DrvInhbt 1;
BA_ "U_T6_MCA_MY2020_Rx" SG_ 765 PwStep_D_DrvInhbt 1;
BA_ "U_P702_MY2021_Rx" SG_ 765 PwStep_D_DrvInhbt 1;
BA_ "U_U55X_MY2022_Rx" SG_ 765 PwStep_D_DrvInhbt 1;
BA_ "GenSigSendType" SG_ 765 PwStep_D_DrvInhbt 3;
BA_ "GenSigSendType" SG_ 556 Manual_Temp_Setting 3;
BA_ "GenSigSendType" SG_ 1815 TesterPhysicalReqRLCMA 3;
BA_ "U_CD764_MY2022_Rx" SG_ 359 ElPw_D_Stat 1;
BA_ "U_CD542_MY2021_Rx" SG_ 359 ElPw_D_Stat 1;
BA_ "U_T6_MCA_MY2020_Rx" SG_ 359 ElPw_D_Stat 1;
BA_ "U_P702_MY2021_Rx" SG_ 359 ElPw_D_Stat 1;
BA_ "U_CX727_MY2021_Rx" SG_ 359 ElPw_D_Stat 1;
BA_ "U_U55X_MY2022_Rx" SG_ 359 ElPw_D_Stat 1;
BA_ "GenSigSendType" SG_ 359 ElPw_D_Stat 3;
BA_ "U_CD764_MY2022_Tx" SG_ 359 SnowPlowMde_B_Enbl 1;
BA_ "U_U55X_MY2022_Tx" SG_ 359 SnowPlowMde_B_Enbl 1;
BA_ "U_CD542_MY2021_Tx" SG_ 359 SnowPlowMde_B_Enbl 1;
BA_ "U_T6_MCA_MY2020_Tx" SG_ 359 SnowPlowMde_B_Enbl 1;
BA_ "U_P702_MY2021_Tx" SG_ 359 SnowPlowMde_B_Enbl 1;
BA_ "U_CD764_MY2022_Rx" SG_ 359 SnowPlowMde_B_Enbl 1;
BA_ "U_P702_MY2021_Rx" SG_ 359 SnowPlowMde_B_Enbl 1;
BA_ "U_U55X_MY2022_Rx" SG_ 359 SnowPlowMde_B_Enbl 1;
BA_ "GenSigStartValueInteger" SG_ 359 PrplWhlRgenMn_Tq_Actl 4095;
BA_ "ContentDependant" SG_ 359 TrnAin_Tq_Actl 1;
BA_ "MetaData" SG_ 359 TrnAinTq_D_Qf 1;
BA_ "ContentDependant" SG_ 359 TrnAinTq_D_Qf 1;
BA_ "U_CD764_MY2022_Rx" SG_ 359 PwPckTq_D_Stat 1;
BA_ "U_U55X_MY2022_Rx" SG_ 359 PwPckTq_D_Stat 1;
BA_ "U_CD542_MY2021_Rx" SG_ 359 PwPckTq_D_Stat 1;
BA_ "U_T6_MCA_MY2020_Rx" SG_ 359 PwPckTq_D_Stat 1;
BA_ "U_P702_MY2021_Rx" SG_ 359 PwPckTq_D_Stat 1;
BA_ "U_CX727_MY2021_Rx" SG_ 359 PwPckTq_D_Stat 1;
BA_ "GenSigSendType" SG_ 359 PwPckTq_D_Stat 3;
BA_ "U_CD764_MY2022_Rx" SG_ 359 Eng_D_Stat 1;
BA_ "U_U55X_MY2022_Rx" SG_ 359 Eng_D_Stat 1;
BA_ "U_CD542_MY2021_Rx" SG_ 359 Eng_D_Stat 1;
BA_ "U_T6_MCA_MY2020_Rx" SG_ 359 Eng_D_Stat 1;
BA_ "U_P702_MY2021_Rx" SG_ 359 Eng_D_Stat 1;
BA_ "U_CX727_MY2021_Rx" SG_ 359 Eng_D_Stat 1;
BA_ "GenSigSendType" SG_ 359 Eng_D_Stat 3;
BA_ "GenSigStartValue" SG_ 359 PlgActvArb_B_Actl 1;
BA_ "ContentDependant" SG_ 359 PlgActvArb_B_Actl 1;
BA_ "GenSigStartValueInteger" SG_ 359 PlgActvArb_B_Actl 1;
BA_ "U_CD764_MY2022_Rx" SG_ 131 VehOnSrc_D_Stat_UB 1;
BA_ "U_U55X_MY2022_Rx" SG_ 131 VehOnSrc_D_Stat_UB 1;
BA_ "U_CD542_MY2021_Rx" SG_ 131 VehOnSrc_D_Stat_UB 1;
BA_ "U_T6_MCA_MY2020_Rx" SG_ 131 VehOnSrc_D_Stat_UB 1;
BA_ "U_CD764_MY2022_Rx" SG_ 131 VehOnSrc_D_Stat 1;
BA_ "U_U55X_MY2022_Rx" SG_ 131 VehOnSrc_D_Stat 1;
BA_ "U_CD542_MY2021_Rx" SG_ 131 VehOnSrc_D_Stat 1;
BA_ "U_T6_MCA_MY2020_Rx" SG_ 131 VehOnSrc_D_Stat 1;
BA_ "U_T6_MCA_MY2020_Rx" SG_ 131 StePinCompAnEst_D_Qf 1;
BA_ "U_CX727_MY2021_Rx" SG_ 131 StePinCompAnEst_D_Qf 1;
BA_ "GenSigStartValue" SG_ 131 StePinCompAnEst_D_Qf 1;
BA_ "MetaData" SG_ 131 StePinCompAnEst_D_Qf 1;
BA_ "GenSigStartValueInteger" SG_ 131 StePinCompAnEst_D_Qf 1;
BA_ "U_T6_MCA_MY2020_Rx" SG_ 131 StePinComp_An_Est_UB 1;
BA_ "U_CX727_MY2021_Rx" SG_ 131 StePinComp_An_Est_UB 1;
BA_ "U_T6_MCA_MY2020_Rx" SG_ 131 StePinComp_An_Est 1;
BA_ "U_CX727_MY2021_Rx" SG_ 131 StePinComp_An_Est 1;
BA_ "GenSigStartValueInteger" SG_ 131 StePinComp_An_Est 16000;
BA_ "U_U55X_MY2022_Rx" SG_ 131 VehLongComp_A_Actl_UB 1;
BA_ "U_CD542_MY2021_Rx" SG_ 131 VehLongComp_A_Actl_UB 1;
BA_ "U_T6_MCA_MY2020_Rx" SG_ 131 VehLongComp_A_Actl_UB 1;
BA_ "U_CX727_MY2021_Rx" SG_ 131 VehLongComp_A_Actl_UB 1;
BA_ "U_U55X_MY2022_Rx" SG_ 131 VehLatComp_A_Actl_UB 1;
BA_ "U_CD542_MY2021_Rx" SG_ 131 VehLatComp_A_Actl_UB 1;
BA_ "U_T6_MCA_MY2020_Rx" SG_ 131 VehLatComp_A_Actl_UB 1;
BA_ "U_CX727_MY2021_Rx" SG_ 131 VehLatComp_A_Actl_UB 1;
BA_ "U_U55X_MY2022_Rx" SG_ 131 VehLongComp_A_Actl 1;
BA_ "U_CD542_MY2021_Rx" SG_ 131 VehLongComp_A_Actl 1;
BA_ "U_T6_MCA_MY2020_Rx" SG_ 131 VehLongComp_A_Actl 1;
BA_ "U_CX727_MY2021_Rx" SG_ 131 VehLongComp_A_Actl 1;
BA_ "GenSigStartValue" SG_ 131 VehLongComp_A_Actl 1022;
BA_ "GenSigStartValueInteger" SG_ 131 VehLongComp_A_Actl 1022;
BA_ "U_U55X_MY2022_Rx" SG_ 131 VehLatComp_A_Actl 1;
BA_ "U_CD542_MY2021_Rx" SG_ 131 VehLatComp_A_Actl 1;
BA_ "U_T6_MCA_MY2020_Rx" SG_ 131 VehLatComp_A_Actl 1;
BA_ "U_CX727_MY2021_Rx" SG_ 131 VehLatComp_A_Actl 1;
BA_ "GenSigStartValue" SG_ 131 VehLatComp_A_Actl 1022;
BA_ "GenSigStartValueInteger" SG_ 131 VehLatComp_A_Actl 1022;
BA_ "U_T6_MCA_MY2020_Rx" SG_ 131 VehYaw_W_Actl_UB 1;
BA_ "U_CX727_MY2021_Rx" SG_ 131 VehYaw_W_Actl_UB 1;
BA_ "U_T6_MCA_MY2020_Rx" SG_ 131 VehYaw_W_Actl 1;
BA_ "U_CX727_MY2021_Rx" SG_ 131 VehYaw_W_Actl 1;
BA_ "GenSigStartValue" SG_ 131 VehYaw_W_Actl 65534;
BA_ "GenSigStartValueInteger" SG_ 131 VehYaw_W_Actl 65534;
BA_ "U_CD764_MY2022_Tx" SG_ 990 PersIndexDdm_D_Actl 1;
BA_ "U_U55X_MY2022_Tx" SG_ 990 PersIndexDdm_D_Actl 1;
BA_ "U_CD542_MY2021_Tx" SG_ 990 PersIndexDdm_D_Actl 1;
BA_ "U_T6_MCA_MY2020_Tx" SG_ 990 PersIndexDdm_D_Actl 1;
BA_ "U_P702_MY2021_Tx" SG_ 990 PersIndexDdm_D_Actl 1;
BA_ "U_CX727_MY2021_Tx" SG_ 990 PersIndexDdm_D_Actl 1;
BA_ "GenSigSendType" SG_ 990 PersIndexDdm_D_Actl 3;
BA_ "GenSigStartValue" SG_ 990 PersIndexDdm_D_Actl 4;
BA_ "GenSigStartValueInteger" SG_ 990 PersIndexDdm_D_Actl 4;
BA_ "U_CD764_MY2022_Tx" SG_ 990 FeatNoDdm_No_Actl 1;
BA_ "U_U55X_MY2022_Tx" SG_ 990 FeatNoDdm_No_Actl 1;
BA_ "U_CD542_MY2021_Tx" SG_ 990 FeatNoDdm_No_Actl 1;
BA_ "U_T6_MCA_MY2020_Tx" SG_ 990 FeatNoDdm_No_Actl 1;
BA_ "U_P702_MY2021_Tx" SG_ 990 FeatNoDdm_No_Actl 1;
BA_ "U_CX727_MY2021_Tx" SG_ 990 FeatNoDdm_No_Actl 1;
BA_ "GenSigSendType" SG_ 990 FeatNoDdm_No_Actl 3;
BA_ "U_CD764_MY2022_Tx" SG_ 990 FeatConfigDdmActl 1;
BA_ "U_U55X_MY2022_Tx" SG_ 990 FeatConfigDdmActl 1;
BA_ "U_CD542_MY2021_Tx" SG_ 990 FeatConfigDdmActl 1;
BA_ "U_T6_MCA_MY2020_Tx" SG_ 990 FeatConfigDdmActl 1;
BA_ "U_P702_MY2021_Tx" SG_ 990 FeatConfigDdmActl 1;
BA_ "U_CX727_MY2021_Tx" SG_ 990 FeatConfigDdmActl 1;
BA_ "GenSigSendType" SG_ 990 FeatConfigDdmActl 3;
BA_ "U_CD764_MY2022_Rx" SG_ 1003 PersRecallSrc_D_Actl 1;
BA_ "U_CD542_MY2021_Rx" SG_ 1003 PersRecallSrc_D_Actl 1;
BA_ "U_T6_MCA_MY2020_Rx" SG_ 1003 PersRecallSrc_D_Actl 1;
BA_ "U_P702_MY2021_Rx" SG_ 1003 PersRecallSrc_D_Actl 1;
BA_ "U_CX727_MY2021_Rx" SG_ 1003 PersRecallSrc_D_Actl 1;
BA_ "U_U55X_MY2022_Rx" SG_ 1003 PersRecallSrc_D_Actl 1;
BA_ "U_CD764_MY2022_Rx" SG_ 1003 PersSetupRestr_D_Actl 1;
BA_ "U_U55X_MY2022_Rx" SG_ 1003 PersSetupRestr_D_Actl 1;
BA_ "U_CD542_MY2021_Rx" SG_ 1003 PersSetupRestr_D_Actl 1;
BA_ "U_T6_MCA_MY2020_Rx" SG_ 1003 PersSetupRestr_D_Actl 1;
BA_ "U_P702_MY2021_Rx" SG_ 1003 PersSetupRestr_D_Actl 1;
BA_ "U_CX727_MY2021_Rx" SG_ 1003 PersSetupRestr_D_Actl 1;
BA_ "U_CD764_MY2022_Rx" SG_ 1003 PersSetupAccessCtrl 1;
BA_ "U_U55X_MY2022_Rx" SG_ 1003 PersSetupAccessCtrl 1;
BA_ "U_CD542_MY2021_Rx" SG_ 1003 PersSetupAccessCtrl 1;
BA_ "U_T6_MCA_MY2020_Rx" SG_ 1003 PersSetupAccessCtrl 1;
BA_ "U_P702_MY2021_Rx" SG_ 1003 PersSetupAccessCtrl 1;
BA_ "U_CX727_MY2021_Rx" SG_ 1003 PersSetupAccessCtrl 1;
BA_ "U_CD764_MY2022_Rx" SG_ 1003 PersSetup_No_Actl 1;
BA_ "U_U55X_MY2022_Rx" SG_ 1003 PersSetup_No_Actl 1;
BA_ "U_CD542_MY2021_Rx" SG_ 1003 PersSetup_No_Actl 1;
BA_ "U_T6_MCA_MY2020_Rx" SG_ 1003 PersSetup_No_Actl 1;
BA_ "U_P702_MY2021_Rx" SG_ 1003 PersSetup_No_Actl 1;
BA_ "U_CX727_MY2021_Rx" SG_ 1003 PersSetup_No_Actl 1;
BA_ "GenSigStartValue" SG_ 1003 PersConflict_D_Actl 1;
BA_ "GenSigStartValueInteger" SG_ 1003 PersConflict_D_Actl 1;
BA_ "U_CD764_MY2022_Rx" SG_ 1003 RecallEvent_No_Cnt 1;
BA_ "U_U55X_MY2022_Rx" SG_ 1003 RecallEvent_No_Cnt 1;
BA_ "U_CD542_MY2021_Rx" SG_ 1003 RecallEvent_No_Cnt 1;
BA_ "U_T6_MCA_MY2020_Rx" SG_ 1003 RecallEvent_No_Cnt 1;
BA_ "U_P702_MY2021_Rx" SG_ 1003 RecallEvent_No_Cnt 1;
BA_ "U_CX727_MY2021_Rx" SG_ 1003 RecallEvent_No_Cnt 1;
BA_ "MetaData" SG_ 1003 RecallEvent_No_Cnt 1;
BA_ "U_CD542_MY2021_Rx" SG_ 1003 PersNo_D_Actl 1;
BA_ "U_T6_MCA_MY2020_Rx" SG_ 1003 PersNo_D_Actl 1;
BA_ "U_CX727_MY2021_Rx" SG_ 1003 PersNo_D_Actl 1;
BA_ "U_CD764_MY2022_Rx" SG_ 1003 PersNo_D_Actl 1;
BA_ "U_U55X_MY2022_Rx" SG_ 1003 PersNo_D_Actl 1;
BA_ "U_P702_MY2021_Rx" SG_ 1003 PersNo_D_Actl 1;
BA_ "GenSigStartValue" SG_ 1003 PersNo_D_Actl 4;
BA_ "GenSigStartValueInteger" SG_ 1003 PersNo_D_Actl 4;
BA_ "U_CD764_MY2022_Rx" SG_ 1003 PersNoPos_D_Actl 1;
BA_ "U_CD542_MY2021_Rx" SG_ 1003 PersNoPos_D_Actl 1;
BA_ "U_T6_MCA_MY2020_Rx" SG_ 1003 PersNoPos_D_Actl 1;
BA_ "U_P702_MY2021_Rx" SG_ 1003 PersNoPos_D_Actl 1;
BA_ "U_CX727_MY2021_Rx" SG_ 1003 PersNoPos_D_Actl 1;
BA_ "GenSigStartValue" SG_ 1003 PersNoPos_D_Actl 4;
BA_ "GenSigStartValueInteger" SG_ 1003 PersNoPos_D_Actl 4;
BA_ "U_CD542_MY2021_Tx" SG_ 1945 TesterPhysicalResTRM 1;
BA_ "U_T6_MCA_MY2020_Tx" SG_ 1945 TesterPhysicalResTRM 1;
BA_ "U_P702_MY2021_Tx" SG_ 1945 TesterPhysicalResTRM 1;
BA_ "GenSigSendType" SG_ 1945 TesterPhysicalResTRM 3;
BA_ "ContentDependant" SG_ 836 FohFalt_D_Stat 1;
BA_ "ContentDependant" SG_ 836 FohEnbl_B_RqDrv 1;
BA_ "ContentDependant" SG_ 836 FohRqRun_B_Rq 1;
BA_ "U_CD764_MY2022_Rx" SG_ 836 HvacPrecondMode_D_Rq 1;
BA_ "U_CX727_MY2021_Rx" SG_ 836 HvacPrecondMode_D_Rq 1;
BA_ "ContentDependant" SG_ 836 HvacPrecondMode_D_Rq 1;
BA_ "WakeupSignal" SG_ 836 HvacPrecondMode_D_Rq 1;
BA_ "U_CD764_MY2022_Rx" SG_ 836 HvacPrecondBlwr_D_Rq 1;
BA_ "U_CX727_MY2021_Rx" SG_ 836 HvacPrecondBlwr_D_Rq 1;
BA_ "ContentDependant" SG_ 836 HvacPrecondBlwr_D_Rq 1;
BA_ "WakeupSignal" SG_ 836 HvacPrecondBlwr_D_Rq 1;
BA_ "U_CD764_MY2022_Rx" SG_ 836 Foh_D_Stat 1;
BA_ "U_CX727_MY2021_Rx" SG_ 836 Foh_D_Stat 1;
BA_ "ContentDependant" SG_ 836 Foh_D_Stat 1;
BA_ "WakeupSignal" SG_ 836 Foh_D_Stat 1;
BA_ "ContentDependant" SG_ 836 FuelFlw_Vl_ActlFoh 1;
BA_ "U_CD764_MY2022_Rx" SG_ 836 EngClnt_Te_ActlFoh 1;
BA_ "U_CX727_MY2021_Rx" SG_ 836 EngClnt_Te_ActlFoh 1;
BA_ "ContentDependant" SG_ 836 EngClnt_Te_ActlFoh 1;
BA_ "GenSigSendType" SG_ 819 WndwUpPsngrRear_D_Falt 3;
BA_ "GenSigSendType" SG_ 819 WndwUpPsngrFront_D_Falt 3;
BA_ "U_CD764_MY2022_Tx" SG_ 819 DrPrsntPsngr_D_Stat 1;
BA_ "U_T6_MCA_MY2020_Tx" SG_ 819 DrPrsntPsngr_D_Stat 1;
BA_ "U_CD764_MY2022_Rx" SG_ 819 DrPrsntPsngr_D_Stat 1;
BA_ "ECGUsedRxSignal" SG_ 819 DrPrsntPsngr_D_Stat 1;
BA_ "GenSigSendType" SG_ 819 DrPrsntPsngr_D_Stat 3;
BA_ "WakeupSignal" SG_ 819 DrPrsntPsngr_D_Stat 1;
BA_ "U_CD764_MY2022_Tx" SG_ 819 DrPsngrMsgTxt_B_Rq 1;
BA_ "U_T6_MCA_MY2020_Tx" SG_ 819 DrPsngrMsgTxt_B_Rq 1;
BA_ "GenSigSendType" SG_ 819 DrPsngrMsgTxt_B_Rq 3;
BA_ "U_CD764_MY2022_Tx" SG_ 819 DrPrsntRearPsngr_D_Stat 1;
BA_ "U_T6_MCA_MY2020_Tx" SG_ 819 DrPrsntRearPsngr_D_Stat 1;
BA_ "U_CD764_MY2022_Rx" SG_ 819 DrPrsntRearPsngr_D_Stat 1;
BA_ "ECGUsedRxSignal" SG_ 819 DrPrsntRearPsngr_D_Stat 1;
BA_ "GenSigSendType" SG_ 819 DrPrsntRearPsngr_D_Stat 3;
BA_ "WakeupSignal" SG_ 819 DrPrsntRearPsngr_D_Stat 1;
BA_ "U_CD764_MY2022_Tx" SG_ 819 RollCode_No_ActlPdm 1;
BA_ "U_U55X_MY2022_Tx" SG_ 819 RollCode_No_ActlPdm 1;
BA_ "U_CD542_MY2021_Tx" SG_ 819 RollCode_No_ActlPdm 1;
BA_ "U_T6_MCA_MY2020_Tx" SG_ 819 RollCode_No_ActlPdm 1;
BA_ "U_P702_MY2021_Tx" SG_ 819 RollCode_No_ActlPdm 1;
BA_ "U_CD764_MY2022_Tx" SG_ 819 Memory_3_SwPsngr_Stat 1;
BA_ "U_U55X_MY2022_Tx" SG_ 819 Memory_3_SwPsngr_Stat 1;
BA_ "U_T6_MCA_MY2020_Tx" SG_ 819 Memory_3_SwPsngr_Stat 1;
BA_ "U_P702_MY2021_Tx" SG_ 819 Memory_3_SwPsngr_Stat 1;
BA_ "U_U55X_MY2022_Rx" SG_ 819 Memory_3_SwPsngr_Stat 1;
BA_ "GenSigSendType" SG_ 819 Memory_3_SwPsngr_Stat 3;
BA_ "WakeupSignal" SG_ 819 Memory_3_SwPsngr_Stat 1;
BA_ "U_CD764_MY2022_Tx" SG_ 819 Memory_2_SwPsngr_Stat 1;
BA_ "U_U55X_MY2022_Tx" SG_ 819 Memory_2_SwPsngr_Stat 1;
BA_ "U_T6_MCA_MY2020_Tx" SG_ 819 Memory_2_SwPsngr_Stat 1;
BA_ "U_P702_MY2021_Tx" SG_ 819 Memory_2_SwPsngr_Stat 1;
BA_ "U_U55X_MY2022_Rx" SG_ 819 Memory_2_SwPsngr_Stat 1;
BA_ "GenSigSendType" SG_ 819 Memory_2_SwPsngr_Stat 3;
BA_ "WakeupSignal" SG_ 819 Memory_2_SwPsngr_Stat 1;
BA_ "U_CD764_MY2022_Tx" SG_ 819 Memory_1_SwPsngr_Stat 1;
BA_ "U_U55X_MY2022_Tx" SG_ 819 Memory_1_SwPsngr_Stat 1;
BA_ "U_T6_MCA_MY2020_Tx" SG_ 819 Memory_1_SwPsngr_Stat 1;
BA_ "U_P702_MY2021_Tx" SG_ 819 Memory_1_SwPsngr_Stat 1;
BA_ "U_U55X_MY2022_Rx" SG_ 819 Memory_1_SwPsngr_Stat 1;
BA_ "GenSigSendType" SG_ 819 Memory_1_SwPsngr_Stat 3;
BA_ "WakeupSignal" SG_ 819 Memory_1_SwPsngr_Stat 1;
BA_ "U_CD764_MY2022_Tx" SG_ 819 BLISLEDStatPassSide 1;
BA_ "U_U55X_MY2022_Tx" SG_ 819 BLISLEDStatPassSide 1;
BA_ "U_CD542_MY2021_Tx" SG_ 819 BLISLEDStatPassSide 1;
BA_ "U_T6_MCA_MY2020_Tx" SG_ 819 BLISLEDStatPassSide 1;
BA_ "U_P702_MY2021_Tx" SG_ 819 BLISLEDStatPassSide 1;
BA_ "U_T6_MCA_MY2020_Rx" SG_ 819 BLISLEDStatPassSide 1;
BA_ "U_CX727_MY2021_Rx" SG_ 819 BLISLEDStatPassSide 1;
BA_ "GenSigSendType" SG_ 819 BLISLEDStatPassSide 3;
BA_ "U_CD764_MY2022_Tx" SG_ 819 WndwPsngrSide_D_Stat 1;
BA_ "U_U55X_MY2022_Tx" SG_ 819 WndwPsngrSide_D_Stat 1;
BA_ "U_CD542_MY2021_Tx" SG_ 819 WndwPsngrSide_D_Stat 1;
BA_ "U_T6_MCA_MY2020_Tx" SG_ 819 WndwPsngrSide_D_Stat 1;
BA_ "U_P702_MY2021_Tx" SG_ 819 WndwPsngrSide_D_Stat 1;
BA_ "GenSigSendType" SG_ 819 WndwPsngrSide_D_Stat 3;
BA_ "U_CD764_MY2022_Tx" SG_ 819 Pasngr_Lock_Sw_Stat 1;
BA_ "U_U55X_MY2022_Tx" SG_ 819 Pasngr_Lock_Sw_Stat 1;
BA_ "U_CD542_MY2021_Tx" SG_ 819 Pasngr_Lock_Sw_Stat 1;
BA_ "U_T6_MCA_MY2020_Tx" SG_ 819 Pasngr_Lock_Sw_Stat 1;
BA_ "U_P702_MY2021_Tx" SG_ 819 Pasngr_Lock_Sw_Stat 1;
BA_ "GenSigSendType" SG_ 819 Pasngr_Lock_Sw_Stat 3;
BA_ "WakeupSignal" SG_ 819 Pasngr_Lock_Sw_Stat 1;
BA_ "U_CD764_MY2022_Tx" SG_ 819 Pasngr_Lock_Sw_Cnt 1;
BA_ "U_U55X_MY2022_Tx" SG_ 819 Pasngr_Lock_Sw_Cnt 1;
BA_ "U_CD542_MY2021_Tx" SG_ 819 Pasngr_Lock_Sw_Cnt 1;
BA_ "U_T6_MCA_MY2020_Tx" SG_ 819 Pasngr_Lock_Sw_Cnt 1;
BA_ "U_P702_MY2021_Tx" SG_ 819 Pasngr_Lock_Sw_Cnt 1;
BA_ "GenSigSendType" SG_ 819 Pasngr_Lock_Sw_Cnt 3;
BA_ "MetaData" SG_ 819 Pasngr_Lock_Sw_Cnt 1;
BA_ "WakeupSignal" SG_ 819 Pasngr_Lock_Sw_Cnt 1;
BA_ "U_CD764_MY2022_Tx" SG_ 819 ChildLckFdbckRp_B_Stat 1;
BA_ "U_U55X_MY2022_Tx" SG_ 819 ChildLckFdbckRp_B_Stat 1;
BA_ "U_CD542_MY2021_Tx" SG_ 819 ChildLckFdbckRp_B_Stat 1;
BA_ "U_T6_MCA_MY2020_Tx" SG_ 819 ChildLckFdbckRp_B_Stat 1;
BA_ "U_P702_MY2021_Tx" SG_ 819 ChildLckFdbckRp_B_Stat 1;
BA_ "GenSigSendType" SG_ 819 ChildLckFdbckRp_B_Stat 3;
BA_ "WakeupSignal" SG_ 819 ChildLckFdbckRp_B_Stat 1;
BA_ "GenSigSendType" SG_ 818 WndwUpDrvRear_D_Falt 3;
BA_ "GenSigSendType" SG_ 818 WndwUpDrvFront_D_Falt 3;
BA_ "U_CD764_MY2022_Tx" SG_ 818 DrvSpotLight_B_Stat 1;
BA_ "U_T6_MCA_MY2020_Tx" SG_ 818 DrvSpotLight_B_Stat 1;
BA_ "U_CD764_MY2022_Rx" SG_ 818 DrvSpotLight_B_Stat 1;
BA_ "U_T6_MCA_MY2020_Rx" SG_ 818 DrvSpotLight_B_Stat 1;
BA_ "GenSigSendType" SG_ 818 DrvSpotLight_B_Stat 3;
BA_ "U_CD764_MY2022_Tx" SG_ 818 DrPrsntDrv_D_Stat 1;
BA_ "U_T6_MCA_MY2020_Tx" SG_ 818 DrPrsntDrv_D_Stat 1;
BA_ "U_CD764_MY2022_Rx" SG_ 818 DrPrsntDrv_D_Stat 1;
BA_ "ECGUsedRxSignal" SG_ 818 DrPrsntDrv_D_Stat 1;
BA_ "GenSigSendType" SG_ 818 DrPrsntDrv_D_Stat 3;
BA_ "WakeupSignal" SG_ 818 DrPrsntDrv_D_Stat 1;
BA_ "U_CD764_MY2022_Tx" SG_ 818 DrPrsntRearDrv_D_Stat 1;
BA_ "U_T6_MCA_MY2020_Tx" SG_ 818 DrPrsntRearDrv_D_Stat 1;
BA_ "U_CD764_MY2022_Rx" SG_ 818 DrPrsntRearDrv_D_Stat 1;
BA_ "ECGUsedRxSignal" SG_ 818 DrPrsntRearDrv_D_Stat 1;
BA_ "GenSigSendType" SG_ 818 DrPrsntRearDrv_D_Stat 3;
BA_ "WakeupSignal" SG_ 818 DrPrsntRearDrv_D_Stat 1;
BA_ "U_CD764_MY2022_Tx" SG_ 818 DrDrvMsgTxt_B_Rq 1;
BA_ "U_T6_MCA_MY2020_Tx" SG_ 818 DrDrvMsgTxt_B_Rq 1;
BA_ "GenSigSendType" SG_ 818 DrDrvMsgTxt_B_Rq 3;
BA_ "U_CD764_MY2022_Tx" SG_ 818 BLISLEDStatDriverSide 1;
BA_ "U_U55X_MY2022_Tx" SG_ 818 BLISLEDStatDriverSide 1;
BA_ "U_CD542_MY2021_Tx" SG_ 818 BLISLEDStatDriverSide 1;
BA_ "U_T6_MCA_MY2020_Tx" SG_ 818 BLISLEDStatDriverSide 1;
BA_ "U_P702_MY2021_Tx" SG_ 818 BLISLEDStatDriverSide 1;
BA_ "U_CX727_MY2021_Tx" SG_ 818 BLISLEDStatDriverSide 1;
BA_ "U_T6_MCA_MY2020_Rx" SG_ 818 BLISLEDStatDriverSide 1;
BA_ "U_CX727_MY2021_Rx" SG_ 818 BLISLEDStatDriverSide 1;
BA_ "GenSigSendType" SG_ 818 BLISLEDStatDriverSide 3;
BA_ "U_CD764_MY2022_Tx" SG_ 818 ChildLckPw_N_Cnt 1;
BA_ "U_U55X_MY2022_Tx" SG_ 818 ChildLckPw_N_Cnt 1;
BA_ "U_CD542_MY2021_Tx" SG_ 818 ChildLckPw_N_Cnt 1;
BA_ "U_T6_MCA_MY2020_Tx" SG_ 818 ChildLckPw_N_Cnt 1;
BA_ "U_P702_MY2021_Tx" SG_ 818 ChildLckPw_N_Cnt 1;
BA_ "U_CX727_MY2021_Tx" SG_ 818 ChildLckPw_N_Cnt 1;
BA_ "GenSigSendType" SG_ 818 ChildLckPw_N_Cnt 3;
BA_ "WakeupSignal" SG_ 818 ChildLckPw_N_Cnt 1;
BA_ "U_CD764_MY2022_Tx" SG_ 818 WndwDrvSide_D_Stat 1;
BA_ "U_U55X_MY2022_Tx" SG_ 818 WndwDrvSide_D_Stat 1;
BA_ "U_CD542_MY2021_Tx" SG_ 818 WndwDrvSide_D_Stat 1;
BA_ "U_T6_MCA_MY2020_Tx" SG_ 818 WndwDrvSide_D_Stat 1;
BA_ "U_P702_MY2021_Tx" SG_ 818 WndwDrvSide_D_Stat 1;
BA_ "U_CX727_MY2021_Tx" SG_ 818 WndwDrvSide_D_Stat 1;
BA_ "GenSigSendType" SG_ 818 WndwDrvSide_D_Stat 3;
BA_ "U_CD764_MY2022_Tx" SG_ 818 RollCodeDrvDrKeyCyl 1;
BA_ "U_U55X_MY2022_Tx" SG_ 818 RollCodeDrvDrKeyCyl 1;
BA_ "U_CD542_MY2021_Tx" SG_ 818 RollCodeDrvDrKeyCyl 1;
BA_ "U_T6_MCA_MY2020_Tx" SG_ 818 RollCodeDrvDrKeyCyl 1;
BA_ "U_P702_MY2021_Tx" SG_ 818 RollCodeDrvDrKeyCyl 1;
BA_ "U_CX727_MY2021_Tx" SG_ 818 RollCodeDrvDrKeyCyl 1;
BA_ "GenSigSendType" SG_ 818 RollCodeDrvDrKeyCyl 3;
BA_ "U_CD764_MY2022_Tx" SG_ 818 KeyCylSwDrvDr_D_Stat 1;
BA_ "U_U55X_MY2022_Tx" SG_ 818 KeyCylSwDrvDr_D_Stat 1;
BA_ "U_CD542_MY2021_Tx" SG_ 818 KeyCylSwDrvDr_D_Stat 1;
BA_ "U_T6_MCA_MY2020_Tx" SG_ 818 KeyCylSwDrvDr_D_Stat 1;
BA_ "U_P702_MY2021_Tx" SG_ 818 KeyCylSwDrvDr_D_Stat 1;
BA_ "U_CX727_MY2021_Tx" SG_ 818 KeyCylSwDrvDr_D_Stat 1;
BA_ "GenSigSendType" SG_ 818 KeyCylSwDrvDr_D_Stat 3;
BA_ "WakeupSignal" SG_ 818 KeyCylSwDrvDr_D_Stat 1;
BA_ "U_CD764_MY2022_Tx" SG_ 818 Driver_Lock_Sw_Stat 1;
BA_ "U_U55X_MY2022_Tx" SG_ 818 Driver_Lock_Sw_Stat 1;
BA_ "U_CD542_MY2021_Tx" SG_ 818 Driver_Lock_Sw_Stat 1;
BA_ "U_T6_MCA_MY2020_Tx" SG_ 818 Driver_Lock_Sw_Stat 1;
BA_ "U_P702_MY2021_Tx" SG_ 818 Driver_Lock_Sw_Stat 1;
BA_ "U_CX727_MY2021_Tx" SG_ 818 Driver_Lock_Sw_Stat 1;
BA_ "GenSigSendType" SG_ 818 Driver_Lock_Sw_Stat 3;
BA_ "WakeupSignal" SG_ 818 Driver_Lock_Sw_Stat 1;
BA_ "U_CD764_MY2022_Tx" SG_ 818 Driver_Lock_Sw_Cnt 1;
BA_ "U_U55X_MY2022_Tx" SG_ 818 Driver_Lock_Sw_Cnt 1;
BA_ "U_CD542_MY2021_Tx" SG_ 818 Driver_Lock_Sw_Cnt 1;
BA_ "U_T6_MCA_MY2020_Tx" SG_ 818 Driver_Lock_Sw_Cnt 1;
BA_ "U_P702_MY2021_Tx" SG_ 818 Driver_Lock_Sw_Cnt 1;
BA_ "U_CX727_MY2021_Tx" SG_ 818 Driver_Lock_Sw_Cnt 1;
BA_ "GenSigSendType" SG_ 818 Driver_Lock_Sw_Cnt 3;
BA_ "MetaData" SG_ 818 Driver_Lock_Sw_Cnt 1;
BA_ "WakeupSignal" SG_ 818 Driver_Lock_Sw_Cnt 1;
BA_ "U_CD764_MY2022_Tx" SG_ 818 ChildLckPw_D_Rq 1;
BA_ "U_U55X_MY2022_Tx" SG_ 818 ChildLckPw_D_Rq 1;
BA_ "U_CD542_MY2021_Tx" SG_ 818 ChildLckPw_D_Rq 1;
BA_ "U_T6_MCA_MY2020_Tx" SG_ 818 ChildLckPw_D_Rq 1;
BA_ "U_P702_MY2021_Tx" SG_ 818 ChildLckPw_D_Rq 1;
BA_ "U_CX727_MY2021_Tx" SG_ 818 ChildLckPw_D_Rq 1;
BA_ "GenSigSendType" SG_ 818 ChildLckPw_D_Rq 3;
BA_ "WakeupSignal" SG_ 818 ChildLckPw_D_Rq 1;
BA_ "U_CD764_MY2022_Tx" SG_ 818 ChildLckFdbckRd_B_Stat 1;
BA_ "U_U55X_MY2022_Tx" SG_ 818 ChildLckFdbckRd_B_Stat 1;
BA_ "U_CD542_MY2021_Tx" SG_ 818 ChildLckFdbckRd_B_Stat 1;
BA_ "U_T6_MCA_MY2020_Tx" SG_ 818 ChildLckFdbckRd_B_Stat 1;
BA_ "U_P702_MY2021_Tx" SG_ 818 ChildLckFdbckRd_B_Stat 1;
BA_ "U_CX727_MY2021_Tx" SG_ 818 ChildLckFdbckRd_B_Stat 1;
BA_ "GenSigSendType" SG_ 818 ChildLckFdbckRd_B_Stat 3;
BA_ "WakeupSignal" SG_ 818 ChildLckFdbckRd_B_Stat 1;
BA_ "U_CD764_MY2022_Tx" SG_ 818 RvrseMirrorChime_B_Rq 1;
BA_ "U_U55X_MY2022_Tx" SG_ 818 RvrseMirrorChime_B_Rq 1;
BA_ "U_CD542_MY2021_Tx" SG_ 818 RvrseMirrorChime_B_Rq 1;
BA_ "U_T6_MCA_MY2020_Tx" SG_ 818 RvrseMirrorChime_B_Rq 1;
BA_ "U_P702_MY2021_Tx" SG_ 818 RvrseMirrorChime_B_Rq 1;
BA_ "U_CX727_MY2021_Tx" SG_ 818 RvrseMirrorChime_B_Rq 1;
BA_ "U_CD764_MY2022_Rx" SG_ 818 RvrseMirrorChime_B_Rq 1;
BA_ "U_U55X_MY2022_Rx" SG_ 818 RvrseMirrorChime_B_Rq 1;
BA_ "U_CD542_MY2021_Rx" SG_ 818 RvrseMirrorChime_B_Rq 1;
BA_ "U_T6_MCA_MY2020_Rx" SG_ 818 RvrseMirrorChime_B_Rq 1;
BA_ "U_P702_MY2021_Rx" SG_ 818 RvrseMirrorChime_B_Rq 1;
BA_ "U_CX727_MY2021_Rx" SG_ 818 RvrseMirrorChime_B_Rq 1;
BA_ "GenSigSendType" SG_ 818 RvrseMirrorChime_B_Rq 3;
BA_ "U_CX727_MY2021_Rx" SG_ 817 VehLckInd_D_Rq 1;
BA_ "U_CD764_MY2022_Rx" SG_ 817 VehLckInd_D_Rq 1;
BA_ "U_U55X_MY2022_Rx" SG_ 817 VehLckInd_D_Rq 1;
BA_ "U_CD542_MY2021_Rx" SG_ 817 VehLckInd_D_Rq 1;
BA_ "U_T6_MCA_MY2020_Rx" SG_ 817 VehLckInd_D_Rq 1;
BA_ "U_P702_MY2021_Rx" SG_ 817 VehLckInd_D_Rq 1;
BA_ "U_U55X_MY2022_Rx" SG_ 817 DrTgateOpen_B_Rq 1;
BA_ "U_CD542_MY2021_Rx" SG_ 817 DrTgateOpen_B_Rq 1;
BA_ "U_T6_MCA_MY2020_Rx" SG_ 817 DrTgateOpen_B_Rq 1;
BA_ "U_CX727_MY2021_Rx" SG_ 817 DrTgateOpen_B_Rq 1;
BA_ "WakeupSignal" SG_ 817 DrTgateOpen_B_Rq 1;
BA_ "U_U55X_MY2022_Rx" SG_ 817 DrTgateExtSwMde_B_Stat 1;
BA_ "U_CD542_MY2021_Rx" SG_ 817 DrTgateExtSwMde_B_Stat 1;
BA_ "U_T6_MCA_MY2020_Rx" SG_ 817 DrTgateExtSwMde_B_Stat 1;
BA_ "U_CX727_MY2021_Rx" SG_ 817 DrTgateExtSwMde_B_Stat 1;
BA_ "WakeupSignal" SG_ 817 DrTgateExtSwMde_B_Stat 1;
BA_ "U_U55X_MY2022_Rx" SG_ 817 Remote_Device_Feedback 1;
BA_ "U_T6_MCA_MY2020_Rx" SG_ 817 Remote_Device_Feedback 1;
BA_ "U_P702_MY2021_Rx" SG_ 817 Remote_Device_Feedback 1;
BA_ "U_CX727_MY2021_Rx" SG_ 817 Remote_Device_Feedback 1;
BA_ "WakeupSignal" SG_ 817 Remote_Device_Feedback 1;
BA_ "WakeupSignal" SG_ 817 R_Pwr_Sliding_Dr_Rqst 1;
BA_ "U_U55X_MY2022_Rx" SG_ 817 Power_Liftgate_Rqst 1;
BA_ "U_CD542_MY2021_Rx" SG_ 817 Power_Liftgate_Rqst 1;
BA_ "U_T6_MCA_MY2020_Rx" SG_ 817 Power_Liftgate_Rqst 1;
BA_ "U_CX727_MY2021_Rx" SG_ 817 Power_Liftgate_Rqst 1;
BA_ "WakeupSignal" SG_ 817 Power_Liftgate_Rqst 1;
BA_ "U_U55X_MY2022_Rx" SG_ 817 Power_Decklid_Rqst 1;
BA_ "U_CD542_MY2021_Rx" SG_ 817 Power_Decklid_Rqst 1;
BA_ "U_T6_MCA_MY2020_Rx" SG_ 817 Power_Decklid_Rqst 1;
BA_ "U_CX727_MY2021_Rx" SG_ 817 Power_Decklid_Rqst 1;
BA_ "WakeupSignal" SG_ 817 Power_Decklid_Rqst 1;
BA_ "WakeupSignal" SG_ 817 L_Pwr_Sliding_Dr_Rqst 1;
BA_ "U_U55X_MY2022_Rx" SG_ 817 Keyfob_Pad_Msg_Count 1;
BA_ "U_CD542_MY2021_Rx" SG_ 817 Keyfob_Pad_Msg_Count 1;
BA_ "U_T6_MCA_MY2020_Rx" SG_ 817 Keyfob_Pad_Msg_Count 1;
BA_ "U_CX727_MY2021_Rx" SG_ 817 Keyfob_Pad_Msg_Count 1;
BA_ "WakeupSignal" SG_ 817 Keyfob_Pad_Msg_Count 1;
BA_ "U_CX727_MY2021_Rx" SG_ 817 Veh_Lock_Requestor 1;
BA_ "U_CD764_MY2022_Rx" SG_ 817 Veh_Lock_Requestor 1;
BA_ "U_U55X_MY2022_Rx" SG_ 817 Veh_Lock_Requestor 1;
BA_ "U_CD542_MY2021_Rx" SG_ 817 Veh_Lock_Requestor 1;
BA_ "U_T6_MCA_MY2020_Rx" SG_ 817 Veh_Lock_Requestor 1;
BA_ "U_P702_MY2021_Rx" SG_ 817 Veh_Lock_Requestor 1;
BA_ "WakeupSignal" SG_ 817 Veh_Lock_Requestor 1;
BA_ "U_CX727_MY2021_Rx" SG_ 817 Veh_Lock_EvNum 1;
BA_ "U_CD764_MY2022_Rx" SG_ 817 Veh_Lock_EvNum 1;
BA_ "U_U55X_MY2022_Rx" SG_ 817 Veh_Lock_EvNum 1;
BA_ "U_CD542_MY2021_Rx" SG_ 817 Veh_Lock_EvNum 1;
BA_ "U_T6_MCA_MY2020_Rx" SG_ 817 Veh_Lock_EvNum 1;
BA_ "U_P702_MY2021_Rx" SG_ 817 Veh_Lock_EvNum 1;
BA_ "WakeupSignal" SG_ 817 Veh_Lock_EvNum 1;
BA_ "U_CX727_MY2021_Rx" SG_ 817 Veh_Lock_Sub_Id 1;
BA_ "U_CD764_MY2022_Rx" SG_ 817 Veh_Lock_Sub_Id 1;
BA_ "U_U55X_MY2022_Rx" SG_ 817 Veh_Lock_Sub_Id 1;
BA_ "U_CD542_MY2021_Rx" SG_ 817 Veh_Lock_Sub_Id 1;
BA_ "U_T6_MCA_MY2020_Rx" SG_ 817 Veh_Lock_Sub_Id 1;
BA_ "U_P702_MY2021_Rx" SG_ 817 Veh_Lock_Sub_Id 1;
BA_ "U_CD764_MY2022_Rx" SG_ 817 ChildLck_D_Dsply 1;
BA_ "U_U55X_MY2022_Rx" SG_ 817 ChildLck_D_Dsply 1;
BA_ "U_CD542_MY2021_Rx" SG_ 817 ChildLck_D_Dsply 1;
BA_ "U_T6_MCA_MY2020_Rx" SG_ 817 ChildLck_D_Dsply 1;
BA_ "U_P702_MY2021_Rx" SG_ 817 ChildLck_D_Dsply 1;
BA_ "U_CX727_MY2021_Rx" SG_ 817 ChildLck_D_Dsply 1;
BA_ "GenSigStartValue" SG_ 817 ChildLck_D_Dsply 1;
BA_ "GenSigStartValueInteger" SG_ 817 ChildLck_D_Dsply 1;
BA_ "WakeupSignal" SG_ 817 ChildLck_D_Dsply 1;
BA_ "U_CD764_MY2022_Rx" SG_ 817 WindowLockout_B_Stat 1;
BA_ "U_U55X_MY2022_Rx" SG_ 817 WindowLockout_B_Stat 1;
BA_ "U_CD542_MY2021_Rx" SG_ 817 WindowLockout_B_Stat 1;
BA_ "U_T6_MCA_MY2020_Rx" SG_ 817 WindowLockout_B_Stat 1;
BA_ "U_P702_MY2021_Rx" SG_ 817 WindowLockout_B_Stat 1;
BA_ "U_CX727_MY2021_Rx" SG_ 817 WindowLockout_B_Stat 1;
BA_ "U_CD764_MY2022_Rx" SG_ 817 RollCodeUnlock 1;
BA_ "U_U55X_MY2022_Rx" SG_ 817 RollCodeUnlock 1;
BA_ "U_CD542_MY2021_Rx" SG_ 817 RollCodeUnlock 1;
BA_ "U_T6_MCA_MY2020_Rx" SG_ 817 RollCodeUnlock 1;
BA_ "U_P702_MY2021_Rx" SG_ 817 RollCodeUnlock 1;
BA_ "U_CX727_MY2021_Rx" SG_ 817 RollCodeUnlock 1;
BA_ "WakeupSignal" SG_ 817 Lockmsgtxt_D_Rq 1;
BA_ "U_U55X_MY2022_Rx" SG_ 817 LockInhibit 1;
BA_ "U_CD542_MY2021_Rx" SG_ 817 LockInhibit 1;
BA_ "U_T6_MCA_MY2020_Rx" SG_ 817 LockInhibit 1;
BA_ "U_CX727_MY2021_Rx" SG_ 817 LockInhibit 1;
BA_ "WakeupSignal" SG_ 817 LockInhibit 1;
BA_ "U_CX727_MY2021_Rx" SG_ 817 Veh_Lock_Status 1;
BA_ "U_CD764_MY2022_Rx" SG_ 817 Veh_Lock_Status 1;
BA_ "U_U55X_MY2022_Rx" SG_ 817 Veh_Lock_Status 1;
BA_ "U_CD542_MY2021_Rx" SG_ 817 Veh_Lock_Status 1;
BA_ "U_T6_MCA_MY2020_Rx" SG_ 817 Veh_Lock_Status 1;
BA_ "U_P702_MY2021_Rx" SG_ 817 Veh_Lock_Status 1;
BA_ "GenSigStartValue" SG_ 817 Veh_Lock_Status 1;
BA_ "GenSigStartValueInteger" SG_ 817 Veh_Lock_Status 1;
BA_ "WakeupSignal" SG_ 817 Veh_Lock_Status 1;
BA_ "U_U55X_MY2022_Rx" SG_ 817 FobComm_D_Stat 1;
BA_ "U_T6_MCA_MY2020_Rx" SG_ 817 FobComm_D_Stat 1;
BA_ "U_P702_MY2021_Rx" SG_ 817 FobComm_D_Stat 1;
BA_ "U_CX727_MY2021_Rx" SG_ 817 FobComm_D_Stat 1;
BA_ "U_CD542_MY2021_Tx" SG_ 1091 ParkLampTrlrOut_B_Stat 1;
BA_ "U_T6_MCA_MY2020_Tx" SG_ 1091 ParkLampTrlrOut_B_Stat 1;
BA_ "U_P702_MY2021_Tx" SG_ 1091 ParkLampTrlrOut_B_Stat 1;
BA_ "GenSigSendType" SG_ 1091 ParkLampTrlrOut_B_Stat 3;
BA_ "U_CD542_MY2021_Tx" SG_ 1091 TowBarMsgTxt_D_Rq 1;
BA_ "U_T6_MCA_MY2020_Tx" SG_ 1091 TowBarMsgTxt_D_Rq 1;
BA_ "GenSigSendType" SG_ 1091 TowBarMsgTxt_D_Rq 3;
BA_ "U_CD542_MY2021_Tx" SG_ 1091 TrlrLampCtl_D_Stat 1;
BA_ "U_T6_MCA_MY2020_Tx" SG_ 1091 TrlrLampCtl_D_Stat 1;
BA_ "U_P702_MY2021_Tx" SG_ 1091 TrlrLampCtl_D_Stat 1;
BA_ "GenSigSendType" SG_ 1091 TrlrLampCtl_D_Stat 3;
BA_ "U_CD542_MY2021_Tx" SG_ 1091 TrlrBattChrg_D_Stat 1;
BA_ "U_T6_MCA_MY2020_Tx" SG_ 1091 TrlrBattChrg_D_Stat 1;
BA_ "U_P702_MY2021_Tx" SG_ 1091 TrlrBattChrg_D_Stat 1;
BA_ "GenSigSendType" SG_ 1091 TrlrBattChrg_D_Stat 3;
BA_ "U_CD542_MY2021_Tx" SG_ 1091 StopLampTrlrOut_B_Stat 1;
BA_ "U_T6_MCA_MY2020_Tx" SG_ 1091 StopLampTrlrOut_B_Stat 1;
BA_ "U_P702_MY2021_Tx" SG_ 1091 StopLampTrlrOut_B_Stat 1;
BA_ "GenSigSendType" SG_ 1091 StopLampTrlrOut_B_Stat 3;
BA_ "U_CD542_MY2021_Tx" SG_ 1091 TurnLampTrlrRr_B_Stat 1;
BA_ "U_T6_MCA_MY2020_Tx" SG_ 1091 TurnLampTrlrRr_B_Stat 1;
BA_ "U_P702_MY2021_Tx" SG_ 1091 TurnLampTrlrRr_B_Stat 1;
BA_ "GenSigSendType" SG_ 1091 TurnLampTrlrRr_B_Stat 3;
BA_ "U_CD542_MY2021_Tx" SG_ 1091 TurnLampTrlrRl_B_Stat 1;
BA_ "U_T6_MCA_MY2020_Tx" SG_ 1091 TurnLampTrlrRl_B_Stat 1;
BA_ "U_P702_MY2021_Tx" SG_ 1091 TurnLampTrlrRl_B_Stat 1;
BA_ "GenSigSendType" SG_ 1091 TurnLampTrlrRl_B_Stat 3;
BA_ "U_CD542_MY2021_Tx" SG_ 1091 TrlrLampCnnct_B_Actl 1;
BA_ "U_T6_MCA_MY2020_Tx" SG_ 1091 TrlrLampCnnct_B_Actl 1;
BA_ "U_P702_MY2021_Tx" SG_ 1091 TrlrLampCnnct_B_Actl 1;
BA_ "U_CX727_MY2021_Rx" SG_ 1091 TrlrLampCnnct_B_Actl 1;
BA_ "GenSigSendType" SG_ 1091 TrlrLampCnnct_B_Actl 3;
BA_ "U_CD764_MY2022_Tx" SG_ 1865 TesterPhysicalResPDM 1;
BA_ "U_U55X_MY2022_Tx" SG_ 1865 TesterPhysicalResPDM 1;
BA_ "U_CD542_MY2021_Tx" SG_ 1865 TesterPhysicalResPDM 1;
BA_ "U_T6_MCA_MY2020_Tx" SG_ 1865 TesterPhysicalResPDM 1;
BA_ "U_P702_MY2021_Tx" SG_ 1865 TesterPhysicalResPDM 1;
BA_ "GenSigSendType" SG_ 1865 TesterPhysicalResPDM 3;
BA_ "U_CD764_MY2022_Rx" SG_ 1857 TesterPhysicalReqPDM 1;
BA_ "U_U55X_MY2022_Rx" SG_ 1857 TesterPhysicalReqPDM 1;
BA_ "U_CD542_MY2021_Rx" SG_ 1857 TesterPhysicalReqPDM 1;
BA_ "U_T6_MCA_MY2020_Rx" SG_ 1857 TesterPhysicalReqPDM 1;
BA_ "U_P702_MY2021_Rx" SG_ 1857 TesterPhysicalReqPDM 1;
BA_ "GenSigSendType" SG_ 1857 TesterPhysicalReqPDM 3;
BA_ "U_CD764_MY2022_Tx" SG_ 1819 TesterPhysicalResSCMH 1;
BA_ "U_U55X_MY2022_Tx" SG_ 1819 TesterPhysicalResSCMH 1;
BA_ "U_P702_MY2021_Tx" SG_ 1819 TesterPhysicalResSCMH 1;
BA_ "GenSigSendType" SG_ 1819 TesterPhysicalResSCMH 3;
BA_ "U_CD764_MY2022_Tx" SG_ 1818 TesterPhysicalResSCMG 1;
BA_ "U_U55X_MY2022_Tx" SG_ 1818 TesterPhysicalResSCMG 1;
BA_ "U_P702_MY2021_Tx" SG_ 1818 TesterPhysicalResSCMG 1;
BA_ "GenSigSendType" SG_ 1818 TesterPhysicalResSCMG 3;
BA_ "U_CD764_MY2022_Rx" SG_ 1811 TesterPhysicalReqSCMH 1;
BA_ "U_U55X_MY2022_Rx" SG_ 1811 TesterPhysicalReqSCMH 1;
BA_ "U_P702_MY2021_Rx" SG_ 1811 TesterPhysicalReqSCMH 1;
BA_ "GenSigSendType" SG_ 1811 TesterPhysicalReqSCMH 3;
BA_ "U_CD764_MY2022_Rx" SG_ 1810 TesterPhysicalReqSCMG 1;
BA_ "U_U55X_MY2022_Rx" SG_ 1810 TesterPhysicalReqSCMG 1;
BA_ "U_P702_MY2021_Rx" SG_ 1810 TesterPhysicalReqSCMG 1;
BA_ "GenSigSendType" SG_ 1810 TesterPhysicalReqSCMG 3;
BA_ "U_CD764_MY2022_Tx" SG_ 1310 GWM_Network_Mgmt_MS1 1;
BA_ "ECGUsedTxSignal" SG_ 1310 GWM_Network_Mgmt_MS1 1;
BA_ "U_P702_MY2021_Rx" SG_ 1310 GWM_Network_Mgmt_MS1 1;
BA_ "GenSigSendType" SG_ 1310 GWM_Network_Mgmt_MS1 3;
BA_ "U_CD764_MY2022_Rx" SG_ 1066 BattULo_U_Actl_UB 1;
BA_ "U_U55X_MY2022_Rx" SG_ 1066 BattULo_U_Actl_UB 1;
BA_ "U_CD542_MY2021_Rx" SG_ 1066 BattULo_U_Actl_UB 1;
BA_ "U_T6_MCA_MY2020_Rx" SG_ 1066 BattULo_U_Actl_UB 1;
BA_ "U_P702_MY2021_Rx" SG_ 1066 BattULo_U_Actl_UB 1;
BA_ "U_CX727_MY2021_Rx" SG_ 1066 BattULo_U_Actl_UB 1;
BA_ "U_CD764_MY2022_Rx" SG_ 1066 BattULo_U_Actl 1;
BA_ "U_U55X_MY2022_Rx" SG_ 1066 BattULo_U_Actl 1;
BA_ "U_CD542_MY2021_Rx" SG_ 1066 BattULo_U_Actl 1;
BA_ "U_T6_MCA_MY2020_Rx" SG_ 1066 BattULo_U_Actl 1;
BA_ "U_P702_MY2021_Rx" SG_ 1066 BattULo_U_Actl 1;
BA_ "U_CX727_MY2021_Rx" SG_ 1066 BattULo_U_Actl 1;
BA_ "GenSigStartValue" SG_ 1066 BattULo_U_Actl 255;
BA_ "GenSigStartValueInteger" SG_ 1066 BattULo_U_Actl 255;
BA_ "U_CD764_MY2022_Rx" SG_ 1066 PwSrcULo_I_Mx 1;
BA_ "U_U55X_MY2022_Rx" SG_ 1066 PwSrcULo_I_Mx 1;
BA_ "U_CD542_MY2021_Rx" SG_ 1066 PwSrcULo_I_Mx 1;
BA_ "U_T6_MCA_MY2020_Rx" SG_ 1066 PwSrcULo_I_Mx 1;
BA_ "U_P702_MY2021_Rx" SG_ 1066 PwSrcULo_I_Mx 1;
BA_ "U_CX727_MY2021_Rx" SG_ 1066 PwSrcULo_I_Mx 1;
BA_ "U_CD764_MY2022_Rx" SG_ 1066 PwSrcULo_I_Actl 1;
BA_ "U_U55X_MY2022_Rx" SG_ 1066 PwSrcULo_I_Actl 1;
BA_ "U_CD542_MY2021_Rx" SG_ 1066 PwSrcULo_I_Actl 1;
BA_ "U_T6_MCA_MY2020_Rx" SG_ 1066 PwSrcULo_I_Actl 1;
BA_ "U_P702_MY2021_Rx" SG_ 1066 PwSrcULo_I_Actl 1;
BA_ "U_CX727_MY2021_Rx" SG_ 1066 PwSrcULo_I_Actl 1;
BA_ "U_CD764_MY2022_Rx" SG_ 1066 PwSrcULo_I_Mx_UB 1;
BA_ "U_U55X_MY2022_Rx" SG_ 1066 PwSrcULo_I_Mx_UB 1;
BA_ "U_CD542_MY2021_Rx" SG_ 1066 PwSrcULo_I_Mx_UB 1;
BA_ "U_T6_MCA_MY2020_Rx" SG_ 1066 PwSrcULo_I_Mx_UB 1;
BA_ "U_P702_MY2021_Rx" SG_ 1066 PwSrcULo_I_Mx_UB 1;
BA_ "U_CX727_MY2021_Rx" SG_ 1066 PwSrcULo_I_Mx_UB 1;
BA_ "U_CD764_MY2022_Rx" SG_ 1066 PwSrcULo_I_Actl_UB 1;
BA_ "U_U55X_MY2022_Rx" SG_ 1066 PwSrcULo_I_Actl_UB 1;
BA_ "U_CD542_MY2021_Rx" SG_ 1066 PwSrcULo_I_Actl_UB 1;
BA_ "U_T6_MCA_MY2020_Rx" SG_ 1066 PwSrcULo_I_Actl_UB 1;
BA_ "U_P702_MY2021_Rx" SG_ 1066 PwSrcULo_I_Actl_UB 1;
BA_ "U_CX727_MY2021_Rx" SG_ 1066 PwSrcULo_I_Actl_UB 1;
BA_ "WakeupSignal" SG_ 994 Pers4OptIn_B_Stats 1;
BA_ "WakeupSignal" SG_ 994 Pers3OptIn_B_Stats 1;
BA_ "WakeupSignal" SG_ 994 Pers2OptIn_B_Stats 1;
BA_ "WakeupSignal" SG_ 994 Pers1OptIn_B_Stats 1;
BA_ "U_CD542_MY2021_Rx" SG_ 994 CtrStkPersIndex_D_Actl 1;
BA_ "U_T6_MCA_MY2020_Rx" SG_ 994 CtrStkPersIndex_D_Actl 1;
BA_ "U_CX727_MY2021_Rx" SG_ 994 CtrStkPersIndex_D_Actl 1;
BA_ "U_CD764_MY2022_Rx" SG_ 994 CtrStkPersIndex_D_Actl 1;
BA_ "U_U55X_MY2022_Rx" SG_ 994 CtrStkPersIndex_D_Actl 1;
BA_ "U_P702_MY2021_Rx" SG_ 994 CtrStkPersIndex_D_Actl 1;
BA_ "GenSigStartValue" SG_ 994 CtrStkPersIndex_D_Actl 4;
BA_ "GenSigStartValueInteger" SG_ 994 CtrStkPersIndex_D_Actl 4;
BA_ "U_CD764_MY2022_Rx" SG_ 994 CtrStkFeatNoActl 1;
BA_ "U_U55X_MY2022_Rx" SG_ 994 CtrStkFeatNoActl 1;
BA_ "U_CD542_MY2021_Rx" SG_ 994 CtrStkFeatNoActl 1;
BA_ "U_T6_MCA_MY2020_Rx" SG_ 994 CtrStkFeatNoActl 1;
BA_ "U_P702_MY2021_Rx" SG_ 994 CtrStkFeatNoActl 1;
BA_ "U_CX727_MY2021_Rx" SG_ 994 CtrStkFeatNoActl 1;
BA_ "U_CD764_MY2022_Rx" SG_ 994 CtrStkFeatConfigActl 1;
BA_ "U_U55X_MY2022_Rx" SG_ 994 CtrStkFeatConfigActl 1;
BA_ "U_CD542_MY2021_Rx" SG_ 994 CtrStkFeatConfigActl 1;
BA_ "U_T6_MCA_MY2020_Rx" SG_ 994 CtrStkFeatConfigActl 1;
BA_ "U_P702_MY2021_Rx" SG_ 994 CtrStkFeatConfigActl 1;
BA_ "U_CX727_MY2021_Rx" SG_ 994 CtrStkFeatConfigActl 1;
BA_ "U_CD542_MY2021_Rx" SG_ 994 CtrStkDsplyOp_D_Rq 1;
BA_ "U_T6_MCA_MY2020_Rx" SG_ 994 CtrStkDsplyOp_D_Rq 1;
BA_ "U_CX727_MY2021_Rx" SG_ 994 CtrStkDsplyOp_D_Rq 1;
BA_ "U_CD764_MY2022_Rx" SG_ 994 CtrStkDsplyOp_D_Rq 1;
BA_ "U_U55X_MY2022_Rx" SG_ 994 CtrStkDsplyOp_D_Rq 1;
BA_ "U_P702_MY2021_Rx" SG_ 994 CtrStkDsplyOp_D_Rq 1;
BA_ "U_CD764_MY2022_Rx" SG_ 994 PersStore_D_Rq 1;
BA_ "U_CD542_MY2021_Rx" SG_ 994 PersStore_D_Rq 1;
BA_ "U_T6_MCA_MY2020_Rx" SG_ 994 PersStore_D_Rq 1;
BA_ "U_P702_MY2021_Rx" SG_ 994 PersStore_D_Rq 1;
BA_ "U_CX727_MY2021_Rx" SG_ 994 PersStore_D_Rq 1;
VAL_ 798 ClrExitAsst_D_Stat 0 "Null" 1 "Disabled" 2 "Enabled" 3 "NotUsed" ;
VAL_ 798 ClrExitAsstMsgTxt2_D_Rq 0 "NoMessage" 1 "RearLeft" 2 "RearRight" 3 "FrontLeft" 4 "FrontRight" 5 "RearLeftRearRight" 6 "FrontLeftFrontRight" 7 "RearLeftFrontRight" 8 "FrontLeftRearRight" 9 "NotUsed_1" 10 "NotUsed_2" 11 "NotUsed_3" 12 "NotUsed_4" 13 "NotUsed_5" 14 "NotUsed_6" 15 "NotUsed_7" ;
VAL_ 798 EmPrflNo_D_Rq_UB 1 "Fresh_data" 0 "Unchanged_data" ;
VAL_ 798 EmPrflNo_D_Rq 7 "NotUsed_3" 6 "NotUsed_2" 5 "NotUsed_1" 4 "Pers4" 3 "Pers3" 2 "Pers2" 1 "Pers1" 0 "Null" ;
VAL_ 798 EmPrflKeyAssoc_D_Rq_UB 1 "Fresh_data" 0 "Unchanged_data" ;
VAL_ 798 EmPrflKeyAssoc_D_Rq 7 "NotUsed_3" 6 "DisassociatePhone" 5 "EnterPhoneAssociation" 4 "OverwriteKey" 3 "DisassociateKey" 2 "ExitKeyAssociation" 1 "EnterKeyAssociation" 0 "Null" ;
VAL_ 798 BattTracDrvSustn_B_Rq_UB 1 "Fresh_data" 0 "Unchanged_data" ;
VAL_ 798 BattTracCool_B_Actl_UB 1 "Fresh_data" 0 "Unchanged_data" ;
VAL_ 798 BattTracCool_B_Actl 1 "On" 0 "Off" ;
VAL_ 798 BattTracDrvSustn_B_Rq 1 "Active" 0 "Inactive" ;
VAL_ 798 ExitNotClrRight_B_Stat_UB 1 "Fresh_data" 0 "Unchanged_data" ;
VAL_ 798 ExitNotClrLeft_B_Stat_UB 1 "Fresh_data" 0 "Unchanged_data" ;
VAL_ 798 ExitNotClrRight_B_Stat 1 "True" 0 "False" ;
VAL_ 798 ExitNotClrLeft_B_Stat 1 "True" 0 "False" ;
VAL_ 798 ClimtCool_D_RqPt_UB 1 "Fresh_data" 0 "Unchanged_data" ;
VAL_ 798 ClimtCool_D_RqPt 3 "NotUsed_2" 2 "NotUsed_1" 1 "On" 0 "Off" ;
VAL_ 798 PudSptLghtRight_D_Rq_UB 1 "Fresh_data" 0 "Unchanged_data" ;
VAL_ 798 PudSptLghtLeft_D_Rq_UB 1 "Fresh_data" 0 "Unchanged_data" ;
VAL_ 798 PudSptLghtRight_D_Rq 3 "NotUsed" 2 "On" 1 "Off" 0 "Null" ;
VAL_ 798 PwRnngBoardPoll_D_Stat_UB 1 "Fresh_data" 0 "Unchanged_data" ;
VAL_ 798 PwRnngBoardPoll_D_Stat 3 "NotUsed" 2 "PkPresent" 1 "PkNotPresent" 0 "NotPolling" ;
VAL_ 798 AirCondRec_B_RqVehEl_UB 1 "Fresh_data" 0 "Unchanged_data" ;
VAL_ 798 AirCondRec_B_RqVehEl 1 "Yes" 0 "No" ;
VAL_ 798 RmtCtl_D_Stat 15 "Faulty" 14 "NotUsed_5" 13 "NotUsed_4" 12 "NotUsed_3" 11 "NotUsed_2" 10 "NotUsed_1" 9 "Shutdown" 8 "ManeuverFinished" 7 "ReadyForResume" 6 "Pause" 5 "Maneuvering" 4 "ReadyForManeuvering" 3 "Activation" 2 "Initialize" 1 "Preparation" 0 "Disabled" ;
VAL_ 798 RmtCtl_D_Stat_UB 1 "Fresh_data" 0 "Unchanged_data" ;
VAL_ 798 PudSptLghtLeft_D_Rq 3 "NotUsed" 2 "On" 1 "Off" 0 "Null" ;
VAL_ 798 PoliceDmngLvl_D_Stat 7 "NotUsed" 6 "Off_Night" 5 "Off_Day" 4 "Low1Night" 3 "Low1Day" 2 "Inactive" 1 "Decommissioned" 0 "Null" ;
VAL_ 798 VehWlcmFrwlMde_D_Stat_UB 1 "Fresh_data" 0 "Unchanged_data" ;
VAL_ 798 VehWlcmFrwl_D_Stat_UB 1 "Fresh_data" 0 "Unchanged_data" ;
VAL_ 798 VehWlcmFrwlMde_D_Stat 7 "IlluminatedExit" 6 "CourtesyLightingDelayExt" 5 "CourtesyLightingExtended" 4 "CourtesyLightingDelayAll" 3 "CourtesyLightingAll" 2 "IlluminatedEntry" 1 "Approach" 0 "Null" ;
VAL_ 798 VehWlcmFrwl_D_Stat 3 "RunStart" 2 "Farewell" 1 "Welcome" 0 "Null" ;
VAL_ 798 PoliceDmngLvl_D_Stat_UB 1 "Fresh_data" 0 "Unchanged_data" ;
VAL_ 374 GearEngag_D_Actl 7 "Undefined" 6 "Fwd_Clutch_Fully_Engaged" 5 "Neutral_Idle" 4 "Disengaged_to_Neutral_Idle" 3 "Disengaged_to_Neutral_Park" 2 "Engagement_in_Progress" 1 "InitializeFwdClutchEngagmt" 0 "Park_Neutral" ;
VAL_ 374 TrnRng_D_Rq 15 "Fault" 14 "Unknown_Position" 13 "NotUsed_2" 12 "NotUsed_1" 11 "Range6" 10 "Range5" 9 "Range4" 8 "Range3_M3_L3" 7 "Range2_M2_L2" 6 "Range1_M1_L1" 5 "Low" 4 "Sport_DriveSport_Mposition" 3 "Drive" 2 "Neutral" 1 "Reverse" 0 "Park" ;
VAL_ 374 TrnPrkSys_D_Actl 15 "Faulty" 14 "NotUsed_5" 13 "NotUsed_4" 12 "NotUsed_3" 11 "NotUsed_2" 10 "NotUsed_1" 9 "FrequencyError" 8 "OutOfRangeHigh" 7 "OutOfRangeLow" 6 "Override" 5 "OutOfPark" 4 "TransitionCloseToOutOfPark" 3 "AtNoSpring" 2 "TransitionCloseToPark" 1 "Park" 0 "NotKnown" ;
VAL_ 374 GearLvr_D_ActlDrv 15 "Fault" 14 "Unknown_Position" 13 "NotUsed_2" 12 "NotUsed_1" 11 "Range6" 10 "Range5" 9 "Range4" 8 "Range3_M3_L3" 7 "Range2_M2_L2" 6 "Range1_M1_L1" 5 "Low" 4 "Sport_DriveSport_Mposition" 3 "Drive" 2 "Neutral" 1 "Reverse" 0 "Park" ;
VAL_ 374 GearPos_D_Trg 15 "Unknown" 14 "Reverse" 13 "Undefined_5" 12 "Undefined_4" 11 "Undefined_3" 10 "Tenth" 9 "Ninth" 8 "Eighth" 7 "Seventh" 6 "Sixth" 5 "Fifth" 4 "Fourth" 3 "Third" 2 "Second" 1 "First" 0 "Neutral" ;
VAL_ 374 GearPos_D_Actl 15 "Unknown" 14 "Reverse" 13 "Undefined_5" 12 "Undefined_4" 11 "Undefined_3" 10 "Tenth" 9 "Ninth" 8 "Eighth" 7 "Seventh" 6 "Sixth" 5 "Fifth" 4 "Fourth" 3 "Third" 2 "Second" 1 "First" 0 "Neutral" ;
VAL_ 662 Running_Board_Cmd2 3 "Unused" 2 "Manually_Deployed" 1 "All_Enabled" 0 "All_Disabled" ;
VAL_ 662 Third_Rear_Set_Temp 31 "HI" 30 "29_5" 29 "29_0" 28 "28_5" 27 "28_0" 26 "27_5" 25 "27_0" 24 "26_5" 23 "26_0" 22 "25_5" 21 "25_0" 20 "24_5" 19 "24_0" 18 "23_5" 17 "23_0" 16 "22_5" 15 "22_0" 14 "21_5" 13 "21_0" 12 "20_5" 11 "20_0" 10 "19_5" 9 "19_0" 8 "18_5" 7 "18_0" 6 "17_5" 5 "17_0" 4 "16_5" 3 "16_0" 2 "15_5" 1 "LO" 0 "No_Request" ;
VAL_ 662 Third_Rear_Blower_Speed 15 "NotUsed_6" 14 "NotUsed_5" 13 "NotUsed_4" 12 "NotUsed_3" 11 "NotUsed_2" 10 "Zero_Blower" 9 "Max_Blower" 8 "Min_Blower" 7 "Blower_Speed_7" 6 "Blower_Speed_6" 5 "Blower_Speed_5" 4 "Blower_Speed_4" 3 "Blower_Speed_3" 2 "Blower_Speed_2" 1 "Blower_Speed_1" 0 "No_Request" ;
VAL_ 662 Rear_Temp 15 "NotUsed_6" 14 "NotUsed_5" 13 "NotUsed_4" 12 "NotUsed_3" 11 "NotUsed_2" 10 "NotUsed_1" 9 "Max_Heating" 8 "Level_3_Heating" 7 "Level_2_Heating" 6 "Level_1_Heating" 5 "No_Heating_Cooling" 4 "Level_1_Cooling" 3 "Level_2_Cooling" 2 "Level_3_Cooling" 1 "Max_Cooling" 0 "No_Request" ;
VAL_ 662 Rear_Set_Temp 31 "HI" 30 "29_5" 29 "29_0" 28 "28_5" 27 "28_0" 26 "27_5" 25 "27_0" 24 "26_5" 23 "26_0" 22 "25_5" 21 "25_0" 20 "24_5" 19 "24_0" 18 "23_5" 17 "23_0" 16 "22_5" 15 "22_0" 14 "21_5" 13 "21_0" 12 "20_5" 11 "20_0" 10 "19_5" 9 "19_0" 8 "18_5" 7 "18_0" 6 "17_5" 5 "17_0" 4 "16_5" 3 "16_0" 2 "15_5" 1 "LO" 0 "No_Request" ;
VAL_ 662 Rear_Blower_Speed 15 "NotUsed_6" 14 "NotUsed_5" 13 "NotUsed_4" 12 "NotUsed_3" 11 "NotUsed_2" 10 "Zero_Blower" 9 "Max_Blower" 8 "Min_Blower" 7 "Blower_Speed_7" 6 "Blower_Speed_6" 5 "Blower_Speed_5" 4 "Blower_Speed_4" 3 "Blower_Speed_3" 2 "Blower_Speed_2" 1 "Blower_Speed_1" 0 "No_Request" ;
VAL_ 670 DrHandleOuterRl_D_Stat 7 "NotUsed" 6 "Transition" 5 "FlushFault" 4 "DeployFault2" 3 "DeployFault1" 2 "Flush" 1 "Deploy" 0 "None" ;
VAL_ 670 DrHandleOuterFl_D_Stat 7 "NotUsed" 6 "Transition" 5 "FlushFault" 4 "DeployFault2" 3 "DeployFault1" 2 "Flush" 1 "Deploy" 0 "None" ;
VAL_ 669 DrHandleOuterRr_D_Stat 7 "NotUsed" 6 "Transition" 5 "FlushFault" 4 "DeployFault2" 3 "DeployFault1" 2 "Flush" 1 "Deploy" 0 "None" ;
VAL_ 669 DrHandleOuterFr_D_Stat 7 "NotUsed" 6 "Transition" 5 "FlushFault" 4 "DeployFault2" 3 "DeployFault1" 2 "Flush" 1 "Deploy" 0 "None" ;
VAL_ 1079 ApaMde_D_Stat_UB 1 "Fresh_data" 0 "Unchanged_data" ;
VAL_ 1079 ApaMde_D_Stat 7 "NotUsed" 6 "RePA" 5 "ParkIn" 4 "POA" 3 "PPA" 2 "SAPP" 1 "Off" 0 "Null" ;
VAL_ 1079 TrlrAidEnbl_D2_Stat_UB 1 "Fresh_data" 0 "Unchanged_data" ;
VAL_ 1079 TrlrAidEnbl_D2_Stat 7 "NotUsed_1" 6 "TbaActiveExpertActive" 5 "TbaActiveExpertAvail" 4 "TbaOffTrgActive" 3 "TbaOffTrgSetup" 2 "TbaSetup" 1 "TbaActive" 0 "Inactive" ;
VAL_ 1079 PoliceAux4Swtch_B_Stat_UB 1 "Fresh_data" 0 "Unchanged_data" ;
VAL_ 1079 PoliceAux3Swtch_B_Stat_UB 1 "Fresh_data" 0 "Unchanged_data" ;
VAL_ 1079 PoliceAux2Swtch_B_Stat_UB 1 "Fresh_data" 0 "Unchanged_data" ;
VAL_ 1079 PoliceAux1Swtch_B_Stat_UB 1 "Fresh_data" 0 "Unchanged_data" ;
VAL_ 1079 PoliceAux4Swtch_B_Stat 1 "Switch_Active" 0 "Switch_Not_Active" ;
VAL_ 1079 PoliceAux3Swtch_B_Stat 1 "Switch_Active" 0 "Switch_Not_Active" ;
VAL_ 1079 PoliceAux2Swtch_B_Stat 1 "Switch_Active" 0 "Switch_Not_Active" ;
VAL_ 1079 PoliceAux1Swtch_B_Stat 1 "Switch_Active" 0 "Switch_Not_Active" ;
VAL_ 1079 GenericSwtch3_No_Actl_UB 1 "Fresh_data" 0 "Unchanged_data" ;
VAL_ 1079 GenericSwtch2_No_Actl_UB 1 "Fresh_data" 0 "Unchanged_data" ;
VAL_ 1079 GenericSwtch1_No_Actl_UB 1 "Fresh_data" 0 "Unchanged_data" ;
VAL_ 1079 RbaSys_D_Stat_UB 1 "Fresh_data" 0 "Unchanged_data" ;
VAL_ 1079 RbaSys_D_Stat 3 "Faulty" 2 "Available" 1 "Suspended" 0 "Disabled" ;
VAL_ 1079 HybMdeStat_D_Dsply_UB 1 "Fresh_data" 0 "Unchanged_data" ;
VAL_ 1079 Rba_D_Stat 3 "NotUsed" 2 "Disabled" 1 "On" 0 "Off" ;
VAL_ 1079 Rba_D_Stat_UB 1 "Fresh_data" 0 "Unchanged_data" ;
VAL_ 1079 BalrMde_D_Rq_UB 1 "Fresh_data" 0 "Unchanged_data" ;
VAL_ 1079 BalrSwtch_D_Stat_UB 1 "Fresh_data" 0 "Unchanged_data" ;
VAL_ 1079 BalrMde_D_Rq 3 "High" 2 "Medium" 1 "Low" 0 "Null" ;
VAL_ 1079 ChrgGoTTouchEnbl_B_Rq 1 "Request" 0 "NoRequest" ;
VAL_ 1079 ChrgGoTExtHtrEnbl_B_Rq 1 "Request" 0 "NoRequest" ;
VAL_ 1079 ChrgGoTTouchEnbl_B_Rq_UB 1 "Fresh_data" 0 "Unchanged_data" ;
VAL_ 1079 ChrgGoTExtHtrEnbl_B_Rq_UB 1 "Fresh_data" 0 "Unchanged_data" ;
VAL_ 1079 LcwaAlrtRight_B_Rq_UB 1 "Fresh_data" 0 "Unchanged_data" ;
VAL_ 1079 LcwaAlrtLeft_B_Rq_UB 1 "Fresh_data" 0 "Unchanged_data" ;
VAL_ 1079 LcwaAlrtRight_B_Rq 1 "Yes" 0 "No" ;
VAL_ 1079 LcwaAlrtLeft_B_Rq 1 "Yes" 0 "No" ;
VAL_ 1079 ApaSteScanMde_D_Stat 3 "Steering" 2 "Scanning" 1 "NotScanning" 0 "Null" ;
VAL_ 1079 ApaSteScanMde_D_Stat_UB 1 "Fresh_data" 0 "Unchanged_data" ;
VAL_ 1079 BattTracClimtDis_B_Stat_UB 1 "Fresh_data" 0 "Unchanged_data" ;
VAL_ 1079 BattTracClimtDis_B_Stat 1 "Enable" 0 "Disable" ;
VAL_ 1079 BalrSwtch_D_Stat 3 "NotUsed" 2 "Pressed" 1 "NotPressed" 0 "Null" ;
VAL_ 1079 TrlrAidMsgTxt_D2_Rq_UB 1 "Fresh_data" 0 "Unchanged_data" ;
VAL_ 1079 TrlrAidMsgTxt_D2_Rq 63 "Message63" 62 "Message62" 61 "Message61" 60 "Message60" 55 "Message55" 50 "Message50" 45 "Message45" 40 "Message40" 35 "Message35" 31 "Message31" 30 "Message30" 29 "Message29" 28 "Message28" 27 "Message27" 26 "Message26" 25 "Message25" 24 "Message24" 23 "Message23" 22 "Message22" 21 "Message21" 20 "Message20" 19 "Message19" 18 "Message18" 17 "Message17" 16 "Message16" 15 "Message15" 14 "Message14" 13 "Message13" 12 "Message12" 11 "Message11" 10 "Message10" 9 "Message9" 8 "Message8" 7 "Message7" 6 "Message6" 5 "Message5" 4 "Message4" 3 "Message3" 2 "Message2" 1 "Message1" 0 "NoMessage" ;
VAL_ 1079 HybMdeStat_D_Dsply 7 "NotUsed2" 6 "EV_Charge" 5 "EV_Override" 4 "Forced_EV_Mode" 3 "Forced_Charge_Sustain_Mode" 2 "Auto_Charge_Sustain_Mode" 1 "Auto_Charge_Deplete_Mode" 0 "Null_State" ;
VAL_ 1095 Pers4Phone_D_Stat 7 "SevenPhoneAssociated" 6 "SixPhoneAssociated" 5 "FivePhoneAssociated" 4 "FourPhoneAssociated" 3 "ThreePhoneAssociated" 2 "TwoPhoneAssociated" 1 "OnePhoneAssociated" 0 "NoPhoneAssociated" ;
VAL_ 1095 Pers3Phone_D_Stat 7 "SevenPhoneAssociated" 6 "SixPhoneAssociated" 5 "FivePhoneAssociated" 4 "FourPhoneAssociated" 3 "ThreePhoneAssociated" 2 "TwoPhoneAssociated" 1 "OnePhoneAssociated" 0 "NoPhoneAssociated" ;
VAL_ 1095 Pers2Phone_D_Stat 7 "SevenPhoneAssociated" 6 "SixPhoneAssociated" 5 "FivePhoneAssociated" 4 "FourPhoneAssociated" 3 "ThreePhoneAssociated" 2 "TwoPhoneAssociated" 1 "OnePhoneAssociated" 0 "NoPhoneAssociated" ;
VAL_ 1095 Pers1Phone_D_Stat 7 "SevenPhoneAssociated" 6 "SixPhoneAssociated" 5 "FivePhoneAssociated" 4 "FourPhoneAssociated" 3 "ThreePhoneAssociated" 2 "TwoPhoneAssociated" 1 "OnePhoneAssociated" 0 "NoPhoneAssociated" ;
VAL_ 1095 HeadLghtOn_D_Rq 7 "NotUsed2" 6 "NotUsed1" 5 "DrlBoth" 4 "DrlRight" 3 "DrlLeft" 2 "High" 1 "Low" 0 "Off" ;
VAL_ 1095 PepsKeyActv_D_Stat 15 "NotUsed11" 14 "NotUsed10" 13 "NotUsed9" 12 "NotUsed8" 11 "NotUsed7" 10 "NotUsed6" 9 "NotUsed5" 8 "Key4Active" 7 "NotUsed4" 6 "NotUsed3" 5 "NotUsed2" 4 "Key3Active" 3 "NotUsed1" 2 "Key2Active" 1 "Key1Active" 0 "NoKeyActive" ;
VAL_ 1095 VehLck_D_Dsply 3 "Faulty" 2 "Unlock" 1 "Lock" 0 "Off" ;
VAL_ 948 TlghtTestPrecnd_D2_Stat 7 "TrailerNotConnected" 6 "NotStationary" 5 "InteractionPresent" 4 "PreconditionsPassed" 3 "BattSocLessThan75Percent" 2 "TailLightsOn" 1 "IgnitionNotOn" 0 "Null" ;
VAL_ 948 TlghtTestLght_D2_Stat 7 "TestingRearFogLights" 6 "AllOff" 5 "TestingReverseLights" 4 "TestingBrakeLights" 3 "TestingLeftTurnSignal" 2 "TestingRightTurnSignal" 1 "ParkingLightsIlluminated" 0 "Null" ;
VAL_ 948 Tire_Press_ILR_Stat 4 "Alert" 15 "Not_Supported" 3 "Fault" 2 "Low" 1 "Normal" 0 "Unknown" ;
VAL_ 948 Tire_Press_IRR_Stat 4 "Alert" 15 "Not_Supported" 3 "Fault" 2 "Low" 1 "Normal" 0 "Unknown" ;
VAL_ 948 Tire_Press_LR_OLR_Stat 4 "Alert" 15 "Not_Supported" 3 "Fault" 2 "Low" 1 "Normal" 0 "Unknown" ;
VAL_ 948 Tire_Press_RR_ORR_Stat 4 "Alert" 15 "Not_Supported" 3 "Fault" 2 "Low" 1 "Normal" 0 "Unknown" ;
VAL_ 948 Tire_Press_RF_Stat 4 "Alert" 15 "Not_Supported" 3 "Fault" 2 "Low" 1 "Normal" 0 "Unknown" ;
VAL_ 948 Tire_Press_LF_Stat 4 "Alert" 15 "Not_Supported" 3 "Fault" 2 "Low" 1 "Normal" 0 "Unknown" ;
VAL_ 948 Tire_Press_System_Stat 13 "Training_Complete" 12 "Train_InsideLeftRear_tire" 11 "Train_OutsideLeftRear_tire" 10 "Train_LeftRear_tire" 9 "Train_InsideRtRear_tire" 8 "Train_OutsideRtRear_tire" 7 "Train_RightRear_tire" 14 "Tires_not_trained" 6 "Train_RightFront_tire" 5 "Train_LeftFront_tire" 4 "Systm_Activ_Composite_Stat" 3 "Low_Composite_Stat" 2 "Sensr_Fault_Composite_Stat" 1 "Systm_Fault_Composite_Stat" 0 "Unknown_Composite_Stat" ;
VAL_ 948 Tire_Press_Telltale 3 "Not_Used" 2 "Flash" 1 "On" 0 "Off" ;
VAL_ 948 TirePReset_D_Stat 3 "Not_Used" 2 "Nack" 1 "Ack" 0 "Null" ;
VAL_ 840 FohAddHeater_D_Rq 3 "NotUsed" 2 "On" 1 "Off" 0 "NoModeSelected" ;
VAL_ 840 FohT2Friday_T_Rq 1 "Enable" 0 "Disable" ;
VAL_ 840 FohT1Friday_T_Rq 1 "Enable" 0 "Disable" ;
VAL_ 840 FohT2Wednesday_T_Rq 1 "Enable" 0 "Disable" ;
VAL_ 840 FohT2Tuesday_T_Rq 1 "Enable" 0 "Disable" ;
VAL_ 840 FohT2Thursday_T_Rq 1 "Enable" 0 "Disable" ;
VAL_ 840 FohT2Sunday_T_Rq 1 "Enable" 0 "Disable" ;
VAL_ 840 FohT2Saturday_T_Rq 1 "Enable" 0 "Disable" ;
VAL_ 840 FohT2Monday_T_Rq 1 "Enable" 0 "Disable" ;
VAL_ 840 FohT1Wednesday_T_Rq 1 "Enable" 0 "Disable" ;
VAL_ 840 FohT1Tuesday_T_Rq 1 "Enable" 0 "Disable" ;
VAL_ 840 FohT1Thursday_T_Rq 1 "Enable" 0 "Disable" ;
VAL_ 840 FohT1Sunday_T_Rq 1 "Enable" 0 "Disable" ;
VAL_ 840 FohT1Saturday_T_Rq 1 "Enable" 0 "Disable" ;
VAL_ 840 FohT1Monday_T_Rq 1 "Enable" 0 "Disable" ;
VAL_ 945 PrkLckCtlMsgTxt_D2_Rq 7 "Message7" 6 "Message6" 5 "Message5" 4 "Message4" 3 "Message3" 2 "Message2" 1 "Message1" 0 "NoMessage" ;
VAL_ 945 KeyPadCodeDgt7_D_Dsply 15 "NotUsed_4" 14 "NotUsed_3" 13 "NotUsed_2" 12 "NotUsed_1" 11 "Button7_8and9_0" 10 "Button0" 9 "Button9_0or9" 8 "Button8" 7 "Button7_8or7" 6 "Button6" 5 "Button5_6or5" 4 "Button4" 3 "Button3_4or3" 2 "Button2" 1 "Button1_2or1" 0 "EndofString" ;
VAL_ 945 KeyPadCodeDgt6_D_Dsply 15 "NotUsed_4" 14 "NotUsed_3" 13 "NotUsed_2" 12 "NotUsed_1" 11 "Button7_8and9_0" 10 "Button0" 9 "Button9_0or9" 8 "Button8" 7 "Button7_8or7" 6 "Button6" 5 "Button5_6or5" 4 "Button4" 3 "Button3_4or3" 2 "Button2" 1 "Button1_2or1" 0 "EndofString" ;
VAL_ 945 KeyPadCodeDgt5_D_Dsply 15 "NotUsed_4" 14 "NotUsed_3" 13 "NotUsed_2" 12 "NotUsed_1" 11 "Button7_8and9_0" 10 "Button0" 9 "Button9_0or9" 8 "Button8" 7 "Button7_8or7" 6 "Button6" 5 "Button5_6or5" 4 "Button4" 3 "Button3_4or3" 2 "Button2" 1 "Button1_2or1" 0 "EndofString" ;
VAL_ 945 KeyPadCodeDgt4_D_Dsply 15 "NotUsed_4" 14 "NotUsed_3" 13 "NotUsed_2" 12 "NotUsed_1" 11 "Button7_8and9_0" 10 "Button0" 9 "Button9_0or9" 8 "Button8" 7 "Button7_8or7" 6 "Button6" 5 "Button5_6or5" 4 "Button4" 3 "Button3_4or3" 2 "Button2" 1 "Button1_2or1" 0 "EndofString" ;
VAL_ 945 KeyPadCodeDgt3_D_Dsply 15 "NotUsed_4" 14 "NotUsed_3" 13 "NotUsed_2" 12 "NotUsed_1" 11 "Button7_8and9_0" 10 "Button0" 9 "Button9_0or9" 8 "Button8" 7 "Button7_8or7" 6 "Button6" 5 "Button5_6or5" 4 "Button4" 3 "Button3_4or3" 2 "Button2" 1 "Button1_2or1" 0 "EndofString" ;
VAL_ 945 KeyPadCodeDgt2_D_Dsply 15 "NotUsed_4" 14 "NotUsed_3" 13 "NotUsed_2" 12 "NotUsed_1" 11 "Button7_8and9_0" 10 "Button0" 9 "Button9_0or9" 8 "Button8" 7 "Button7_8or7" 6 "Button6" 5 "Button5_6or5" 4 "Button4" 3 "Button3_4or3" 2 "Button2" 1 "Button1_2or1" 0 "EndofString" ;
VAL_ 945 KeyPadCodeDgt1_D_Dsply 15 "NotUsed_4" 14 "NotUsed_3" 13 "NotUsed_2" 12 "NotUsed_1" 11 "Button7_8and9_0" 10 "Button0" 9 "Button9_0or9" 8 "Button8" 7 "Button7_8or7" 6 "Button6" 5 "Button5_6or5" 4 "Button4" 3 "Button3_4or3" 2 "Button2" 1 "Button1_2or1" 0 "EndofString" ;
VAL_ 945 KeyOffMde_D_Actl 15 "NotUsed_11" 14 "NotUsed_10" 13 "NotUsed_9" 12 "NotUsed_8" 11 "NotUsed_7" 10 "NotUsed_6" 9 "NotUsed_5" 8 "NotUsed_4" 7 "NotUsed_3" 6 "NotUsed_2" 5 "NotUsed_1" 4 "CriticalBattery" 3 "Hibernate" 2 "Transport" 1 "Factory" 0 "Normal" ;
VAL_ 945 PrkLckCtlLatch_B_Rq 1 "On" 0 "Off" ;
VAL_ 981 PreCondActv_B_Actl_UB 1 "Fresh_data" 0 "Unchanged_data" ;
VAL_ 981 HvacPrecondRecirc_D_Rq_UB 1 "Fresh_data" 0 "Unchanged_data" ;
VAL_ 981 HvacPrecondMode2_D_Rq_UB 1 "Fresh_data" 0 "Unchanged_data" ;
VAL_ 981 HvacPrecondBlwr2_D_Rq_UB 1 "Fresh_data" 0 "Unchanged_data" ;
VAL_ 981 HvacPrecondAC_D_Rq_UB 1 "Fresh_data" 0 "Unchanged_data" ;
VAL_ 981 HvacPrecond_Te_Rq_UB 1 "Fresh_data" 0 "Unchanged_data" ;
VAL_ 981 DrvCondTpRrDefrs_B_Rq_UB 1 "Fresh_data" 0 "Unchanged_data" ;
VAL_ 981 PreCondActv_B_Actl 1 "On" 0 "Off" ;
VAL_ 981 HvacPrecondRecirc_D_Rq 3 "Last_User_Setting" 2 "Auto" 1 "Recirc" 0 "Outside" ;
VAL_ 981 HvacPrecondMode2_D_Rq 15 "NotUsed4" 14 "NotUsed3" 13 "NotUsed2" 12 "NotUsed1" 11 "Last_User_Settings" 10 "Auto" 9 "Max_Defrost" 8 "Windshield_Panel_Floor" 7 "Windshield_Panel" 6 "Windshield" 5 "Windshield_Floor" 4 "Floor" 3 "Panel_Floor" 2 "Panel" 1 "MAX_AC" 0 "Off" ;
VAL_ 981 HvacPrecondBlwr2_D_Rq 15 "NotUsed6" 14 "NotUsed5" 13 "NotUsed4" 12 "NotUsed3" 11 "NotUsed2" 10 "NotUsed1" 9 "Last_User_Setting" 8 "Auto" 7 "Speed7" 6 "Speed6" 5 "Speed5" 4 "Speed4" 3 "Speed3" 2 "Speed2" 1 "Speed1" 0 "Off" ;
VAL_ 981 HvacPrecondAC_D_Rq 3 "Last_User_Setting" 2 "Auto" 1 "On" 0 "Off" ;
VAL_ 981 DrvCondTpRrDefrs_B_Rq 1 "On" 0 "Off" ;
VAL_ 839 FohStop_B_Stat 3 "Unknown" 2 "NotUsed" 1 "Enable" 0 "Disable" ;
VAL_ 839 FohMsgTxt_D_Rq 4 "BatteryNotFullyCharged" 3 "Exceed7DaysFromLastEngRun" 2 "AmbientTemperatureTooHigh" 1 "LowFuel" 0 "NoMessage" ;
VAL_ 839 FohKeyOff_B_Rq 1 "Enable" 0 "Disable" ;
VAL_ 839 FohEnbl_B_Rq 1 "Enable" 0 "Disable" ;
VAL_ 839 FohTAllEnable_B_Stat 3 "Unknown" 2 "NotUsed" 1 "Enable" 0 "Disable" ;
VAL_ 839 FohT2Enable_B_Stat 1 "Enable" 0 "Disable" ;
VAL_ 839 FohT1Enable_B_Stat 1 "Enable" 0 "Disable" ;
VAL_ 839 FohStrtEnable_B_Stat 1 "Enable" 0 "Disable" ;
VAL_ 839 FohContOn_B_Stat 3 "Unknown" 2 "NotUsed" 1 "Enable" 0 "Disable" ;
VAL_ 839 FohT2Wednesday_T_Stat 1 "Enable" 0 "Disable" ;
VAL_ 839 FohT2Tuesday_T_Stat 1 "Enable" 0 "Disable" ;
VAL_ 839 FohT2Thursday_T_Stat 1 "Enable" 0 "Disable" ;
VAL_ 839 FohT2Sunday_T_Stat 1 "Enable" 0 "Disable" ;
VAL_ 839 FohT2Saturday_T_Stat 1 "Enable" 0 "Disable" ;
VAL_ 839 FohT2Monday_T_Stat 1 "Enable" 0 "Disable" ;
VAL_ 839 FohT2Friday_T_Stat 1 "Enable" 0 "Disable" ;
VAL_ 839 FohT1Wednesday_T_Stat 1 "Enable" 0 "Disable" ;
VAL_ 839 FohT1Tuesday_T_Stat 1 "Enable" 0 "Disable" ;
VAL_ 839 FohT1Thursday_T_Stat 1 "Enable" 0 "Disable" ;
VAL_ 839 FohT1Sunday_T_Stat 1 "Enable" 0 "Disable" ;
VAL_ 839 FohT1Saturday_T_Stat 1 "Enable" 0 "Disable" ;
VAL_ 839 FohT1Monday_T_Stat 1 "Enable" 0 "Disable" ;
VAL_ 839 FohT1Friday_T_Stat 1 "Enable" 0 "Disable" ;
VAL_ 838 FohStrtDay_T_Rq 7 "Sunday" 6 "Saturday" 5 "Friday" 4 "Thursday" 3 "Wednesday" 2 "Tuesday" 1 "Monday" 0 "NotUsed" ;
VAL_ 838 FohStop_B_Rq 3 "Unknown" 2 "NotUsed" 1 "Enable" 0 "Disable" ;
VAL_ 838 FohTAllEnable_B_Rq 3 "Unknown" 2 "NotUsed" 1 "Enable" 0 "Disable" ;
VAL_ 838 FohT2Enable_B_Rq 1 "Enable" 0 "Disable" ;
VAL_ 838 FohT1Enable_B_Rq 1 "Enable" 0 "Disable" ;
VAL_ 838 FohStrtEnable_B_Rq 1 "Enable" 0 "Disable" ;
VAL_ 838 FohContOn_B_Rq 3 "Unknown" 2 "NotUsed" 1 "Enable" 0 "Disable" ;
VAL_ 850 SeatCshnPsgrRR_Pc_Actl 127 "Null" ;
VAL_ 850 SeatCshnPsgrRL_Pc_Actl 127 "Null" ;
VAL_ 850 SeatCshnPsgrFR_Pc_Actl 127 "Null" ;
VAL_ 850 SeatCshnPsgrFL_Pc_Actl 127 "Null" ;
VAL_ 850 SeatBlLoPsgr_Pc_Actl2 127 "Null" ;
VAL_ 849 SeatCshnDrvRR_Pc_Actl 127 "Null" ;
VAL_ 849 SeatCshnDrvRL_Pc_Actl 127 "Null" ;
VAL_ 849 SeatCshnDrvFR_Pc_Actl 127 "Null" ;
VAL_ 849 SeatCshnDrvFL_Pc_Actl 127 "Null" ;
VAL_ 846 SeatRelxPosDactv_B_Rq 1 "True" 0 "False" ;
VAL_ 846 SeatRelxPosActv_B_Rq 1 "True" 0 "False" ;
VAL_ 846 SeatRelxPosSet_D_Rq 3 "NotUsed" 2 "Active" 1 "Store" 0 "Inactive" ;
VAL_ 846 SeatMasgDrv_D_Rq 15 "NotUsed_10" 14 "NotUsed_9" 13 "NotUsed_8" 12 "NotUsed_7" 11 "NotUsed_6" 10 "Pattern10" 9 "Pattern9" 8 "Pattern8" 7 "Pattern7" 6 "Pattern6" 5 "Pattern5" 4 "Pattern4" 3 "Pattern3" 2 "Pattern2" 1 "Pattern1" 0 "Null" ;
VAL_ 846 SeatMasgPsngr_D_Rq 15 "NotUsed_10" 14 "NotUsed_9" 13 "NotUsed_8" 12 "NotUsed_7" 11 "NotUsed_6" 10 "Pattern10" 9 "Pattern9" 8 "Pattern8" 7 "Pattern7" 6 "Pattern6" 5 "Pattern5" 4 "Pattern4" 3 "Pattern3" 2 "Pattern2" 1 "Pattern1" 0 "Null" ;
VAL_ 846 SeatLmbr_D_Rq 15 "NotUsed_7" 14 "NotUsed_6" 13 "NotUsed_5" 12 "NotUsed_4" 11 "NotUsed_3" 10 "NotUsed_2" 9 "NotUsed_1" 8 "PassengerDown" 7 "PassengerUp" 6 "PassengerAft" 5 "PassengerFore" 4 "DriverDown" 3 "DriverUp" 2 "DriverAft" 1 "DriverFore" 0 "Null" ;
VAL_ 846 SeatFnChngPsgr2_D_Rq 15 "Faulty" 14 "NotUsed9" 13 "NotUsed8" 12 "NotUsed7" 11 "NotUsed6" 10 "High_2" 9 "Med_2" 8 "Low_2" 7 "Off_2" 6 "High" 5 "Low" 4 "Off" 3 "Decrease" 2 "Increase" 1 "NotUsed1" 0 "Inactive" ;
VAL_ 846 SeatFnChngDrv2_D_Rq 15 "Faulty" 14 "NotUsed9" 13 "NotUsed8" 12 "NotUsed7" 11 "NotUsed6" 10 "High_2" 9 "Med_2" 8 "Low_2" 7 "Off_2" 6 "High" 5 "Low" 4 "Off" 3 "Decrease" 2 "Increase" 1 "NotUsed1" 0 "Inactive" ;
VAL_ 846 SeatFnPsgr_D_Rq 7 "CushionMassage" 6 "LumbarMassage" 5 "UpperBolster" 4 "LowerBolster" 3 "UpperLumbar" 2 "MiddleLumbar" 1 "LowerLumbar" 0 "Inactive" ;
VAL_ 846 SeatFnDrv_D_Rq 7 "CushionMassage" 6 "LumbarMassage" 5 "UpperBolster" 4 "LowerBolster" 3 "UpperLumbar" 2 "MiddleLumbar" 1 "LowerLumbar" 0 "Inactive" ;
VAL_ 846 SeatFnDfaltPsgr_B_Rq 1 "Active" 0 "Inactive" ;
VAL_ 846 SeatFnDfaltDrv_B_Rq 1 "Active" 0 "Inactive" ;
VAL_ 846 SeatFnChngPsgr_D_Rq 2 "Decrease" 1 "Increase" 0 "Inactive" ;
VAL_ 846 SeatFnChngDrv_D_Rq 2 "Decrease" 1 "Increase" 0 "Inactive" ;
VAL_ 846 PsgrMemory_Rq 8 "Recall_4" 7 "Recall_3" 6 "Recall_2" 5 "Recall_1" 4 "Store_4" 3 "Store_3" 2 "Store_2" 1 "Store_1" 0 "Inactive" ;
VAL_ 845 SeatMasgPsngr_D_Stat 15 "NotUsed_10" 14 "NotUsed_9" 13 "NotUsed_8" 12 "NotUsed_7" 11 "NotUsed_6" 10 "Pattern10" 9 "Pattern9" 8 "Pattern8" 7 "Pattern7" 6 "Pattern6" 5 "Pattern5" 4 "Pattern4" 3 "Pattern3" 2 "Pattern2" 1 "Pattern1" 0 "Null" ;
VAL_ 845 SeatIntnsPsngr_D_Stat 7 "NotUsed_3" 6 "NotUsed_2" 5 "NotUsed_1" 4 "High" 3 "Medium" 2 "Low" 1 "Off" 0 "Null" ;
VAL_ 845 StmsLmbrPsgr_D_Stat 3 "High" 2 "Low" 1 "Off" 0 "Null" ;
VAL_ 845 StmsCshnPsgr_D_Stat 3 "High" 2 "Low" 1 "Off" 0 "Null" ;
VAL_ 845 SeatSwtchPsgr_B_Stat 1 "On" 0 "Off" ;
VAL_ 845 SeatPPsgr_B_Stat 1 "Updating" 0 "NotUpdating" ;
VAL_ 845 SeatFnPsgr_D_Stat 7 "CushionMassage" 6 "LumbarMassage" 5 "UpperBolster" 4 "LowerBolster" 3 "UpperLumbar" 2 "MiddleLumbar" 1 "LowerLumbar" 0 "Null" ;
VAL_ 845 PsgrMemFeedback_Rsp 8 "Recall_4" 7 "Recall_3" 6 "Recall_2" 5 "Recall_1" 4 "Store_4" 3 "Store_3" 2 "Store_2" 1 "Store_1" 0 "Inactive" ;
VAL_ 844 SeatMasgDrv_D_Stat 15 "NotUsed_10" 14 "NotUsed_9" 13 "NotUsed_8" 12 "NotUsed_7" 11 "NotUsed_6" 10 "Pattern10" 9 "Pattern9" 8 "Pattern8" 7 "Pattern7" 6 "Pattern6" 5 "Pattern5" 4 "Pattern4" 3 "Pattern3" 2 "Pattern2" 1 "Pattern1" 0 "Null" ;
VAL_ 844 SeatIntnsDrv_D_Stat 7 "NotUsed_3" 6 "NotUsed_2" 5 "NotUsed_1" 4 "High" 3 "Medium" 2 "Low" 1 "Off" 0 "Null" ;
VAL_ 844 StmsLmbrDrv_D_Stat 3 "High" 2 "Low" 1 "Off" 0 "Null" ;
VAL_ 844 StmsCshnDrv_D_Stat 3 "High" 2 "Low" 1 "Off" 0 "Null" ;
VAL_ 844 SeatSwtchDrv_B_Stat 1 "On" 0 "Off" ;
VAL_ 844 SeatFnDrv_D_Stat 7 "CushionMassage" 6 "LumbarMassage" 5 "UpperBolster" 4 "LowerBolster" 3 "UpperLumbar" 2 "MiddleLumbar" 1 "LowerLumbar" 0 "Null" ;
VAL_ 844 SeatPDrv_B_Stat 1 "Updating" 0 "NotUpdating" ;
VAL_ 843 SeatBlUpPsgr_Pc_Actl 127 "Null" ;
VAL_ 843 SeatBlLoPsgr_Pc_Actl 127 "Null" ;
VAL_ 842 SeatBlUpDrv_Pc_Actl 127 "Null" ;
VAL_ 842 SeatBlLoDrv_Pc_Actl 127 "Null" ;
VAL_ 958 ElCmprOverTe_D_Stat 3 "OverTempStop" 2 "OverTempWarning" 1 "Normal" 0 "Undefined" ;
VAL_ 958 ElCmprOverTe_D_Stat_UB 1 "Fresh_data" 0 "Unchanged_data" ;
VAL_ 958 EngOff_T_Actl 65535 "Invalid" ;
VAL_ 958 EngOff_T_Actl_UB 1 "Fresh_data" 0 "Unchanged_data" ;
VAL_ 958 StopStrtDrvMde_D_Indic_UB 1 "Fresh_data" 0 "Unchanged_data" ;
VAL_ 958 PrmtrAlrmEvnt_D_Stat 15 "Diag_Tamper" 14 "Trailer" 13 "Shock_Sensor" 12 "Post_Crash" 11 "Panic" 10 "Intrusion" 9 "Inclination" 8 "Ign_Tamper" 7 "LG_Door" 6 "Decklid" 5 "Hood" 4 "PR_Door" 3 "PF_Door" 2 "DR_Door" 1 "DF_Door" 0 "Null" ;
VAL_ 958 PrmtrAlrmEvnt_D_Stat_UB 1 "Fresh_data" 0 "Unchanged_data" ;
VAL_ 958 StopStrtDrvMde_D_Indic 3 "NotUsed" 2 "StartStop_IndirectDeselect" 1 "StopStart_Deselected" 0 "StopStart_Selected" ;
VAL_ 958 FuelLvl_Pc_Dsply_UB 1 "Fresh_data" 0 "Unchanged_data" ;
VAL_ 958 OdometerMasterValue_UB 1 "Fresh_data" 0 "Unchanged_data" ;
VAL_ 958 OdometerMasterValue 16777215 "Invalid" ;
VAL_ 827 LghtAmbIntns_D2_Sns 3 "Faulty" 2 "High" 1 "Medium" 0 "Low" ;
VAL_ 827 SteClmnSwtchTlt_D_Stat 3 "Unused" 2 "Down" 1 "Up" 0 "Null" ;
VAL_ 827 SteClmnSwtchTel_D_Stat 3 "Unused" 2 "Rearward" 1 "Forward" 0 "Null" ;
VAL_ 827 LghtAmbIntns_D_Sns 3 "Faulty" 2 "High" 1 "Low" 0 "Null" ;
VAL_ 902 Remote_Start_Req 3 "Not_Used" 2 "Remote_Cancel" 1 "Remote_Start" 0 "No_Request" ;
VAL_ 902 PrmtrAlrmWarn_B_Rq 1 "Active" 0 "Null" ;
VAL_ 902 PrmtrAlrmTrg_B_Rq 1 "Active" 0 "Null" ;
VAL_ 902 Panic_D_RqRsm 3 "NotUsed" 2 "On" 1 "Off" 0 "Null" ;
VAL_ 902 CellLock_D_RqRsm 7 "NotUsed3" 6 "NotUsed2" 5 "NotUsed1" 4 "TrunkRelPopGlassLgCargo" 3 "LockAllDoorsandTailgate" 2 "UnlockDriversDoor" 1 "UnlockAllDoorsandTailgate" 0 "NoRequest" ;
VAL_ 765 CcStat_D_Actl_UB 1 "Fresh_data" 0 "Unchanged_data" ;
VAL_ 765 CcStat_D_Actl 7 "Undefined_2" 6 "Undefined_1" 5 "Active" 4 "Active_Que_Assist" 3 "Standby" 2 "Standby_Denied" 1 "Denied" 0 "Off" ;
VAL_ 765 PrplTqMnSat_B_Actl_UB 1 "Fresh_data" 0 "Unchanged_data" ;
VAL_ 765 PrplTqMnSat_B_Actl 1 "Yes" 0 "No" ;
VAL_ 765 ClimtBlwrLim_B_Rq 1 "Request" 0 "NoRequest" ;
VAL_ 765 ClimtBlwrLim_B_Rq_UB 1 "Fresh_data" 0 "Unchanged_data" ;
VAL_ 765 TrlrBrkActCnnct_B_Actl_UB 1 "Fresh_data" 0 "Unchanged_data" ;
VAL_ 765 TrlrBrkActCnnct_B_Actl 1 "Yes" 0 "No" ;
VAL_ 765 EmPrflButtnAssoc_D_Rq 3 "NotUsed" 2 "ExitButtonAssociation" 1 "EnterButtonAssociation" 0 "Null" ;
VAL_ 765 EmPrflButtnAssoc_D_Rq_UB 1 "Fresh_data" 0 "Unchanged_data" ;
VAL_ 765 CamraFrntStat_D_Stat_UB 1 "Fresh_data" 0 "Unchanged_data" ;
VAL_ 765 CamraFrntStat_D_Stat 3 "No_Data_Present" 2 "NotUsed" 1 "On" 0 "Off" ;
VAL_ 765 AutoHoldSwMde_B_Ind_UB 1 "Fresh_data" 0 "Unchanged_data" ;
VAL_ 765 AutoHoldSwMde_B_Ind 1 "On" 0 "Off" ;
VAL_ 765 ValetMode_D_Stat_UB 1 "Fresh_data" 0 "Unchanged_data" ;
VAL_ 765 ValetMode_D_Stat 3 "NotUsed" 2 "On" 1 "Off" 0 "Null" ;
VAL_ 765 SteWhlHeat_D_Stat 15 "NotUsed6" 14 "NotUsed5" 13 "NotUsed4" 12 "NotUsed3" 11 "NotUsed2" 10 "NotUsed1" 9 "Reserved_3" 8 "Reserved_2" 7 "Reserved_1" 6 "Level_3_Heating" 5 "Level_3_Heating_LS" 4 "Level_2_Heating" 3 "Level_2_Heating_LS" 2 "Level_1_Heating" 1 "Level_1_Heating_LS" 0 "Off" ;
VAL_ 765 Running_Board_Cmd_UB 1 "Fresh_data" 0 "Unchanged_data" ;
VAL_ 765 Running_Board_Cmd 3 "Unused" 2 "Manually_Deployed" 1 "All_Enabled" 0 "All_Disabled" ;
VAL_ 765 Bezel_Beeps_Rq_UB 1 "Fresh_data" 0 "Unchanged_data" ;
VAL_ 765 Bezel_Beeps_Rq 0 "Inactive" 2 "Disable" 1 "Enable" ;
VAL_ 765 Diagnostic_Operation_Rq_UB 1 "Fresh_data" 0 "Unchanged_data" ;
VAL_ 765 Bezel_Diag_State_Rq_UB 1 "Fresh_data" 0 "Unchanged_data" ;
VAL_ 765 Bezel_Diag_Module_Rq_UB 1 "Fresh_data" 0 "Unchanged_data" ;
VAL_ 765 Diagnostic_Operation_Rq 7 "SignalStrength" 6 "SDARSESNNumber" 5 "SpeakerWalkAround" 4 "CalibrationPartNumber" 15 "Reserved" 3 "HardwarePartNumber" 2 "SoftwarePartNumber" 1 "GetAllBackgroundDiagRq" 0 "Inactive" ;
VAL_ 765 Bezel_Diag_State_Rq 1 "Active" 0 "Inactive" ;
VAL_ 765 Bezel_Diag_Module_Rq 15 "Reserved" 3 "EFP" 2 "DSP_AMP" 1 "AHU" 0 "Inactive" ;
VAL_ 765 HMI_HMIMode_St_UB 1 "Fresh_data" 0 "Unchanged_data" ;
VAL_ 765 HMI_HMIMode_St 7 "NotUsed2" 6 "NotUsed1" 5 "Load_Shed_Active" 0 "Invalid" 1 "OffMode" 2 "On" 3 "Phone" 4 "Climate" ;
VAL_ 765 Mc_VehUnitTempUsrSel_St_UB 1 "Fresh_data" 0 "Unchanged_data" ;
VAL_ 765 Mc_VehUnitTempUsrSel_St 0 "Temperature_deg_c" 1 "Temperature_deg_f" ;
VAL_ 765 PsngrFrntDetct_D_Actl_UB 1 "Fresh_data" 0 "Unchanged_data" ;
VAL_ 765 PsngrFrntDetct_D_Actl 3 "Unknown" 2 "Empty" 0 "Faulty" 1 "Occupied" ;
VAL_ 765 SteWhlHeat_D_Stat_UB 1 "Fresh_data" 0 "Unchanged_data" ;
VAL_ 765 PrkAidLamp_D_Rq 3 "Not_Used" 2 "Flash" 1 "On" 0 "Off" ;
VAL_ 765 PrkAidLamp_D_Rq_UB 1 "Fresh_data" 0 "Unchanged_data" ;
VAL_ 765 ParkDetect_Stat_UB 1 "Fresh_data" 0 "Unchanged_data" ;
VAL_ 765 ParkDetect_Stat 1 "Park" 0 "Not_Park" ;
VAL_ 765 Voice_Blower_Limit 1 "Request" 0 "NoRequest" ;
VAL_ 765 Voice_Blower_Limit_UB 1 "Fresh_data" 0 "Unchanged_data" ;
VAL_ 765 PwStep_D_DrvInhbt_UB 1 "Fresh_data" 0 "Unchanged_data" ;
VAL_ 765 PwStep_D_DrvInhbt 3 "NotUsed" 2 "DriveInhibitMalfunction" 1 "DriveInhibited" 0 "DriveNotInhibited" ;
VAL_ 556 Manual_Temp_Setting 31 "Full_Heat" 30 "Setting_30" 29 "Setting_29" 28 "Setting_28" 27 "Setting_27" 26 "Setting_26" 25 "Setting_25" 24 "Setting_24" 23 "Setting_23" 22 "Setting_22" 21 "Setting_21" 20 "Setting_20" 19 "Setting_19" 18 "Setting_18" 17 "Setting_17" 16 "Setting_16" 15 "Setting_15" 14 "Setting_14" 13 "Setting_13" 12 "Setting_12" 11 "Setting_11" 10 "Setting_10" 9 "Setting_9" 8 "Setting_8" 7 "Setting_7" 6 "Setting_6" 5 "Setting_5" 4 "Setting_4" 3 "Setting_3" 2 "Setting_2" 1 "Full_Cool" 0 "Off" ;
VAL_ 359 ElPw_D_Stat 7 "NotUsed_3" 6 "NotUsed_2" 5 "NotUsed_1" 4 "Fault_Limited" 3 "LV_Event_In_Progress" 2 "Not_Supported_Imminent" 1 "Supported" 0 "Not_Supported" ;
VAL_ 359 SnowPlowMde_B_Enbl 1 "Enable" 0 "Disable" ;
VAL_ 359 PrplWhlRgenMn_Tq_Actl 8191 "Faulty" ;
VAL_ 359 ElPw_D_StatStrtStop 15 "NotUsed6" 14 "NotUsed5" 13 "NotUsed4" 12 "NotUsed3" 11 "NotUsed2" 10 "NotUsed1" 9 "Supported_Level_4" 8 "Supported_Level_3" 7 "Supported_Level_2" 6 "Supported_Level_1" 5 "Limited_Support" 4 "Fault_Limited" 3 "LV_Event_in_Progress" 2 "Not_Supported_Imminent" 1 "Supported_All" 0 "Not_Supported" ;
VAL_ 359 PrplWhlTot2_Tq_Actl 65535 "Fault" 65534 "NoDataExists" ;
VAL_ 359 LscmbbDeny_B_ActlPrpl 1 "Denied" 0 "Allowed" ;
VAL_ 359 LscmbbEngTqMn_B_Actl 1 "Engine_Braking_Activated" 0 "Engine_Braking_Off" ;
VAL_ 359 TrnAinTq_D_Qf 3 "OK" 2 "Not_Within_Specifications" 1 "No_Data_Exists" 0 "Faulty" ;
VAL_ 359 PwPckTq_D_Stat 3 "PwPckOn_TqAvailable" 2 "StartInPrgrss_TqNotAvail" 1 "PwPckOn_TqNotAvailable" 0 "PwPckOff_TqNotAvailable" ;
VAL_ 359 Eng_D_Stat 3 "NotUsed" 2 "EngAutoStopped" 1 "EngOn" 0 "EngOff" ;
VAL_ 359 PlgActvArb_B_Actl 1 "On" 0 "Off" ;
VAL_ 131 VehOnSrc_D_Stat_UB 1 "Fresh_data" 0 "Unchanged_data" ;
VAL_ 131 VehOnSrc_D_Stat 15 "NotUsed_11" 14 "NotUsed_10" 13 "NotUsed_9" 12 "NotUsed_8" 11 "NotUsed_7" 10 "NotUsed_6" 9 "EsclRssd" 8 "AutonomousVehicle" 7 "SecureIdle" 6 "FleetVehicleInhibit" 5 "StolenVehicleInhibit" 4 "OverTheAir" 3 "RemoteParkAssist" 2 "RemoteStart" 1 "Manual" 0 "Off" ;
VAL_ 131 StePinCompAnEst_D_Qf 3 "OK" 2 "Degraded" 1 "No_Data_Exists" 0 "Faulty" ;
VAL_ 131 StePinComp_An_Est_UB 1 "Fresh_data" 0 "Unchanged_data" ;
VAL_ 131 VehLongComp_A_Actl_UB 1 "Fresh_data" 0 "Unchanged_data" ;
VAL_ 131 VehLatComp_A_Actl_UB 1 "Fresh_data" 0 "Unchanged_data" ;
VAL_ 131 VehLongComp_A_Actl 1023 "Fault" 1022 "NoDataExists" ;
VAL_ 131 VehLatComp_A_Actl 1023 "Fault" 1022 "NoDataExists" ;
VAL_ 131 VehYaw_W_Actl_UB 1 "Fresh_data" 0 "Unchanged_data" ;
VAL_ 131 VehYaw_W_Actl 65535 "Faulty" 65534 "NoDataExists" ;
VAL_ 990 PersIndexDdm_D_Actl 7 "Unused_3" 6 "Unused_2" 5 "Unused_1" 4 "Vehicle" 3 "PERS_4" 2 "PERS_3" 1 "PERS_2" 0 "PERS_1" ;
VAL_ 1003 TailLghtLoadMde_D_Stat 7 "Faulty" 6 "NotUsed_2" 5 "NotUsed_1" 4 "TailLightModeOverride" 3 "FalrModeActive" 2 "HitchLoadModeActive" 1 "PayloadModeActive" 0 "NoTailLightActive" ;
VAL_ 1003 Pers4Key_D_Stat 3 "NotUsed_1" 2 "KeyUnAssociated" 1 "KeyAssociated" 0 "Null" ;
VAL_ 1003 Pers3Key_D_Stat 3 "NotUsed_1" 2 "KeyUnAssociated" 1 "KeyAssociated" 0 "Null" ;
VAL_ 1003 Pers2Key_D_Stat 3 "NotUsed_1" 2 "KeyUnAssociated" 1 "KeyAssociated" 0 "Null" ;
VAL_ 1003 Pers1Key_D_Stat 3 "NotUsed_1" 2 "KeyUnAssociated" 1 "KeyAssociated" 0 "Null" ;
VAL_ 1003 EmPrflNo_D_Stat 7 "NotUsed_3" 6 "NotUsed_2" 5 "NotUsed_1" 4 "Pers4" 3 "Pers3" 2 "Pers2" 1 "Pers1" 0 "Null" ;
VAL_ 1003 EmPrflKeyAssoc_D_Stat 7 "WrongDevice" 6 "KeyAssociateFailed" 5 "KeyAssociateSuccess" 4 "KeyAlreadyInUse" 3 "KeyDisassociated" 2 "KeyAssociationExited" 1 "KeyAssociationEntered" 0 "Null" ;
VAL_ 1003 PersRecallSrc_D_Actl 7 "NotUsed_3" 6 "NotUsed_2" 5 "NotUsed_1" 4 "MemorySwitch" 3 "RemoteStart" 2 "KeyFob" 1 "CenterStack" 0 "Null" ;
VAL_ 1003 VehKeyActv_D_Stat 15 "NotUsed7" 14 "NotUsed6" 13 "NotUsed5" 12 "NotUsed4" 11 "NotUsed3" 10 "NotUsed2" 9 "NotUsed1" 8 "Key8Active" 7 "Key7Active" 6 "Key6Active" 5 "Key5Active" 4 "Key4Active" 3 "Key3Active" 2 "Key2Active" 1 "Key1Active" 0 "NoKeyActive" ;
VAL_ 1003 PersSetupRestr_D_Actl 3 "Non_Moveable_Person" 2 "Moveable_Person" 1 "Vehicle" 0 "Factory" ;
VAL_ 1003 PersSetupAccessCtrl 1 "Limited" 0 "Full" ;
VAL_ 1003 PersConflict_D_Actl 1 "Conflict" 0 "No_Conflict" ;
VAL_ 1003 AssocConfirm_D_Actl 0 "None" 7 "Associate" 6 "Keycode_Rejected" 5 "Keycode_Accepted" 4 "In_Progress" 3 "Erase" 2 "Duplicate" 1 "Disassociate" ;
VAL_ 1003 PersNo_D_Actl 7 "Unused_3" 6 "Unused_2" 5 "NotDetermined" 4 "Vehicle" 3 "PERS_4" 2 "PERS_3" 1 "PERS_2" 0 "PERS_1" ;
VAL_ 1003 PersNoPos_D_Actl 7 "Unused_3" 6 "Unused_2" 5 "Unused_1" 4 "Vehicle" 3 "PERS_4" 2 "PERS_3" 1 "PERS_2" 0 "PERS_1" ;
VAL_ 836 FohFalt_D_Stat 15 "NotUsed4" 14 "NotUsed3" 13 "NotUsed2" 12 "NotUsed1" 11 "FuelTypeDoesNotMatchFOH" 10 "Lifecycle_ModeNotSet" 9 "AuxElectricCoolantPumpInop" 8 "TimeDelayAvoidExcessCycl" 7 "Fuel_Level_OutofRange" 6 "External_Fault" 5 "Internal_Fault" 4 "Voltage_limitation" 3 "Impact_Event" 2 "CoolantTemp_OutofRange" 1 "AmbientTemp_OutofRange" 0 "No_Disable" ;
VAL_ 836 FohEnbl_B_RqDrv 1 "On" 0 "Off" ;
VAL_ 836 FohRqRun_B_Rq 1 "SubmitRequest_toRun" 0 "DoesNotSubmitRequest_toRun" ;
VAL_ 836 HvacPrecondMode_D_Rq 15 "NotUsed4" 14 "NotUsed3" 13 "NotUsed2" 12 "NotUsed1" 11 "Last_User_Settings" 10 "Auto" 9 "Max_Defrost" 8 "Windshield_Panel_Floor" 7 "Windshield_Panel" 6 "Windshield" 5 "Windshield_Floor" 4 "Floor" 3 "Panel_Floor" 2 "Panel" 1 "MAX_AC" 0 "Off" ;
VAL_ 836 HvacPrecondBlwr_D_Rq 15 "NotUsed6" 14 "NotUsed5" 13 "NotUsed4" 12 "NotUsed3" 11 "NotUsed2" 10 "NotUsed1" 9 "Last_User_Setting" 8 "Auto" 7 "Speed7" 6 "Speed6" 5 "Speed5" 4 "Speed4" 3 "Speed3" 2 "Speed2" 1 "Speed1" 0 "Off" ;
VAL_ 836 Foh_D_Stat 7 "Unused3" 6 "Unused2" 5 "Unused1" 4 "Stopping" 3 "Running" 2 "Starting" 1 "Prestart" 0 "Off" ;
VAL_ 836 EngClnt_Te_ActlFoh 255 "Fault" ;
VAL_ 819 WndwUpPsngrRear_D_Falt 3 "NotUsed" 2 "Fault" 1 "NoFault" 0 "Null" ;
VAL_ 819 WndwUpPsngrFront_D_Falt 3 "NotUsed" 2 "Fault" 1 "NoFault" 0 "Null" ;
VAL_ 819 DrPrsntPsngr_D_Stat 3 "Faulty" 2 "Present" 1 "NotPresent" 0 "NotDetermined" ;
VAL_ 819 DrPsngrMsgTxt_B_Rq 1 "Yes" 0 "No" ;
VAL_ 819 DrPrsntRearPsngr_D_Stat 3 "Faulty" 2 "Present" 1 "NotPresent" 0 "NotDetermined" ;
VAL_ 819 Memory_3_SwPsngr_Stat 1 "Pressed" 0 "Null" ;
VAL_ 819 Memory_2_SwPsngr_Stat 1 "Pressed" 0 "Null" ;
VAL_ 819 Memory_1_SwPsngr_Stat 1 "Pressed" 0 "Null" ;
VAL_ 819 BLISLEDStatPassSide 3 "Fault" 2 "Unused" 1 "On" 0 "Off" ;
VAL_ 819 WndwPsngrSide_D_Stat 3 "BothWindow_Operating" 2 "RearWindow_Operating" 1 "FrontWindow_Operating" 0 "NoWindows_Operating" ;
VAL_ 819 Pasngr_Lock_Sw_Stat 3 "Invalid" 2 "Unlock" 1 "Lock" 0 "Null" ;
VAL_ 819 ChildLckFdbckRp_B_Stat 1 "Locked" 0 "Unlock" ;
VAL_ 818 WndwUpDrvRear_D_Falt 3 "NotUsed" 2 "Fault" 1 "NoFault" 0 "Null" ;
VAL_ 818 WndwUpDrvFront_D_Falt 3 "NotUsed" 2 "Fault" 1 "NoFault" 0 "Null" ;
VAL_ 818 DrvSpotLight_B_Stat 1 "Active" 0 "Inactive" ;
VAL_ 818 DrPrsntDrv_D_Stat 3 "Faulty" 2 "Present" 1 "NotPresent" 0 "NotDetermined" ;
VAL_ 818 DrPrsntRearDrv_D_Stat 3 "Faulty" 2 "Present" 1 "NotPresent" 0 "NotDetermined" ;
VAL_ 818 DrDrvMsgTxt_B_Rq 1 "Yes" 0 "No" ;
VAL_ 818 BLISLEDStatDriverSide 3 "Fault" 2 "Unused" 1 "On" 0 "Off" ;
VAL_ 818 WndwDrvSide_D_Stat 3 "BothWindow_Operating" 2 "RearWindow_Operating" 1 "FrontWindow_Operating" 0 "NoWindows_Operating" ;
VAL_ 818 KeyCylSwDrvDr_D_Stat 3 "NotUsed" 2 "Unlock" 1 "Lock" 0 "Null" ;
VAL_ 818 Driver_Lock_Sw_Stat 3 "Invalid" 2 "Unlock" 1 "Lock" 0 "Null" ;
VAL_ 818 ChildLckPw_D_Rq 1 "Active" 0 "Null" ;
VAL_ 818 ChildLckFdbckRd_B_Stat 1 "Locked" 0 "Unlock" ;
VAL_ 818 RvrseMirrorChime_B_Rq 1 "Yes" 0 "No" ;
VAL_ 817 ChildLckMde_B_Stat 1 "Enable" 0 "Disable" ;
VAL_ 817 VehLckInd_D_Rq 3 "NotUsed" 2 "On_Day" 1 "On_Night" 0 "Off" ;
VAL_ 817 DrTgateOpen_B_Rq 1 "Open" 0 "Null" ;
VAL_ 817 DrTgateExtSwMde_B_Stat 1 "Enable" 0 "Disable" ;
VAL_ 817 Remote_Device_Feedback 7 "Unused3" 6 "Unused2" 5 "Unused1" 4 "Shutdown" 3 "Running" 2 "Starting" 1 "Acknowledge" 0 "Null" ;
VAL_ 817 R_Pwr_Sliding_Dr_Rqst 1 "Active" 0 "Null" ;
VAL_ 817 Power_Liftgate_Rqst 1 "Active" 0 "Null" ;
VAL_ 817 Power_Decklid_Rqst 1 "Active" 0 "Null" ;
VAL_ 817 L_Pwr_Sliding_Dr_Rqst 1 "Active" 0 "Null" ;
VAL_ 817 Veh_Lock_Requestor 31 "Walk_Away_Locking" 30 "Remote_Park_Assist" 29 "DoorsOffToOn_Smart_Unlock" 28 "Rgtm_Shutlock_Switch" 27 "Boundary_Alert" 26 "Transit_Vehicle_Relock" 25 "Transit_Cargo_Relock" 24 "Transit_Ajar_Lock" 23 "Diagnostics" 22 "Console_Lock" 21 "Child_Lock" 20 "Double_Lock" 19 "Passive_Pasenger" 18 "Passive_Driver" 17 "Slam_Lock_Protect" 16 "SYNC" 15 "Passport" 14 "Passive_Smart_Unlock" 13 "Autorelock" 12 "RemoteStart" 0 "Null" 1 "Autolock" 11 "Smart_Unlock" 10 "Sliding_Door" 9 "Passive" 8 "Remote" 7 "Programming" 6 "Powerslide" 5 "Keypad" 4 "Key_Cylinder" 3 "Interior" 2 "Auto_Unlock" ;
VAL_ 817 Veh_Lock_Sub_Id 15 "Unused7" 14 "Unused6" 13 "Unused5" 12 "Unused4" 11 "Unused3" 10 "Unused2" 9 "Unused1" 8 "Customer_8" 7 "Customer_7" 6 "Customer_6" 5 "Customer_5" 4 "Customer_4" 3 "Customer_3" 2 "Customer_2" 1 "Customer_1" 0 "Null" ;
VAL_ 817 ChildLck_D_Dsply 3 "NOT_SUPPORTED" 2 "ERROR" 1 "CHILD_UNLOCK" 0 "CHILD_LOCK" ;
VAL_ 817 WindowLockout_B_Stat 1 "Locked" 0 "Unlock" ;
VAL_ 817 Lockmsgtxt_D_Rq 7 "MSG7" 6 "MSG6" 5 "MSG5" 4 "MSG4" 3 "MSG3" 2 "MSG2" 1 "MSG1" 0 "NO_WARNING" ;
VAL_ 817 LockInhibit 1 "Inhibit" 0 "No_Inhibit" ;
VAL_ 817 Veh_Lock_Status 3 "UNLOCK_DRV" 2 "UNLOCK_ALL" 1 "LOCK_ALL" 0 "LOCK_DBL" ;
VAL_ 817 FobComm_D_Stat 3 "NotUsed" 2 "RemEngStartOK" 1 "RemEngStartFail" 0 "Null" ;
VAL_ 1091 ParkLampTrlrOut_B_Stat 1 "Out" 0 "Null" ;
VAL_ 1091 TowBarMsgTxt_D_Rq 7 "NotUsed3" 6 "NotUsed2" 5 "NotUsed1" 4 "TowBar_Ext_No_Trlr" 3 "Error_Dealer_Fix" 2 "Start_Engine_Swivel" 1 "Check_Tow_Bar" 0 "Null" ;
VAL_ 1091 TrlrLampCtl_D_Stat 3 "NotUsed" 2 "TrlrLampCnnctDrvFailure" 1 "TrlrLampNotCnnctDrvFailure" 0 "Null" ;
VAL_ 1091 TrlrBattChrg_D_Stat 3 "Reverse" 2 "Normal" 1 "Low" 0 "Null" ;
VAL_ 1091 StopLampTrlrOut_B_Stat 1 "Out" 0 "Null" ;
VAL_ 1091 TurnLampTrlrRr_B_Stat 1 "Out" 0 "Null" ;
VAL_ 1091 TurnLampTrlrRl_B_Stat 1 "Out" 0 "Null" ;
VAL_ 1091 TrlrLampCnnct_B_Actl 1 "Yes" 0 "No" ;
VAL_ 1066 BattULo_U_Actl_UB 1 "Fresh_data" 0 "Unchanged_data" ;
VAL_ 1066 BattULo_U_Actl 255 "Fault" ;
VAL_ 1066 PwSrcULo_I_Mx 255 "Fault" ;
VAL_ 1066 PwSrcULo_I_Actl 255 "Fault" ;
VAL_ 1066 PwSrcULo_I_Mx_UB 1 "Fresh_data" 0 "Unchanged_data" ;
VAL_ 1066 PwSrcULo_I_Actl_UB 1 "Fresh_data" 0 "Unchanged_data" ;
VAL_ 994 PersCtaSplitView_D_Rq 3 "EnabledFull" 2 "Enabled_180SwitchOnly" 1 "Disabled" 0 "Null" ;
VAL_ 994 Pers4OptIn_B_Stats 1 "OPTED_IN" 0 "NOT_OPTED_IN" ;
VAL_ 994 Pers3OptIn_B_Stats 1 "OPTED_IN" 0 "NOT_OPTED_IN" ;
VAL_ 994 Pers2OptIn_B_Stats 1 "OPTED_IN" 0 "NOT_OPTED_IN" ;
VAL_ 994 Pers1OptIn_B_Stats 1 "OPTED_IN" 0 "NOT_OPTED_IN" ;
VAL_ 994 CtrStkPersIndex_D_Actl 7 "Unused_3" 6 "Unused_2" 5 "Unused_1" 4 "Vehicle" 3 "PERS_4" 2 "PERS_3" 1 "PERS_2" 0 "PERS_1" ;
VAL_ 994 CtrStkDsplyOp_D_Rq 7 "Unused_2" 6 "Unused_1" 5 "Copy" 4 "Restore" 3 "Upload" 2 "Set" 1 "Query" 0 "Null" ;
VAL_ 994 PersStore_D_Rq 7 "Unused_2" 6 "Unused_1" 5 "Vehicle" 4 "PERS_4" 3 "PERS_3" 2 "PERS_2" 1 "PERS_1" 0 "Null" ;
